VERSION "Think City A306, DBC v2 rev 6 - agg@nvg.org - 2023-03-22"

NS_ :

BS_:
BU_: ZD VCU TPMS RESERVED_FRAMES RCM RAC PCU PAS ESP DiagnosticTester CHG CDCM BMS ABS EDL
BO_ 1091 VCU_Stored_SC_Errors: 8 VCU
   SG_ VCUStoredBeltWarningLightSC : 13|1@0+ (1,0) [0|1] "" Vector__XXX
   SG_ VCUStoredLowSOCSC : 0|1@0+ (1,0) [0|1] "" Vector__XXX
   SG_ VCUStoredRearSeatBuckle2LightSC : 26|1@0+ (1,0) [0|1] "" Vector__XXX
   SG_ VCUStoredReverseLightSC : 9|1@0+ (1,0) [0|1] "" Vector__XXX
   SG_ VCUStoredRadioMuteSC : 33|1@0+ (1,0) [0|1] "" Vector__XXX
   SG_ VCUStoredIllumOutputSC : 21|1@0+ (1,0) [0|1] "" Vector__XXX
   SG_ VCUStoredNeutralLightSC : 8|1@0+ (1,0) [0|1] "" Vector__XXX
   SG_ VCUStoredDriveEnableLightSC : 39|1@0+ (1,0) [0|1] "" Vector__XXX
   SG_ VCUStoredOvertempLightSC : 3|1@0+ (1,0) [0|1] "" Vector__XXX
   SG_ VCUStoredIndicationBarSupplySC : 18|1@0+ (1,0) [0|1] "" Vector__XXX
   SG_ VCUStoredPowerLimitLightSC : 5|1@0+ (1,0) [0|1] "" Vector__XXX
   SG_ VCUStoredTransceiverTXSC : 20|1@0+ (1,0) [0|1] "" Vector__XXX
   SG_ VCUStoredElHazardLightSC : 2|1@0+ (1,0) [0|1] "" Vector__XXX
   SG_ VCUStoredBrakeWarningLightSC : 38|1@0+ (1,0) [0|1] "" Vector__XXX
   SG_ VCUStoredEconomyGaugeSC : 36|1@0+ (1,0) [0|1] "" Vector__XXX
   SG_ VCUStoredTransceiverSupplySC : 32|1@0+ (1,0) [0|1] "" Vector__XXX
   SG_ VCUStoredDischargeRequestSC : 25|1@0+ (1,0) [0|1] "" Vector__XXX
   SG_ VCUStoredCrashLineSC : 17|1@0+ (1,0) [0|1] "" Vector__XXX
   SG_ VCUStoredABSWarningLightSC : 4|1@0+ (1,0) [0|1] "" Vector__XXX
   SG_ VCUStoredImmoLightSC : 19|1@0+ (1,0) [0|1] "" Vector__XXX
   SG_ VCUStoredDriveLightSC : 7|1@0+ (1,0) [0|1] "" Vector__XXX
   SG_ VCUStoredAuxBattLowLightSC : 11|1@0+ (1,0) [0|1] "" Vector__XXX
   SG_ VCUStoredChargeLightSC : 31|1@0+ (1,0) [0|1] "" Vector__XXX
   SG_ VCUStoredTPMSLightSC : 12|1@0+ (1,0) [0|1] "" Vector__XXX
   SG_ VCUStoredSpeedGaugeSC : 28|1@0+ (1,0) [0|1] "" Vector__XXX
   SG_ VCUStoredEconomyLightSC : 6|1@0+ (1,0) [0|1] "" Vector__XXX
   SG_ VCUStoredOnPlugLightSC : 30|1@0+ (1,0) [0|1] "" Vector__XXX
   SG_ VCUStoredChimeLineSC : 34|1@0+ (1,0) [0|1] "" Vector__XXX
   SG_ VCUStoredESPLightSC : 15|1@0+ (1,0) [0|1] "" Vector__XXX
   SG_ VCUStoredSOCGaugeSC : 37|1@0+ (1,0) [0|1] "" Vector__XXX
   SG_ VCUStoredMILLightSC : 1|1@0+ (1,0) [0|1] "" Vector__XXX
   SG_ VCUStoredParkLightSC : 10|1@0+ (1,0) [0|1] "" Vector__XXX
   SG_ VCUStoredAirbagLightSC : 29|1@0+ (1,0) [0|1] "" Vector__XXX
   SG_ VCUStoredIgnitionSpeedSC : 16|1@0+ (1,0) [0|1] "" Vector__XXX
   SG_ VCUStoredRearSeatBuckle1LightSC : 27|1@0+ (1,0) [0|1] "" Vector__XXX

BO_ 1092 VCU_Stored_OC_Errors: 8 VCU
   SG_ VCUStoredImmoLightOC : 19|1@0+ (1,0) [0|1] "" Vector__XXX
   SG_ VCUStoredReverseLightOC : 9|1@0+ (1,0) [0|1] "" Vector__XXX
   SG_ VCUStoredDischargeRequestOC : 25|1@0+ (1,0) [0|1] "" Vector__XXX
   SG_ VCUStoredPowerLimitLightOC : 5|1@0+ (1,0) [0|1] "" Vector__XXX
   SG_ VCUStoredRearSeatBuckle1LightOC : 27|1@0+ (1,0) [0|1] "" Vector__XXX
   SG_ VCUStoredTPMSLightOC : 12|1@0+ (1,0) [0|1] "" Vector__XXX
   SG_ VCUStoredOvertempLightOC : 3|1@0+ (1,0) [0|1] "" Vector__XXX
   SG_ VCUStoredSOCGaugeOC : 37|1@0+ (1,0) [0|1] "" Vector__XXX
   SG_ VCUStoredESPLightOC : 15|1@0+ (1,0) [0|1] "" Vector__XXX
   SG_ VCUStoredCrashLineOC : 17|1@0+ (1,0) [0|1] "" Vector__XXX
   SG_ VCUStoredIndicationBarSupplyOC : 18|1@0+ (1,0) [0|1] "" Vector__XXX
   SG_ VCUStoredEconomyLightOC : 6|1@0+ (1,0) [0|1] "" Vector__XXX
   SG_ VCUStoredAirbagLightOC : 29|1@0+ (1,0) [0|1] "" Vector__XXX
   SG_ VCUStoredEconomyGaugeOC : 36|1@0+ (1,0) [0|1] "" Vector__XXX
   SG_ VCUStoredTransceiverSupplyOC : 32|1@0+ (1,0) [0|1] "" Vector__XXX
   SG_ VCUStoredDriveLightOC : 7|1@0+ (1,0) [0|1] "" Vector__XXX
   SG_ VCUStoredAuxBattLowLightOC : 11|1@0+ (1,0) [0|1] "" Vector__XXX
   SG_ VCUStoredRearSeatBuckle2LightOC : 26|1@0+ (1,0) [0|1] "" Vector__XXX
   SG_ VCUStoredIgnitionSpeedOC : 16|1@0+ (1,0) [0|1] "" Vector__XXX
   SG_ VCUStoredMILLightOC : 1|1@0+ (1,0) [0|1] "" Vector__XXX
   SG_ VCUStoredChimeLineOC : 34|1@0+ (1,0) [0|1] "" Vector__XXX
   SG_ VCUStoredDriveEnableLightOC : 39|1@0+ (1,0) [0|1] "" Vector__XXX
   SG_ VCUStoredLowSOCOC : 0|1@0+ (1,0) [0|1] "" Vector__XXX
   SG_ VCUStoredElHazardLightOC : 2|1@0+ (1,0) [0|1] "" Vector__XXX
   SG_ VCUStoredBrakeWarningLightOC : 38|1@0+ (1,0) [0|1] "" Vector__XXX
   SG_ VCUStoredIllumOutputOC : 21|1@0+ (1,0) [0|1] "" Vector__XXX
   SG_ VCUStoredABSWarningLightOC : 4|1@0+ (1,0) [0|1] "" Vector__XXX
   SG_ VCUStoredTransceiverTXOC : 20|1@0+ (1,0) [0|1] "" Vector__XXX
   SG_ VCUStoredBeltWarningLightOC : 13|1@0+ (1,0) [0|1] "" Vector__XXX
   SG_ VCUStoredSpeedGaugeOC : 28|1@0+ (1,0) [0|1] "" Vector__XXX
   SG_ VCUStoredRadioMuteOC : 33|1@0+ (1,0) [0|1] "" Vector__XXX
   SG_ VCUStoredParkLightOC : 10|1@0+ (1,0) [0|1] "" Vector__XXX
   SG_ VCUStoredNeutralLightOC : 8|1@0+ (1,0) [0|1] "" Vector__XXX
   SG_ VCUStoredChargeLightOC : 31|1@0+ (1,0) [0|1] "" Vector__XXX
   SG_ VCUStoredOnPlugLightOC : 30|1@0+ (1,0) [0|1] "" Vector__XXX

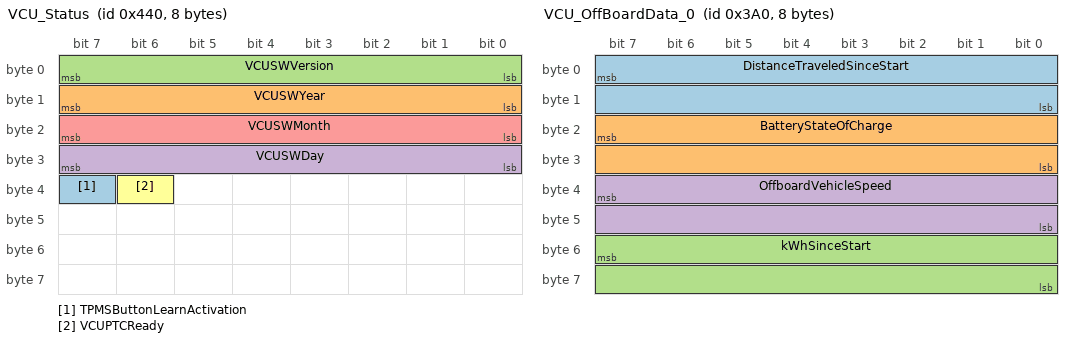
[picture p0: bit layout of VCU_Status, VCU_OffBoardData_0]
BO_ 1088 VCU_Status: 8 VCU
   SG_ TPMSButtonLearnActivation : 39|1@0+ (1,0) [0|1] "" Vector__XXX
   SG_ VCUSWYear : 15|8@0+ (1,0) [0|255] "" Vector__XXX
   SG_ VCUSWVersion : 7|8@0+ (1,0) [0|255] "" Vector__XXX
   SG_ VCUSWDay : 31|8@0+ (1,0) [0|255] "" Vector__XXX
   SG_ VCUSWMonth : 23|8@0+ (1,0) [0|255] "" Vector__XXX
   SG_ VCUPTCReady : 38|1@0+ (1,0) [0|1] "" Vector__XXX

BO_ 1089 VCU_Present_SC_Errors: 8 VCU
   SG_ VCUPresentMILLightSC : 1|1@0+ (1,0) [0|1] "" Vector__XXX
   SG_ VCUPresentImmoLightSC : 19|1@0+ (1,0) [0|1] "" Vector__XXX
   SG_ VCUPresentEconomyLightSC : 6|1@0+ (1,0) [0|1] "" Vector__XXX
   SG_ VCUPresentTransceiverSupplySC : 32|1@0+ (1,0) [0|1] "" Vector__XXX
   SG_ VCUPresentIgnitionSpeedSC : 16|1@0+ (1,0) [0|1] "" Vector__XXX
   SG_ VCUPresentChimeLineSC : 34|1@0+ (1,0) [0|1] "" Vector__XXX
   SG_ VCUPresentElHazardLightSC : 2|1@0+ (1,0) [0|1] "" Vector__XXX
   SG_ VCUPresentBrakeWarningLightSC : 38|1@0+ (1,0) [0|1] "" Vector__XXX
   SG_ VCUPresentRadioMuteSC : 33|1@0+ (1,0) [0|1] "" Vector__XXX
   SG_ VCUPresentSOCGaugeSC : 37|1@0+ (1,0) [0|1] "" Vector__XXX
   SG_ VCUPresentNeutralLightSC : 8|1@0+ (1,0) [0|1] "" Vector__XXX
   SG_ VCUPresentParkLightSC : 10|1@0+ (1,0) [0|1] "" Vector__XXX
   SG_ VCUPresentChargeLightSC : 31|1@0+ (1,0) [0|1] "" Vector__XXX
   SG_ VCUPresentEconomyGaugeSC : 36|1@0+ (1,0) [0|1] "" Vector__XXX
   SG_ VCUPresentCrashLineSC : 17|1@0+ (1,0) [0|1] "" Vector__XXX
   SG_ VCUPresentESPLightSC : 15|1@0+ (1,0) [0|1] "" Vector__XXX
   SG_ VCUPresentTransceiverTXSC : 20|1@0+ (1,0) [0|1] "" Vector__XXX
   SG_ VCUPresentReverseLightSC : 9|1@0+ (1,0) [0|1] "" Vector__XXX
   SG_ VCUPresentAirbagLightSC : 29|1@0+ (1,0) [0|1] "" Vector__XXX
   SG_ VCUPresentIndicationBarSupplySC : 18|1@0+ (1,0) [0|1] "" Vector__XXX
   SG_ VCUPresentDriveLightSC : 7|1@0+ (1,0) [0|1] "" Vector__XXX
   SG_ VCUPresentRearSeatBuckle1LightSC : 27|1@0+ (1,0) [0|1] "" Vector__XXX
   SG_ VCUPresentDischargeRequestSC : 25|1@0+ (1,0) [0|1] "" Vector__XXX
   SG_ VCUPresentAuxBattLowLightSC : 11|1@0+ (1,0) [0|1] "" Vector__XXX
   SG_ VCUPresentDriveEnableLightSC : 39|1@0+ (1,0) [0|1] "" Vector__XXX
   SG_ VCUPresentLowSOCSC : 0|1@0+ (1,0) [0|1] "" Vector__XXX
   SG_ VCUPresentBeltWarningLightSC : 13|1@0+ (1,0) [0|1] "" Vector__XXX
   SG_ VCUPresentSpeedGaugeSC : 28|1@0+ (1,0) [0|1] "" Vector__XXX
   SG_ VCUPresentABSWarningLightSC : 4|1@0+ (1,0) [0|1] "" Vector__XXX
   SG_ VCUPresentOvertempLightSC : 3|1@0+ (1,0) [0|1] "" Vector__XXX
   SG_ VCUPresentOnPlugLightSC : 30|1@0+ (1,0) [0|1] "" Vector__XXX
   SG_ VCUPresentIllumOutputSC : 21|1@0+ (1,0) [0|1] "" Vector__XXX
   SG_ VCUPresentPowerLimitLightSC : 5|1@0+ (1,0) [0|1] "" Vector__XXX
   SG_ VCUPresentTPMSLightSC : 12|1@0+ (1,0) [0|1] "" Vector__XXX
   SG_ VCUPresentRearSeatBuckle2LightSC : 26|1@0+ (1,0) [0|1] "" Vector__XXX

BO_ 1090 VCU_Present_OC_Errors: 8 VCU
   SG_ VCUPresentIndicationBarSupplyOC : 18|1@0+ (1,0) [0|1] "" Vector__XXX
   SG_ VCUPresentLowSOCOC : 0|1@0+ (1,0) [0|1] "" Vector__XXX
   SG_ VCUPresentOvertempLightOC : 3|1@0+ (1,0) [0|1] "" Vector__XXX
   SG_ VCUPresentEconomyLightOC : 6|1@0+ (1,0) [0|1] "" Vector__XXX
   SG_ VCUPresentParkLightOC : 10|1@0+ (1,0) [0|1] "" Vector__XXX
   SG_ VCUPresentRadioMuteOC : 33|1@0+ (1,0) [0|1] "" Vector__XXX
   SG_ VCUPresentElHazardLightOC : 2|1@0+ (1,0) [0|1] "" Vector__XXX
   SG_ VCUPresentBeltWarningLightOC : 13|1@0+ (1,0) [0|1] "" Vector__XXX
   SG_ VCUPresentDriveEnableLightOC : 39|1@0+ (1,0) [0|1] "" Vector__XXX
   SG_ VCUPresentImmoLightOC : 19|1@0+ (1,0) [0|1] "" Vector__XXX
   SG_ VCUPresentAirbagLightOC : 29|1@0+ (1,0) [0|1] "" Vector__XXX
   SG_ VCUPresentSOCGaugeOC : 37|1@0+ (1,0) [0|1] "" Vector__XXX
   SG_ VCUPresentSpeedGaugeOC : 28|1@0+ (1,0) [0|1] "" Vector__XXX
   SG_ VCUPresentRearSeatBuckle2LightOC : 26|1@0+ (1,0) [0|1] "" Vector__XXX
   SG_ VCUPresentReverseLightOC : 9|1@0+ (1,0) [0|1] "" Vector__XXX
   SG_ VCUPresentIllumOutputOC : 21|1@0+ (1,0) [0|1] "" Vector__XXX
   SG_ VCUPresentBrakeWarningLightOC : 38|1@0+ (1,0) [0|1] "" Vector__XXX
   SG_ VCUPresentTransceiverSupplyOC : 32|1@0+ (1,0) [0|1] "" Vector__XXX
   SG_ VCUPresentABSWarningLightOC : 4|1@0+ (1,0) [0|1] "" Vector__XXX
   SG_ VCUPresentTransceiverTXOC : 20|1@0+ (1,0) [0|1] "" Vector__XXX
   SG_ VCUPresentDriveLightOC : 7|1@0+ (1,0) [0|1] "" Vector__XXX
   SG_ VCUPresentPowerLimitLightOC : 5|1@0+ (1,0) [0|1] "" Vector__XXX
   SG_ VCUPresentCrashLineOC : 17|1@0+ (1,0) [0|1] "" Vector__XXX
   SG_ VCUPresentIgnitionSpeedOC : 16|1@0+ (1,0) [0|1] "" Vector__XXX
   SG_ VCUPresentAuxBattLowLightOC : 11|1@0+ (1,0) [0|1] "" Vector__XXX
   SG_ VCUPresentChargeLightOC : 31|1@0+ (1,0) [0|1] "" Vector__XXX
   SG_ VCUPresentOnPlugLightOC : 30|1@0+ (1,0) [0|1] "" Vector__XXX
   SG_ VCUPresentNeutralLightOC : 8|1@0+ (1,0) [0|1] "" Vector__XXX
   SG_ VCUPresentEconomyGaugeOC : 36|1@0+ (1,0) [0|1] "" Vector__XXX
   SG_ VCUPresentChimeLineOC : 34|1@0+ (1,0) [0|1] "" Vector__XXX
   SG_ VCUPresentRearSeatBuckle1LightOC : 27|1@0+ (1,0) [0|1] "" Vector__XXX
   SG_ VCUPresentESPLightOC : 15|1@0+ (1,0) [0|1] "" Vector__XXX
   SG_ VCUPresentTPMSLightOC : 12|1@0+ (1,0) [0|1] "" Vector__XXX
   SG_ VCUPresentDischargeRequestOC : 25|1@0+ (1,0) [0|1] "" Vector__XXX
   SG_ VCUPresentMILLightOC : 1|1@0+ (1,0) [0|1] "" Vector__XXX

BO_ 929 VCU_OffBoardData_1: 8 VCU
   SG_ WarningLightTemperatureActivated : 30|1@0+ (1,0) [0|1] "" Vector__XXX
   SG_ WarningLightAirbagActivated : 28|1@0+ (1,0) [0|1] "" Vector__XXX
   SG_ OnPlugBatteryTemperatureControl : 3|1@0+ (1,0) [0|1] "" Vector__XXX
   SG_ OnPlugPCUChargeEnabled : 15|1@0+ (1,0) [0|1] "" Vector__XXX
   SG_ KeyOnEPOBroken : 9|1@0+ (1,0) [0|1] "" Vector__XXX
   SG_ OnPlugFullChargeRequested : 14|1@0+ (1,0) [0|1] "" Vector__XXX
   SG_ WarningLightTPMSActivated : 20|1@0+ (1,0) [0|1] "" Vector__XXX
   SG_ KeyOnTractionEnabled : 13|1@0+ (1,0) [0|1] "" Vector__XXX
   SG_ WarningLightPowerLimitActivated : 19|1@0+ (1,0) [0|1] "" Vector__XXX
   SG_ KeyOnImmobilizerEnabled : 12|1@0+ (1,0) [0|1] "" Vector__XXX
   SG_ ExternalTemperature : 39|8@0- (0.5,0) [-64|63.5] "degC" Vector__XXX
   SG_ WarningLightESPActivated : 31|1@0+ (1,0) [0|1] "" Vector__XXX
   SG_ KeyOnGearPosition : 27|3@0+ (1,0) [0|7] "" Vector__XXX
   SG_ WarningLightMalfunctionActivated : 29|1@0+ (1,0) [0|1] "" Vector__XXX
   SG_ WarningLightBrakeActivated : 16|1@0+ (1,0) [0|1] "" Vector__XXX
   SG_ OnPlugEndOfCharge : 4|1@0+ (1,0) [0|1] "" Vector__XXX
   SG_ OnPlugBatteryChargeEnabled : 0|1@0+ (1,0) [0|1] "" Vector__XXX
   SG_ WarningLightABSActivated : 17|1@0+ (1,0) [0|1] "" Vector__XXX
   SG_ NominalBatteryCapacity : 47|16@0+ (0.1,0) [0|6553.5] "kWh" Vector__XXX
   SG_ WarningLightLowSOCActivated : 21|1@0+ (1,0) [0|1] "" Vector__XXX
   SG_ OnPlugCharging : 5|1@0+ (1,0) [0|1] "" Vector__XXX
   SG_ OnPlugBatteryEvaluation : 2|1@0+ (1,0) [0|1] "" Vector__XXX
   SG_ KeyOnCrashDetected : 10|1@0+ (1,0) [0|1] "" Vector__XXX
   SG_ KeyOnBatteryDischargeEnabled : 11|1@0+ (1,0) [0|1] "" Vector__XXX
   SG_ WarningLightElHazardActivated : 18|1@0+ (1,0) [0|1] "" Vector__XXX
   SG_ VehicleState : 7|2@0+ (1,0) [0|3] "" Vector__XXX
   SG_ OnPlugChargerEnabled : 1|1@0+ (1,0) [0|1] "" Vector__XXX

BO_ 928 VCU_OffBoardData_0: 8 VCU
   SG_ DistanceTraveledSinceStart : 7|16@0+ (0.1,0) [0|6553.5] "km" Vector__XXX
   SG_ BatteryStateOfCharge : 23|16@0+ (0.1,0) [0|6553.5] "%" Vector__XXX
   SG_ kWhSinceStart : 55|16@0+ (0.01,0) [0|655.35] "kWh" Vector__XXX
   SG_ OffboardVehicleSpeed : 39|16@0+ (0.1,0) [0|6553.5] "km/h" Vector__XXX

BO_ 592 VCU_Immo: 8 VCU
   SG_ MoreThanMaxError : 19|1@0+ (1,0) [0|1] "" PCU
   SG_ ChallengeResponseActive : 1|1@0+ (1,0) [0|1] "" PCU
   SG_ AntennaError : 17|1@0+ (1,0) [0|1] "" PCU
   SG_ TransponderError : 16|1@0+ (1,0) [0|1] "" PCU
   SG_ ChallengeMissingError : 27|1@0+ (1,0) [0|1] "" PCU
   SG_ PartialKeyCodeError : 31|1@0+ (1,0) [0|1] "" PCU
   SG_ RequestID : 2|1@0+ (1,0) [0|1] "" PCU
   SG_ AntiscanError : 20|1@0+ (1,0) [0|1] "" PCU
   SG_ MismatchError : 26|1@0+ (1,0) [0|1] "" PCU
   SG_ LEDIndication : 7|3@0+ (1,0) [0|7] "" PCU
   SG_ NoCommunicationError : 18|1@0+ (1,0) [0|1] "" PCU
   SG_ KeyStatus : 4|2@0+ (1,0) [0|3] "" PCU
   SG_ SecurityIDRefuseError : 25|1@0+ (1,0) [0|1] "" PCU
   SG_ LessThanMinError : 28|1@0+ (1,0) [0|1] "" PCU
   SG_ SecurityIDNotProgrammedError : 24|1@0+ (1,0) [0|1] "" PCU
   SG_ SecurityIDMissingError : 29|1@0+ (1,0) [0|1] "" PCU
   SG_ UnprogrammedError : 30|1@0+ (1,0) [0|1] "" PCU
   SG_ NumberProgrammedKeys : 23|3@0+ (1,0) [0|7] "" Vector__XXX
   SG_ ChallengeResponse : 39|32@0+ (1,0) [0|4.29497e+09] "" PCU

BO_ 2001 VCU_Diagnostic: 8 VCU

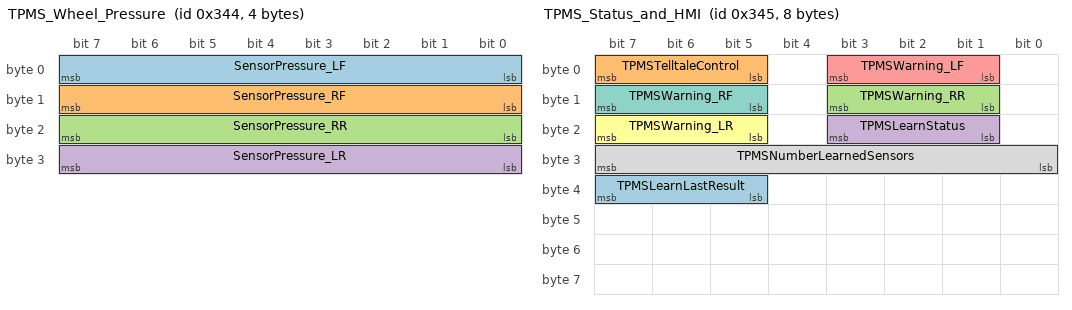
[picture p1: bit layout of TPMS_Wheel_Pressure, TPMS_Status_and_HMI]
BO_ 836 TPMS_Wheel_Pressure: 4 TPMS
   SG_ SensorPressure_LF : 7|8@0+ (0.025,0) [0|6.375] "bar" Vector__XXX
   SG_ SensorPressure_RF : 15|8@0+ (0.025,0) [0|6.375] "bar" Vector__XXX
   SG_ SensorPressure_RR : 23|8@0+ (0.025,0) [0|6.375] "bar" Vector__XXX
   SG_ SensorPressure_LR : 31|8@0+ (0.025,0) [0|6.375] "bar" Vector__XXX

BO_ 837 TPMS_Status_and_HMI: 8 TPMS
   SG_ TPMSLearnLastResult : 39|3@0+ (1,0) [0|7] "" Vector__XXX
   SG_ TPMSTelltaleControl : 7|3@0+ (1,0) [0|7] "" Vector__XXX
   SG_ TPMSWarning_RR : 11|3@0+ (1,0) [0|7] "" Vector__XXX
   SG_ TPMSLearnStatus : 19|3@0+ (1,0) [0|7] "" Vector__XXX
   SG_ TPMSWarning_LF : 3|3@0+ (1,0) [0|7] "" Vector__XXX
   SG_ TPMSWarning_LR : 23|3@0+ (1,0) [0|7] "" Vector__XXX
   SG_ TPMSWarning_RF : 15|3@0+ (1,0) [0|7] "" Vector__XXX
   SG_ TPMSNumberLearnedSensors : 31|8@0+ (1,0) [0|255] "" Vector__XXX

BO_ 1922 TPMS_Diagnostic: 8 TPMS

BO_ 838 TPMS_Debug: 8 TPMS

BO_ 1941 Reserver_104: 8 RESERVED_FRAMES

BO_ 1525 Reserved_99: 8 RESERVED_FRAMES

BO_ 1493 Reserved_98: 8 RESERVED_FRAMES

BO_ 1631 Reserved_97: 8 RESERVED_FRAMES

BO_ 1630 Reserved_96: 8 RESERVED_FRAMES

BO_ 1629 Reserved_95: 8 RESERVED_FRAMES

BO_ 1628 Reserved_94: 8 RESERVED_FRAMES

BO_ 1627 Reserved_93: 8 RESERVED_FRAMES

BO_ 1626 Reserved_92: 8 RESERVED_FRAMES

BO_ 1625 Reserved_91: 8 RESERVED_FRAMES

BO_ 1624 Reserved_90: 8 RESERVED_FRAMES

BO_ 1623 Reserved_89: 8 RESERVED_FRAMES

BO_ 1622 Reserved_88: 8 RESERVED_FRAMES

BO_ 1621 Reserved_87: 8 RESERVED_FRAMES

BO_ 1620 Reserved_86: 8 RESERVED_FRAMES

BO_ 1619 Reserved_85: 8 RESERVED_FRAMES

BO_ 1618 Reserved_84: 8 RESERVED_FRAMES

BO_ 1617 Reserved_83: 8 RESERVED_FRAMES

BO_ 1616 Reserved_82: 8 RESERVED_FRAMES

BO_ 1615 Reserved_81: 8 RESERVED_FRAMES

BO_ 1614 Reserved_80: 8 RESERVED_FRAMES

BO_ 645 Reserved_8: 8 RESERVED_FRAMES

BO_ 1613 Reserved_79: 8 RESERVED_FRAMES

BO_ 1612 Reserved_78: 8 RESERVED_FRAMES

BO_ 1611 Reserved_77: 8 RESERVED_FRAMES

BO_ 1610 Reserved_76: 8 RESERVED_FRAMES

BO_ 1609 Reserved_75: 8 RESERVED_FRAMES

BO_ 1608 Reserved_74: 8 ZD

BO_ 1607 Reserved_73: 8 RESERVED_FRAMES

BO_ 1606 Reserved_72: 8 BMS

BO_ 1605 Reserved_71: 8 RESERVED_FRAMES

BO_ 1604 Reserved_70: 8 BMS

BO_ 513 Reserved_7: 8 RESERVED_FRAMES

BO_ 1603 Reserved_69: 8 RESERVED_FRAMES

BO_ 1602 Reserved_68: 8 BMS

BO_ 1601 Reserved_67: 8 RESERVED_FRAMES

BO_ 1600 Reserved_66: 8 RESERVED_FRAMES

BO_ 1584 Reserved_65: 8 RESERVED_FRAMES

BO_ 831 Reserved_64: 8 RESERVED_FRAMES

BO_ 830 Reserved_63: 8 RESERVED_FRAMES

BO_ 829 Reserved_62: 8 RESERVED_FRAMES

BO_ 828 Reserved_61: 8 RESERVED_FRAMES

BO_ 827 Reserved_60: 8 RESERVED_FRAMES

BO_ 512 Reserved_6: 8 RESERVED_FRAMES

BO_ 826 Reserved_59: 8 RESERVED_FRAMES

BO_ 825 Reserved_58: 8 RESERVED_FRAMES

BO_ 824 Reserved_57: 8 RESERVED_FRAMES

BO_ 823 Reserved_56: 8 RESERVED_FRAMES

BO_ 822 Reserved_55: 8 RESERVED_FRAMES

BO_ 821 Reserved_54: 8 RESERVED_FRAMES

BO_ 820 Reserved_53: 8 RESERVED_FRAMES

BO_ 819 Reserved_52: 8 RESERVED_FRAMES

BO_ 818 Reserved_51: 8 RESERVED_FRAMES

BO_ 817 Reserved_50: 8 RESERVED_FRAMES

BO_ 1568 Reserved_5: 8 RESERVED_FRAMES

BO_ 816 Reserved_49: 8 RESERVED_FRAMES

BO_ 815 Reserved_48: 8 RESERVED_FRAMES

BO_ 814 Reserved_47: 8 RESERVED_FRAMES

BO_ 813 Reserved_46: 8 RESERVED_FRAMES

BO_ 812 Reserved_45: 8 RESERVED_FRAMES

BO_ 811 Reserved_44: 8 RESERVED_FRAMES

BO_ 810 Reserved_43: 8 RESERVED_FRAMES

BO_ 809 Reserved_42: 8 RESERVED_FRAMES

BO_ 808 Reserved_41: 8 RESERVED_FRAMES

BO_ 1892 Reserved_401: 8 RESERVED_FRAMES

BO_ 1888 Reserved_400: 8 RESERVED_FRAMES

BO_ 807 Reserved_40: 8 RESERVED_FRAMES

BO_ 1072 Reserved_4: 8 RESERVED_FRAMES

BO_ 1034 Reserved_399: 8 RESERVED_FRAMES

BO_ 1585 Reserved_398: 8 RESERVED_FRAMES

BO_ 1569 Reserved_397: 8 RESERVED_FRAMES

BO_ 857 Reserved_392: 8 RESERVED_FRAMES

BO_ 1567 Reserved_391: 8 RESERVED_FRAMES

BO_ 1566 Reserved_390: 8 RESERVED_FRAMES

BO_ 806 Reserved_39: 8 RESERVED_FRAMES

BO_ 1565 Reserved_389: 8 RESERVED_FRAMES

BO_ 1564 Reserved_388: 8 RESERVED_FRAMES

BO_ 1563 Reserved_387: 8 RESERVED_FRAMES

BO_ 1562 Reserved_386: 8 RESERVED_FRAMES

BO_ 1561 Reserved_385: 8 RESERVED_FRAMES

BO_ 1560 Reserved_384: 8 RESERVED_FRAMES

BO_ 1559 Reserved_383: 8 RESERVED_FRAMES

BO_ 1558 Reserved_382: 8 RESERVED_FRAMES

BO_ 1557 Reserved_381: 8 RESERVED_FRAMES

BO_ 1556 Reserved_380: 8 RESERVED_FRAMES

BO_ 805 Reserved_38: 8 RESERVED_FRAMES

BO_ 1555 Reserved_379: 8 RESERVED_FRAMES

BO_ 1554 Reserved_378: 8 RESERVED_FRAMES

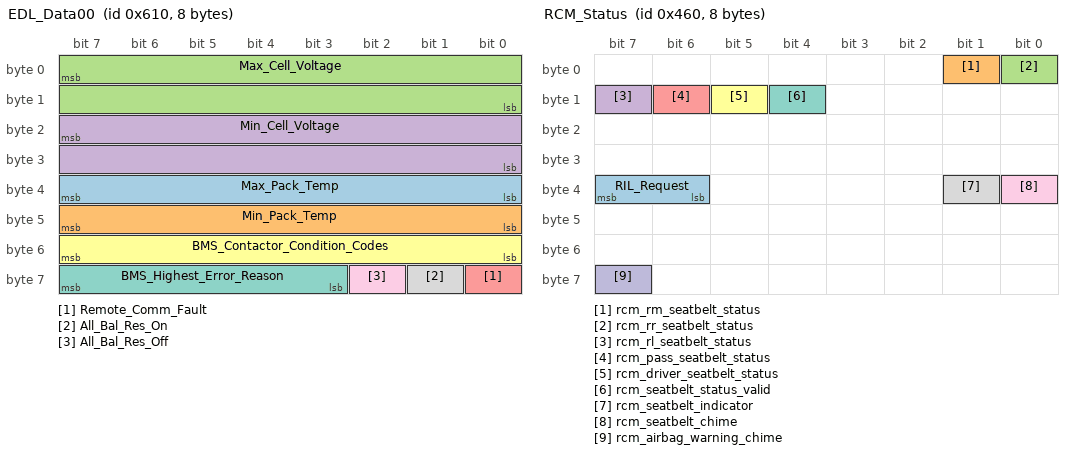
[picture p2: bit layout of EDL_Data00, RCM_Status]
BO_ 1552 EDL_Data00: 8 EDL
   SG_ Max_Pack_Temp : 39|8@0+ (1,0) [0|255] "_Celsius" Vector__XXX
   SG_ Min_Pack_Temp : 47|8@0+ (1,0) [0|255] "_Celsius" Vector__XXX
   SG_ Max_Cell_Voltage : 7|16@0+ (0.00244141,0) [0|1] "_Volts" Vector__XXX
   SG_ Min_Cell_Voltage : 23|16@0+ (0.00244141,0) [0|1] "_Volts" Vector__XXX
   SG_ Remote_Comm_Fault : 56|1@0+ (1,0) [0|1] "" Vector__XXX
   SG_ BMS_Contactor_Condition_Codes : 55|8@0+ (1,0) [0|256] "" Vector__XXX
   SG_ BMS_Highest_Error_Reason : 63|5@0+ (1,0) [0|256] "_(dec)" Vector__XXX
   SG_ All_Bal_Res_On : 57|1@0+ (1,0) [0|1] "" Vector__XXX
   SG_ All_Bal_Res_Off : 58|1@0+ (1,0) [0|1] "" Vector__XXX

BO_ 1551 Reserved_374: 8 RESERVED_FRAMES

BO_ 1550 Reserved_373: 8 RESERVED_FRAMES

BO_ 1549 Reserved_372: 8 RESERVED_FRAMES

BO_ 1548 Reserved_371: 8 RESERVED_FRAMES

BO_ 1547 Reserved_370: 8 RESERVED_FRAMES

BO_ 804 Reserved_37: 8 RESERVED_FRAMES

BO_ 1546 Reserved_369: 8 RESERVED_FRAMES

BO_ 1545 Reserved_368: 8 RESERVED_FRAMES

BO_ 1544 Reserved_367: 8 RESERVED_FRAMES

BO_ 1543 Reserved_366: 8 RESERVED_FRAMES

BO_ 1542 Reserved_365: 8 RESERVED_FRAMES

BO_ 1541 Reserved_364: 8 RESERVED_FRAMES

BO_ 1540 Reserved_363: 8 RESERVED_FRAMES

BO_ 1539 Reserved_362: 8 RESERVED_FRAMES

BO_ 1538 Reserved_361: 8 RESERVED_FRAMES

BO_ 1537 Reserved_360: 8 RESERVED_FRAMES

BO_ 803 Reserved_36: 8 RESERVED_FRAMES

BO_ 1536 Reserved_359: 8 RESERVED_FRAMES

BO_ 1535 Reserved_358: 8 RESERVED_FRAMES

BO_ 1534 Reserved_357: 8 RESERVED_FRAMES

BO_ 1533 Reserved_356: 8 RESERVED_FRAMES

BO_ 1532 Reserved_355: 8 RESERVED_FRAMES

BO_ 1531 Reserved_354: 8 RESERVED_FRAMES

BO_ 1530 Reserved_353: 8 RESERVED_FRAMES

BO_ 1529 Reserved_352: 8 RESERVED_FRAMES

BO_ 1528 Reserved_351: 8 RESERVED_FRAMES

BO_ 1527 Reserved_350: 8 RESERVED_FRAMES

BO_ 802 Reserved_35: 8 RESERVED_FRAMES

BO_ 1526 Reserved_349: 8 RESERVED_FRAMES

BO_ 1524 Reserved_348: 8 RESERVED_FRAMES

BO_ 1523 Reserved_347: 8 RESERVED_FRAMES

BO_ 1522 Reserved_346: 8 RESERVED_FRAMES

BO_ 1521 Reserved_345: 8 RESERVED_FRAMES

BO_ 1520 Reserved_344: 8 RESERVED_FRAMES

BO_ 1519 Reserved_343: 8 RESERVED_FRAMES

BO_ 1518 Reserved_342: 8 RESERVED_FRAMES

BO_ 1517 Reserved_341: 8 RESERVED_FRAMES

BO_ 1516 Reserved_340: 8 RESERVED_FRAMES

BO_ 801 Reserved_34: 8 RESERVED_FRAMES

BO_ 1515 Reserved_339: 8 RESERVED_FRAMES

BO_ 1514 Reserved_338: 8 RESERVED_FRAMES

BO_ 1513 Reserved_337: 8 RESERVED_FRAMES

BO_ 1512 Reserved_336: 8 RESERVED_FRAMES

BO_ 1511 Reserved_335: 8 RESERVED_FRAMES

BO_ 1510 Reserved_334: 8 RESERVED_FRAMES

BO_ 1509 Reserved_333: 8 RESERVED_FRAMES

BO_ 1508 Reserved_332: 8 RESERVED_FRAMES

BO_ 1507 Reserved_331: 8 RESERVED_FRAMES

BO_ 1506 Reserved_330: 8 RESERVED_FRAMES

BO_ 800 Reserved_33: 8 RESERVED_FRAMES

BO_ 1505 Reserved_329: 8 RESERVED_FRAMES

BO_ 1504 Reserved_328: 8 RESERVED_FRAMES

BO_ 1503 Reserved_327: 8 RESERVED_FRAMES

BO_ 1502 Reserved_326: 8 RESERVED_FRAMES

BO_ 1501 Reserved_325: 8 RESERVED_FRAMES

BO_ 1500 Reserved_324: 8 RESERVED_FRAMES

BO_ 1499 Reserved_323: 8 RESERVED_FRAMES

BO_ 1498 Reserved_322: 8 RESERVED_FRAMES

BO_ 1497 Reserved_321: 8 RESERVED_FRAMES

BO_ 1496 Reserved_320: 8 RESERVED_FRAMES

BO_ 799 Reserved_32: 8 RESERVED_FRAMES

BO_ 1495 Reserved_319: 8 RESERVED_FRAMES

BO_ 1494 Reserved_318: 8 RESERVED_FRAMES

BO_ 1492 Reserved_317: 8 RESERVED_FRAMES

BO_ 1491 Reserved_316: 8 RESERVED_FRAMES

BO_ 1490 Reserved_315: 8 RESERVED_FRAMES

BO_ 1489 Reserved_314: 8 RESERVED_FRAMES

BO_ 1488 Reserved_313: 8 RESERVED_FRAMES

BO_ 1487 Reserved_312: 8 RESERVED_FRAMES

BO_ 1486 Reserved_311: 8 RESERVED_FRAMES

BO_ 1485 Reserved_310: 8 RESERVED_FRAMES

BO_ 798 Reserved_31: 8 RESERVED_FRAMES

BO_ 1484 Reserved_309: 8 RESERVED_FRAMES

BO_ 1483 Reserved_308: 8 RESERVED_FRAMES

BO_ 1482 Reserved_307: 8 RESERVED_FRAMES

BO_ 1481 Reserved_306: 8 RESERVED_FRAMES

BO_ 1480 Reserved_305: 8 RESERVED_FRAMES

BO_ 1479 Reserved_304: 8 RESERVED_FRAMES

BO_ 1478 Reserved_303: 8 RESERVED_FRAMES

BO_ 1477 Reserved_302: 8 RESERVED_FRAMES

BO_ 1476 Reserved_301: 8 RESERVED_FRAMES

BO_ 1475 Reserved_300: 8 RESERVED_FRAMES

BO_ 797 Reserved_30: 8 RESERVED_FRAMES

BO_ 560 Reserved_3: 8 RESERVED_FRAMES

BO_ 1474 Reserved_299: 8 RESERVED_FRAMES

BO_ 1473 Reserved_298: 8 RESERVED_FRAMES

BO_ 1472 Reserved_297: 8 RESERVED_FRAMES

BO_ 1471 Reserved_296: 8 RESERVED_FRAMES

BO_ 1470 Reserved_295: 8 RESERVED_FRAMES

BO_ 1469 Reserved_294: 8 RESERVED_FRAMES

BO_ 1468 Reserved_293: 8 RESERVED_FRAMES

BO_ 1467 Reserved_292: 8 RESERVED_FRAMES

BO_ 1466 Reserved_291: 8 RESERVED_FRAMES

BO_ 1465 Reserved_290: 8 RESERVED_FRAMES

BO_ 796 Reserved_29: 8 RESERVED_FRAMES

BO_ 1464 Reserved_289: 8 RESERVED_FRAMES

BO_ 1463 Reserved_288: 8 RESERVED_FRAMES

BO_ 1462 Reserved_287: 8 RESERVED_FRAMES

BO_ 1461 Reserved_286: 8 RESERVED_FRAMES

BO_ 1460 Reserved_285: 8 RESERVED_FRAMES

BO_ 1459 Reserved_284: 8 RESERVED_FRAMES

BO_ 1458 Reserved_283: 8 RESERVED_FRAMES

BO_ 1457 Reserved_282: 8 RESERVED_FRAMES

BO_ 1456 Reserved_281: 8 RESERVED_FRAMES

BO_ 1455 Reserved_280: 8 RESERVED_FRAMES

BO_ 795 Reserved_28: 8 RESERVED_FRAMES

BO_ 1454 Reserved_279: 8 RESERVED_FRAMES

BO_ 1453 Reserved_278: 8 RESERVED_FRAMES

BO_ 1452 Reserved_277: 8 RESERVED_FRAMES

BO_ 1451 Reserved_276: 8 RESERVED_FRAMES

BO_ 1450 Reserved_275: 8 RESERVED_FRAMES

BO_ 1449 Reserved_274: 8 RESERVED_FRAMES

BO_ 1448 Reserved_273: 8 RESERVED_FRAMES

BO_ 1447 Reserved_272: 8 RESERVED_FRAMES

BO_ 1446 Reserved_271: 8 RESERVED_FRAMES

BO_ 1445 Reserved_270: 8 RESERVED_FRAMES

BO_ 794 Reserved_27: 8 RESERVED_FRAMES

BO_ 1444 Reserved_269: 8 RESERVED_FRAMES

BO_ 1443 Reserved_268: 8 RESERVED_FRAMES

BO_ 1442 Reserved_267: 8 RESERVED_FRAMES

BO_ 1441 Reserved_266: 8 RESERVED_FRAMES

BO_ 1440 Reserved_265: 8 RESERVED_FRAMES

BO_ 1439 Reserved_264: 8 RESERVED_FRAMES

BO_ 1438 Reserved_263: 8 RESERVED_FRAMES

BO_ 1437 Reserved_262: 8 RESERVED_FRAMES

BO_ 1436 Reserved_261: 8 RESERVED_FRAMES

BO_ 1435 Reserved_260: 8 RESERVED_FRAMES

BO_ 793 Reserved_26: 8 RESERVED_FRAMES

BO_ 1434 Reserved_259: 8 RESERVED_FRAMES

BO_ 1433 Reserved_258: 8 RESERVED_FRAMES

BO_ 1432 Reserved_257: 8 RESERVED_FRAMES

BO_ 1431 Reserved_256: 8 RESERVED_FRAMES

BO_ 1430 Reserved_255: 8 RESERVED_FRAMES

BO_ 1429 Reserved_254: 8 RESERVED_FRAMES

BO_ 1428 Reserved_253: 8 RESERVED_FRAMES

BO_ 1427 Reserved_252: 8 RESERVED_FRAMES

BO_ 1426 Reserved_251: 8 RESERVED_FRAMES

BO_ 1425 Reserved_250: 8 RESERVED_FRAMES

BO_ 792 Reserved_25: 8 RESERVED_FRAMES

BO_ 1424 Reserved_249: 8 RESERVED_FRAMES

BO_ 1423 Reserved_248: 8 RESERVED_FRAMES

BO_ 1422 Reserved_247: 8 RESERVED_FRAMES

BO_ 1421 Reserved_246: 8 RESERVED_FRAMES

BO_ 1420 Reserved_245: 8 RESERVED_FRAMES

BO_ 1419 Reserved_244: 8 RESERVED_FRAMES

BO_ 1418 Reserved_243: 8 RESERVED_FRAMES

BO_ 1417 Reserved_242: 8 RESERVED_FRAMES

BO_ 1416 Reserved_241: 8 RESERVED_FRAMES

BO_ 1415 Reserved_240: 8 RESERVED_FRAMES

BO_ 791 Reserved_24: 8 RESERVED_FRAMES

BO_ 1414 Reserved_239: 8 RESERVED_FRAMES

BO_ 1413 Reserved_238: 8 RESERVED_FRAMES

BO_ 1412 Reserved_237: 8 RESERVED_FRAMES

BO_ 1411 Reserved_236: 8 RESERVED_FRAMES

BO_ 1410 Reserved_235: 8 RESERVED_FRAMES

BO_ 1409 Reserved_234: 8 RESERVED_FRAMES

BO_ 1408 Reserved_233: 8 RESERVED_FRAMES

BO_ 1407 Reserved_232: 8 RESERVED_FRAMES

BO_ 1406 Reserved_231: 8 RESERVED_FRAMES

BO_ 1405 Reserved_230: 8 RESERVED_FRAMES

BO_ 790 Reserved_23: 8 RESERVED_FRAMES

BO_ 1404 Reserved_229: 8 RESERVED_FRAMES

BO_ 1403 Reserved_228: 8 RESERVED_FRAMES

BO_ 1402 Reserved_227: 8 RESERVED_FRAMES

BO_ 1401 Reserved_226: 8 RESERVED_FRAMES

BO_ 1400 Reserved_225: 8 RESERVED_FRAMES

BO_ 1399 Reserved_224: 8 RESERVED_FRAMES

BO_ 1398 Reserved_223: 8 RESERVED_FRAMES

BO_ 1397 Reserved_222: 8 RESERVED_FRAMES

BO_ 1396 Reserved_221: 8 RESERVED_FRAMES

BO_ 1395 Reserved_220: 8 RESERVED_FRAMES

BO_ 789 Reserved_22: 8 RESERVED_FRAMES

BO_ 1394 Reserved_219: 8 RESERVED_FRAMES

BO_ 1393 Reserved_218: 8 RESERVED_FRAMES

BO_ 1392 Reserved_217: 8 RESERVED_FRAMES

BO_ 1391 Reserved_216: 8 RESERVED_FRAMES

BO_ 1390 Reserved_215: 8 RESERVED_FRAMES

BO_ 1389 Reserved_214: 8 RESERVED_FRAMES

BO_ 1388 Reserved_213: 8 RESERVED_FRAMES

BO_ 1387 Reserved_212: 8 RESERVED_FRAMES

BO_ 1386 Reserved_211: 8 RESERVED_FRAMES

BO_ 1385 Reserved_210: 8 RESERVED_FRAMES

BO_ 788 Reserved_21: 8 RESERVED_FRAMES

BO_ 1384 Reserved_209: 8 RESERVED_FRAMES

BO_ 1383 Reserved_208: 8 RESERVED_FRAMES

BO_ 1382 Reserved_207: 8 RESERVED_FRAMES

BO_ 1381 Reserved_206: 8 RESERVED_FRAMES

BO_ 1380 Reserved_205: 8 RESERVED_FRAMES

BO_ 1379 Reserved_204: 8 RESERVED_FRAMES

BO_ 1378 Reserved_203: 8 RESERVED_FRAMES

BO_ 1377 Reserved_202: 8 RESERVED_FRAMES

BO_ 1376 Reserved_201: 8 RESERVED_FRAMES

BO_ 1375 Reserved_200: 8 RESERVED_FRAMES

BO_ 787 Reserved_20: 8 RESERVED_FRAMES

BO_ 144 Reserved_2: 8 RESERVED_FRAMES

BO_ 1374 Reserved_199: 8 RESERVED_FRAMES

BO_ 1373 Reserved_198: 8 RESERVED_FRAMES

BO_ 1372 Reserved_197: 8 RESERVED_FRAMES

BO_ 1371 Reserved_196: 8 RESERVED_FRAMES

BO_ 1370 Reserved_195: 8 RESERVED_FRAMES

BO_ 1369 Reserved_194: 8 RESERVED_FRAMES

BO_ 1368 Reserved_193: 8 RESERVED_FRAMES

BO_ 1367 Reserved_192: 8 RESERVED_FRAMES

BO_ 1366 Reserved_191: 8 RESERVED_FRAMES

BO_ 1365 Reserved_190: 8 RESERVED_FRAMES

BO_ 786 Reserved_19: 8 RESERVED_FRAMES

BO_ 1364 Reserved_189: 8 RESERVED_FRAMES

BO_ 1363 Reserved_188: 8 RESERVED_FRAMES

BO_ 1362 Reserved_187: 8 RESERVED_FRAMES

BO_ 1361 Reserved_186: 8 RESERVED_FRAMES

BO_ 1360 Reserved_185: 8 RESERVED_FRAMES

BO_ 1359 Reserved_184: 8 RESERVED_FRAMES

BO_ 1358 Reserved_183: 8 RESERVED_FRAMES

BO_ 1357 Reserved_182: 8 RESERVED_FRAMES

BO_ 1356 Reserved_181: 8 RESERVED_FRAMES

BO_ 1355 Reserved_180: 8 RESERVED_FRAMES

BO_ 1354 Reserved_179: 8 RESERVED_FRAMES

BO_ 1353 Reserved_178: 8 RESERVED_FRAMES

BO_ 1352 Reserved_177: 8 RESERVED_FRAMES

BO_ 1351 Reserved_176: 8 RESERVED_FRAMES

BO_ 1350 Reserved_175: 8 RESERVED_FRAMES

BO_ 1349 Reserved_174: 8 RESERVED_FRAMES

BO_ 1348 Reserved_173: 8 RESERVED_FRAMES

BO_ 1347 Reserved_172: 8 RESERVED_FRAMES

BO_ 1346 Reserved_171: 8 RESERVED_FRAMES

BO_ 1345 Reserved_170: 8 RESERVED_FRAMES

BO_ 1344 Reserved_169: 8 RESERVED_FRAMES

BO_ 1343 Reserved_168: 8 RESERVED_FRAMES

BO_ 1342 Reserved_167: 8 RESERVED_FRAMES

BO_ 1341 Reserved_166: 8 RESERVED_FRAMES

BO_ 1340 Reserved_165: 8 RESERVED_FRAMES

BO_ 1339 Reserved_164: 8 RESERVED_FRAMES

BO_ 1338 Reserved_163: 8 RESERVED_FRAMES

BO_ 1337 Reserved_162: 8 RESERVED_FRAMES

BO_ 1336 Reserved_161: 8 RESERVED_FRAMES

BO_ 1335 Reserved_160: 8 RESERVED_FRAMES

BO_ 781 Reserved_16: 8 RESERVED_FRAMES

BO_ 1334 Reserved_159: 8 RESERVED_FRAMES

BO_ 1333 Reserved_158: 8 RESERVED_FRAMES

BO_ 1332 Reserved_157: 8 RESERVED_FRAMES

BO_ 1331 Reserved_156: 8 RESERVED_FRAMES

BO_ 1330 Reserved_155: 8 RESERVED_FRAMES

BO_ 1329 Reserved_154: 8 RESERVED_FRAMES

BO_ 1328 Reserved_153: 8 RESERVED_FRAMES

BO_ 1327 Reserved_152: 8 RESERVED_FRAMES

BO_ 1326 Reserved_151: 8 RESERVED_FRAMES

BO_ 1325 Reserved_150: 8 RESERVED_FRAMES

BO_ 780 Reserved_15: 8 RESERVED_FRAMES

BO_ 1324 Reserved_149: 8 RESERVED_FRAMES

BO_ 1323 Reserved_148: 8 RESERVED_FRAMES

BO_ 1322 Reserved_147: 8 RESERVED_FRAMES

BO_ 1321 Reserved_146: 8 RESERVED_FRAMES

BO_ 1320 Reserved_145: 8 RESERVED_FRAMES

BO_ 1319 Reserved_144: 8 RESERVED_FRAMES

BO_ 1318 Reserved_143: 8 RESERVED_FRAMES

BO_ 1317 Reserved_142: 8 RESERVED_FRAMES

BO_ 1316 Reserved_141: 8 RESERVED_FRAMES

BO_ 1315 Reserved_140: 8 RESERVED_FRAMES

BO_ 779 Reserved_14: 8 RESERVED_FRAMES

BO_ 1314 Reserved_139: 8 RESERVED_FRAMES

BO_ 1313 Reserved_138: 8 RESERVED_FRAMES

BO_ 1312 Reserved_137: 8 RESERVED_FRAMES

BO_ 1311 Reserved_136: 8 RESERVED_FRAMES

BO_ 1310 Reserved_135: 8 RESERVED_FRAMES

BO_ 1309 Reserved_134: 8 RESERVED_FRAMES

BO_ 1308 Reserved_133: 8 RESERVED_FRAMES

BO_ 1307 Reserved_132: 8 RESERVED_FRAMES

BO_ 1306 Reserved_131: 8 RESERVED_FRAMES

BO_ 1305 Reserved_130: 8 RESERVED_FRAMES

BO_ 1304 Reserved_129: 8 RESERVED_FRAMES

BO_ 1303 Reserved_128: 8 RESERVED_FRAMES

BO_ 1302 Reserved_127: 8 RESERVED_FRAMES

BO_ 1301 Reserved_126: 8 RESERVED_FRAMES

BO_ 1300 Reserved_125: 8 RESERVED_FRAMES

BO_ 1299 Reserved_124: 8 RESERVED_FRAMES

BO_ 1298 Reserved_123: 8 RESERVED_FRAMES

BO_ 1297 Reserved_122: 8 RESERVED_FRAMES

BO_ 1296 Reserved_121: 8 RESERVED_FRAMES

BO_ 1295 Reserved_120: 8 RESERVED_FRAMES

BO_ 1294 Reserved_119: 8 RESERVED_FRAMES

BO_ 1293 Reserved_118: 8 RESERVED_FRAMES

BO_ 1292 Reserved_117: 8 RESERVED_FRAMES

BO_ 1291 Reserved_116: 8 RESERVED_FRAMES

BO_ 1290 Reserved_115: 8 RESERVED_FRAMES

BO_ 1289 Reserved_114: 8 RESERVED_FRAMES

BO_ 1288 Reserved_113: 8 RESERVED_FRAMES

BO_ 1287 Reserved_112: 8 RESERVED_FRAMES

BO_ 1286 Reserved_111: 8 RESERVED_FRAMES

BO_ 1285 Reserved_110: 8 RESERVED_FRAMES

BO_ 1284 Reserved_109: 8 RESERVED_FRAMES

BO_ 1283 Reserved_108: 8 RESERVED_FRAMES

BO_ 1282 Reserved_107: 8 RESERVED_FRAMES

BO_ 1281 Reserved_106: 8 RESERVED_FRAMES

BO_ 1280 Reserved_105: 8 RESERVED_FRAMES

BO_ 1909 Reserved_103: 8 RESERVED_FRAMES

BO_ 1906 Reserved_102: 8 RESERVED_FRAMES

BO_ 146 Reserved_101: 8 RESERVED_FRAMES

BO_ 520 Reserved_100: 8 RESERVED_FRAMES

BO_ 128 Reserved_1: 8 RESERVED_FRAMES

BO_ 1120 RCM_Status: 8 RCM
   SG_ RIL_Request : 39|2@0+ (1,0) [0|3] "" RAC
   SG_ rcm_rm_seatbelt_status : 1|1@0+ (1,0) [0|1] "" Vector__XXX
   SG_ rcm_rr_seatbelt_status : 0|1@0+ (1,0) [0|1] "" Vector__XXX
   SG_ rcm_rl_seatbelt_status : 15|1@0+ (1,0) [0|1] "" Vector__XXX
   SG_ rcm_pass_seatbelt_status : 14|1@0+ (1,0) [0|1] "" Vector__XXX
   SG_ rcm_driver_seatbelt_status : 13|1@0+ (1,0) [0|1] "" Vector__XXX
   SG_ rcm_seatbelt_status_valid : 12|1@0+ (1,0) [0|1] "" Vector__XXX
   SG_ rcm_seatbelt_indicator : 33|1@0+ (1,0) [0|1] "" Vector__XXX
   SG_ rcm_seatbelt_chime : 32|1@0+ (1,0) [0|1] "" Vector__XXX
   SG_ rcm_airbag_warning_chime : 63|1@0+ (1,0) [0|1] "" Vector__XXX

BO_ 35 RCM_Event: 1 RCM
   SG_ RCM_FuelCutOff : 6|2@0+ (1,0) [0|3] "" PCU
   SG_ RCM_EventNotification : 7|1@0+ (1,0) [0|1] "" PCU

BO_ 1664 RCM_Diagnostic_Priv: 8 RCM

BO_ 1855 RCM_Diagnostic: 8 RCM

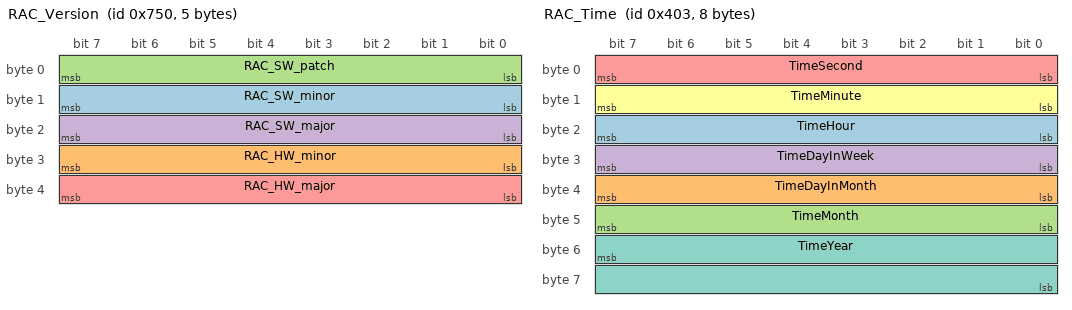
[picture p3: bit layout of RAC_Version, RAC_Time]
BO_ 1872 RAC_Version: 5 RAC
   SG_ RAC_SW_minor : 15|8@0+ (1,0) [0|255] "" Vector__XXX
   SG_ RAC_HW_minor : 31|8@0+ (1,0) [0|255] "" Vector__XXX
   SG_ RAC_SW_patch : 7|8@0+ (1,0) [0|255] "" Vector__XXX
   SG_ RAC_SW_major : 23|8@0+ (1,0) [0|255] "" Vector__XXX
   SG_ RAC_HW_major : 39|8@0+ (1,0) [0|255] "" Vector__XXX

BO_ 1874 RAC_VIN: 8 RAC
   SG_ VIN_Data : 15|48@0+ (1,0) [0|2.81475e+14] "" Vector__XXX
   SG_ VIN_Index : 7|8@0+ (1,0) [0|255] "" Vector__XXX

BO_ 1027 RAC_Time: 8 RAC
   SG_ TimeHour : 23|8@0+ (1,0) [0|255] "h" Vector__XXX
   SG_ TimeDayInMonth : 39|8@0+ (1,0) [0|255] "day" Vector__XXX
   SG_ TimeMonth : 47|8@0+ (1,0) [0|255] "Month" Vector__XXX
   SG_ TimeDayInWeek : 31|8@0+ (1,0) [0|255] "" Vector__XXX
   SG_ TimeSecond : 7|8@0+ (1,0) [0|255] "s" Vector__XXX
   SG_ TimeMinute : 15|8@0+ (1,0) [0|255] "min" Vector__XXX
   SG_ TimeYear : 55|16@0+ (1,0) [0|65535] "Year" Vector__XXX

BO_ 1025 RAC_Status: 8 RAC
   SG_ MemoryManagementStatus : 51|1@0+ (1,0) [0|1] "" Vector__XXX
   SG_ AirbagLampDriver : 23|2@0+ (1,0) [0|3] "" Vector__XXX
   SG_ HelpDeskLampStatus : 43|3@0+ (1,0) [0|7] "" Vector__XXX
   SG_ PhoneCallStatus : 36|3@0+ (1,0) [0|7] "" Vector__XXX
   SG_ GPRSStatus : 14|3@0+ (1,0) [0|7] "" Vector__XXX
   SG_ InCommunication : 50|1@0+ (1,0) [0|1] "" Vector__XXX
   SG_ GPSAntennaStatus : 21|2@0+ (1,0) [0|3] "" Vector__XXX
   SG_ CarState : 39|2@0+ (1,0) [0|3] "" Vector__XXX
   SG_ BluetoothConnection : 33|1@0+ (1,0) [0|1] "" Vector__XXX
   SG_ BluetoothStatus : 32|1@0+ (1,0) [0|1] "" Vector__XXX
   SG_ GPSStatus : 19|4@0+ (1,0) [0|15] "" Vector__XXX
   SG_ ContactKey : 0|1@0+ (1,0) [0|1] "" Vector__XXX
   SG_ SIMCardStatus : 8|1@0+ (1,0) [0|1] "" Vector__XXX
   SG_ HelpDeskRequest : 37|1@0+ (1,0) [0|1] "" Vector__XXX
   SG_ GSMStatus : 11|3@0+ (1,0) [0|7] "" Vector__XXX
   SG_ GPSModuleStatus : 53|2@0+ (1,0) [0|3] "" Vector__XXX
   SG_ CSQQuality : 28|5@0+ (1,0) [0|31] "" Vector__XXX
   SG_ ConnectedToServer : 15|1@0+ (1,0) [0|1] "" Vector__XXX
   SG_ AirbagLampStatus : 6|2@0+ (1,0) [0|3] "" Vector__XXX
   SG_ HelpDeskButtonStatus : 1|1@0+ (1,0) [0|1] "" Vector__XXX
   SG_ GSMModuleStatus : 55|2@0+ (1,0) [0|3] "" Vector__XXX
   SG_ AssistNumberProgrammed : 7|1@0+ (1,0) [0|1] "" Vector__XXX
   SG_ EPOStatus : 4|1@0+ (1,0) [0|1] "" Vector__XXX
   SG_ CrashEvent : 3|1@0+ (1,0) [0|1] "" Vector__XXX
   SG_ GPSSatellites : 47|4@0+ (1,0) [0|15] "" Vector__XXX
   SG_ SoundLevel : 31|3@0+ (1,0) [0|7] "" Vector__XXX

BO_ 1030 RAC_SerialNumber2: 8 RAC
   SG_ RACSerialNumber2 : 7|64@0+ (1,0) [0|1.84467e+19] "ASCII" DiagnosticTester

BO_ 1029 RAC_SerialNumber1: 8 RAC
   SG_ RACSerialNumber1 : 7|64@0+ (1,0) [0|1.84467e+19] "ASCII" DiagnosticTester

BO_ 1920 RAC_Phone: 8 RAC
   SG_ PhoneNumber : 15|56@0+ (1,0) [0|7.20576e+16] "" Vector__XXX
   SG_ PhoneIndex : 7|8@0+ (1,0) [0|255] "" Vector__XXX

BO_ 1028 RAC_Information: 8 RAC
   SG_ Odometer : 7|32@0+ (1,0) [0|4.29497e+09] "m" Vector__XXX
   SG_ RACSupplyVoltage : 39|16@0+ (1,0) [0|65535] "mV" Vector__XXX

BO_ 1024 RAC_HVAC_Functions: 8 RAC

BO_ 1897 RAC_Diagnostic_2: 8 RAC

BO_ 1904 RAC_Diagnostic: 8 RAC
   SG_ HistoricFlag_SIMNotInserted : 22|1@0+ (1,0) [0|1] "" DiagnosticTester
   SG_ ErrorFlag_GPSAntennaOC : 9|1@0+ (1,0) [0|1] "" DiagnosticTester
   SG_ HistoricFlag_WatchdogReboot : 4|1@0+ (1,0) [0|1] "" DiagnosticTester
   SG_ HistoricFlag_GPSNotResponding : 18|1@0+ (1,0) [0|1] "" DiagnosticTester
   SG_ ErrorFlag_SIMNotInserted : 23|1@0+ (1,0) [0|1] "" DiagnosticTester
   SG_ ErrorFlag_GPSAntennaSCGND : 17|1@0+ (1,0) [0|1] "" DiagnosticTester
   SG_ HistoricFlag_GSMNotResponding : 2|1@0+ (1,0) [0|1] "" DiagnosticTester
   SG_ HistoricFlag_FlashMemoryError : 6|1@0+ (1,0) [0|1] "" DiagnosticTester
   SG_ ErrorFlag_VeryLowBattery : 25|1@0+ (1,0) [0|1] "" Vector__XXX
   SG_ ErrorFlag_HelpdeskNotPrg : 15|1@0+ (1,0) [0|1] "" DiagnosticTester
   SG_ ErrorFlag_SIMRefused : 21|1@0+ (1,0) [0|1] "" DiagnosticTester
   SG_ ErrorFlag_PINError : 1|1@0+ (1,0) [0|1] "" DiagnosticTester
   SG_ ErrorFlag_FlashMemoryError : 7|1@0+ (1,0) [0|1] "" DiagnosticTester
   SG_ ErrorFlag_LowBattery : 29|1@0+ (1,0) [0|1] "" Vector__XXX
   SG_ HistoricFlag_LastDownloadFailed : 26|1@0+ (1,0) [0|1] "" Vector__XXX
   SG_ ErrorFlag_WatchdogReboot : 5|1@0+ (1,0) [0|1] "" DiagnosticTester
   SG_ HistoricFlag_PINError : 0|1@0+ (1,0) [0|1] "" DiagnosticTester
   SG_ ErrorFlag_GPSNotResponding : 19|1@0+ (1,0) [0|1] "" DiagnosticTester
   SG_ HistoricFlag_VeryLowBattery : 24|1@0+ (1,0) [0|1] "" Vector__XXX
   SG_ HistoricFlag_LowBattery : 28|1@0+ (1,0) [0|1] "" Vector__XXX
   SG_ HistoricFlag_BlueNotResponding : 30|1@0+ (1,0) [0|1] "" DiagnosticTester
   SG_ ErrorFlag_BlueNotResponding : 31|1@0+ (1,0) [0|1] "" DiagnosticTester
   SG_ ErrorFlag_LastDownloadFailed : 27|1@0+ (1,0) [0|1] "" Vector__XXX
   SG_ HistoricFlag_SIMRefused : 20|1@0+ (1,0) [0|1] "" DiagnosticTester
   SG_ ErrorFlag_GSMNotResponding : 3|1@0+ (1,0) [0|1] "" DiagnosticTester
   SG_ HistoricFlag_GPSAntennaOC : 8|1@0+ (1,0) [0|1] "" DiagnosticTester
   SG_ HistoricFlag_GPSAntennaSCGND : 16|1@0+ (1,0) [0|1] "" DiagnosticTester
   SG_ HistoricFlag_HelpDeskNotPrg : 14|1@0+ (1,0) [0|1] "" DiagnosticTester

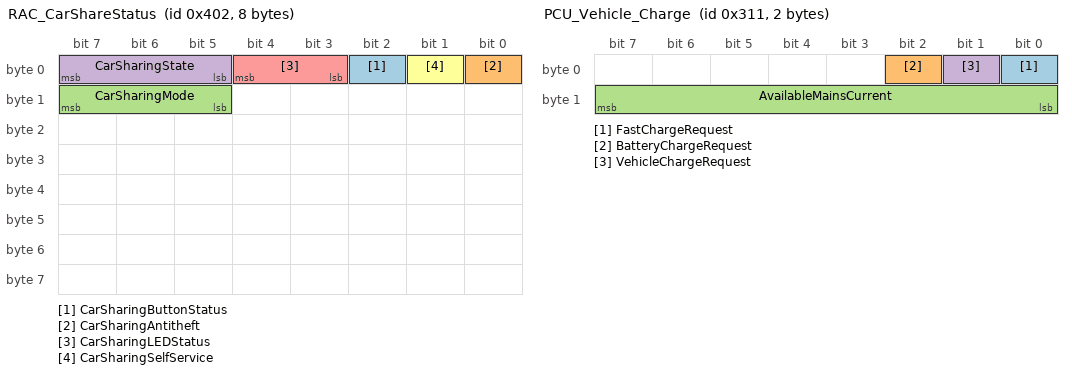
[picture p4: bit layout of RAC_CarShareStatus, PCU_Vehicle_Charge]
BO_ 1026 RAC_CarShareStatus: 8 RAC
   SG_ CarSharingButtonStatus : 2|1@0+ (1,0) [0|1] "" Vector__XXX
   SG_ CarSharingAntitheft : 0|1@0+ (1,0) [0|1] "" Vector__XXX
   SG_ CarSharingMode : 15|3@0+ (1,0) [0|7] "" Vector__XXX
   SG_ CarSharingState : 7|3@0+ (1,0) [0|7] "" Vector__XXX
   SG_ CarSharingLEDStatus : 4|2@0+ (1,0) [0|3] "" Vector__XXX
   SG_ CarSharingSelfService : 1|1@0+ (1,0) [0|1] "" Vector__XXX

BO_ 785 PCU_Vehicle_Charge: 2 PCU
   SG_ FastChargeRequest : 0|1@0+ (1,0) [0|1] "" BMS
   SG_ BatteryChargeRequest : 2|1@0+ (1,0) [0|1] "" BMS
   SG_ AvailableMainsCurrent : 15|8@0+ (0.2,0) [0|51] "A" BMS
   SG_ VehicleChargeRequest : 1|1@0+ (1,0) [0|1] "" BMS

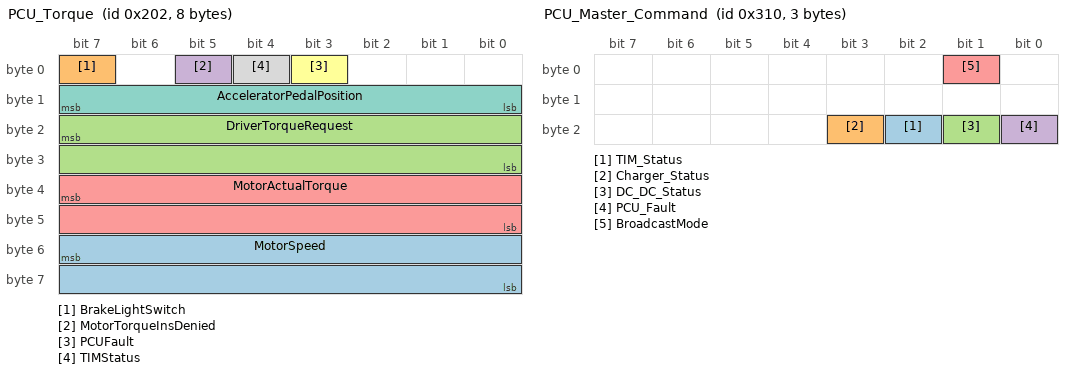
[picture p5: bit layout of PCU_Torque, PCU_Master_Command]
BO_ 514 PCU_Torque: 8 PCU
   SG_ MotorSpeed : 55|16@0- (1,0) [-32768|32767] "rpm" ESP
   SG_ BrakeLightSwitch : 7|1@0+ (1,0) [0|1] "" ESP
   SG_ DriverTorqueRequest : 23|16@0- (0.1,0) [-3276.8|3276.7] "Nm" ESP
   SG_ MotorTorqueInsDenied : 5|1@0+ (1,0) [0|1] "" ESP
   SG_ MotorActualTorque : 39|16@0- (0.1,0) [-3276.8|3276.7] "Nm" ESP
   SG_ PCUFault : 3|1@0+ (1,0) [0|1] "" ESP
   SG_ AcceleratorPedalPosition : 15|8@0+ (0.5,0) [0|127.5] "%" ESP
   SG_ TIMStatus : 4|1@0+ (1,0) [0|1] "" ESP

BO_ 595 PCU_Security_ID_2: 8 PCU
   SG_ SecurityID_2 : 7|64@0+ (1,0) [0|1.84467e+19] "" VCU

BO_ 594 PCU_Security_ID_1: 8 PCU
   SG_ SecurityID_1 : 7|64@0+ (1,0) [0|1.84467e+19] "" VCU

BO_ 784 PCU_Master_Command: 3 PCU
   SG_ TIM_Status : 18|1@0+ (1,0) [0|1] "" BMS
   SG_ Charger_Status : 19|1@0+ (1,0) [0|1] "" BMS
   SG_ DC_DC_Status : 17|1@0+ (1,0) [0|1] "" BMS
   SG_ PCU_Fault : 16|1@0+ (1,0) [0|1] "" BMS
   SG_ BroadcastMode : 1|1@0+ (1,0) [0|1] "" BMS

BO_ 849 PCU_LogInResponse: 7 PCU
   SG_ ChargerRequest : 7|48@0+ (1,0) [0|2.81475e+14] "" CHG
   SG_ ChargerAssignedID : 55|8@0+ (1,0) [0|255] "" CHG

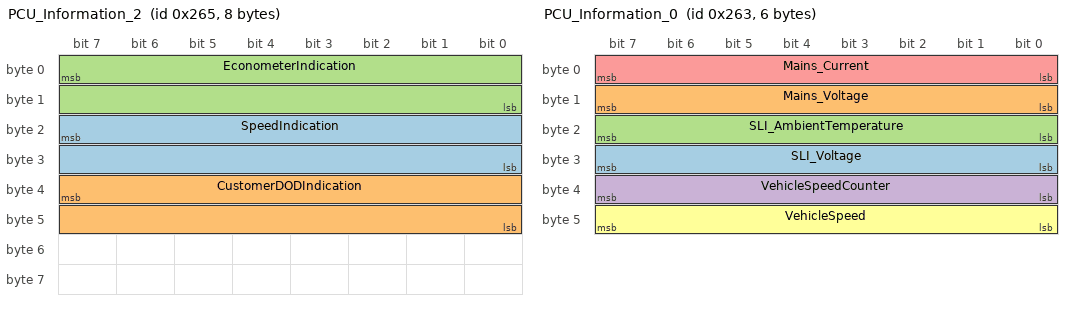
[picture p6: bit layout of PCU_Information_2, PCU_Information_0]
BO_ 613 PCU_Information_2: 8 PCU
   SG_ SpeedIndication : 23|16@0+ (0.1,0) [0|6553.5] "km/h" VCU
   SG_ CustomerDODIndication : 39|16@0+ (0.1,0) [0|6553.5] "%" VCU
   SG_ EconometerIndication : 7|16@0- (0.1,0) [-3276.8|3276.7] "%" VCU

BO_ 612 PCU_Information_1: 8 PCU
   SG_ PASEnable : 0|1@0+ (1,0) [0|1] "" RAC
   SG_ ESPIndication : 55|2@0+ (1,0) [0|3] "" Vector__XXX
   SG_ PowerLimitIndication : 19|2@0+ (1,0) [0|3] "" VCU
   SG_ EconomyIndication : 25|2@0+ (1,0) [0|3] "" VCU
   SG_ PCUESPSoftware : 44|1@0+ (1,0) [0|1] "" Vector__XXX
   SG_ ABSWarningIndication : 23|2@0+ (1,0) [0|3] "" VCU
   SG_ ElectricHzIndication : 11|2@0+ (1,0) [0|3] "" VCU
   SG_ BrakeWarningIndication : 21|2@0+ (1,0) [0|3] "" VCU
   SG_ OvertempIndication : 9|2@0+ (1,0) [0|3] "" VCU
   SG_ NeutralIndication : 37|2@0+ (1,0) [0|3] "" VCU
   SG_ MILIndication : 13|2@0+ (1,0) [0|3] "" VCU
   SG_ PowertrainGeneration : 43|4@0+ (1,0) [0|15] "" Vector__XXX
   SG_ ChargingIndication : 29|2@0+ (1,0) [0|3] "" VCU
   SG_ AuxiliaryBatteryLowIndication : 17|2@0+ (1,0) [0|3] "" VCU
   SG_ DriveEnableIndication : 31|2@0+ (1,0) [0|3] "" VCU
   SG_ PCUPTCReady : 53|1@0+ (1,0) [0|1] "" Vector__XXX
   SG_ OnPlugIndication : 27|2@0+ (1,0) [0|3] "" VCU
   SG_ GearPosition : 47|3@0+ (1,0) [0|7] "" VCU
   SG_ ParkIndication : 33|2@0+ (1,0) [0|3] "" VCU
   SG_ ReverseIndication : 35|2@0+ (1,0) [0|3] "" VCU
   SG_ LowSOCIndication : 15|2@0+ (1,0) [0|3] "" VCU
   SG_ PilotSignalPresent : 1|1@0+ (1,0) [0|1] "" VCU
   SG_ DriveIndication : 39|2@0+ (1,0) [0|3] "" VCU

BO_ 611 PCU_Information_0: 6 PCU
   SG_ SLI_Voltage : 31|8@0+ (0.1,0) [0|25.5] "VDC" BMS
   SG_ Mains_Voltage : 15|8@0+ (1,0) [0|255] "V AC rms" BMS
   SG_ SLI_AmbientTemperature : 23|8@0- (0.5,0) [-64|63.5] "deg C" RAC
   SG_ VehicleSpeedCounter : 39|8@0+ (1,0) [0|255] "" BMS
   SG_ Mains_Current : 7|8@0+ (0.2,0) [0|51] "A" PAS
   SG_ VehicleSpeed : 47|8@0+ (0.5,0) [0|127.5] "kph / km/h" RAC

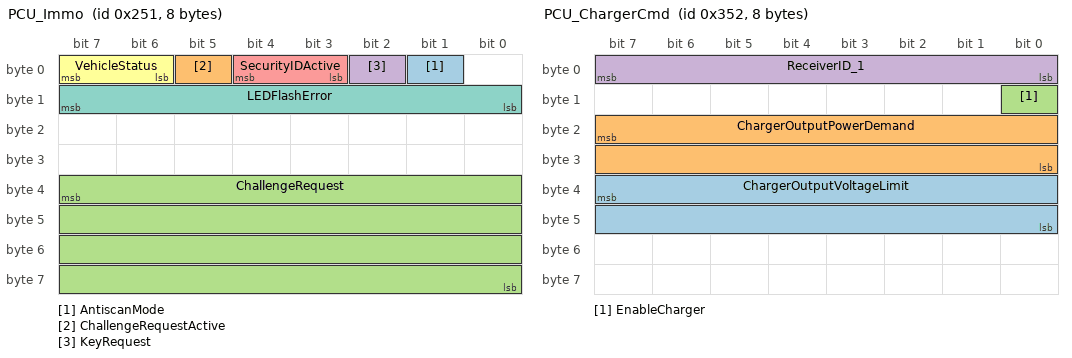
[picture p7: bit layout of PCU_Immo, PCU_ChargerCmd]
BO_ 593 PCU_Immo: 8 PCU
   SG_ AntiscanMode : 1|1@0+ (1,0) [0|1] "" Vector__XXX
   SG_ ChallengeRequestActive : 5|1@0+ (1,0) [0|1] "" VCU
   SG_ ChallengeRequest : 39|32@0+ (1,0) [0|4.29497e+09] "" VCU
   SG_ KeyRequest : 2|1@0+ (1,0) [0|1] "" Vector__XXX
   SG_ SecurityIDActive : 4|2@0+ (1,0) [0|3] "" VCU
   SG_ VehicleStatus : 7|2@0+ (1,0) [0|3] "" VCU
   SG_ LEDFlashError : 15|8@0+ (1,0) [0|255] "" VCU

BO_ 1883 PCU_Diagnostic: 8 PCU

BO_ 850 PCU_ChargerCmd: 8 PCU
   SG_ ChargerOutputVoltageLimit : 39|16@0+ (0.1,0) [0|6553.5] "V" CHG
   SG_ ChargerOutputPowerDemand : 23|16@0+ (0.1,0) [0|100] "%" CHG
   SG_ EnableCharger : 8|1@0+ (1,0) [0|1] "" CHG
   SG_ ReceiverID_1 : 7|8@0+ (1,0) [0|255] "" CHG

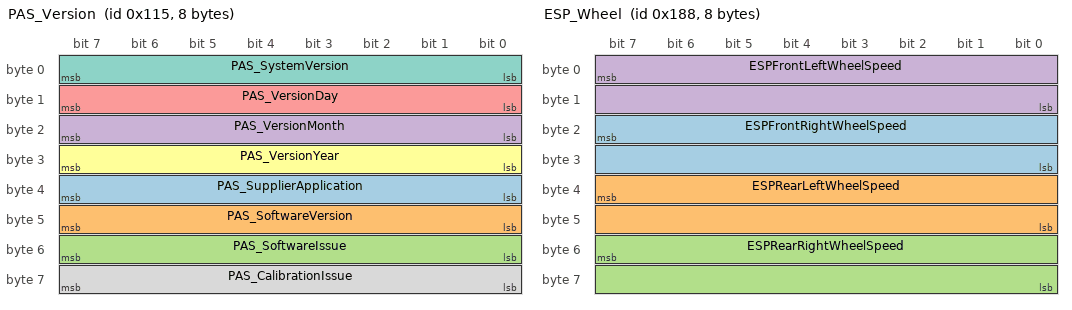
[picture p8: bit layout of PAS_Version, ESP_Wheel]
BO_ 277 PAS_Version: 8 PAS
   SG_ PAS_SupplierApplication : 39|8@0+ (1,0) [0|255] "" DiagnosticTester
   SG_ PAS_SoftwareVersion : 47|8@0+ (1,0) [0|255] "" DiagnosticTester
   SG_ PAS_SoftwareIssue : 55|8@0+ (1,0) [0|255] "" DiagnosticTester
   SG_ PAS_VersionMonth : 23|8@0+ (1,0) [0|12] "" DiagnosticTester
   SG_ PAS_VersionDay : 15|8@0+ (1,0) [0|31] "" DiagnosticTester
   SG_ PAS_VersionYear : 31|8@0+ (1,0) [0|99] "" DiagnosticTester
   SG_ PAS_SystemVersion : 7|8@0+ (1,0) [0|255] "" DiagnosticTester
   SG_ PAS_CalibrationIssue : 63|8@0+ (1,0) [0|255] "" DiagnosticTester

BO_ 1173 PAS_Status: 2 PAS
   SG_ PAS_Status : 15|8@0+ (1,0) [0|255] "" PCU

BO_ 1685 PAS_Diagnostic: 8 PAS

BO_ 392 ESP_Wheel: 8 ESP
   SG_ ESPFrontRightWheelSpeed : 23|16@0+ (0.0625,0) [0|4095.94] "km/h" Vector__XXX
   SG_ ESPRearLeftWheelSpeed : 39|16@0+ (0.0625,0) [0|4095.94] "km/h" Vector__XXX
   SG_ ESPRearRightWheelSpeed : 55|16@0+ (0.0625,0) [0|4095.94] "km/h" Vector__XXX
   SG_ ESPFrontLeftWheelSpeed : 7|16@0+ (0.0625,0) [0|4095.94] "km/h" Vector__XXX

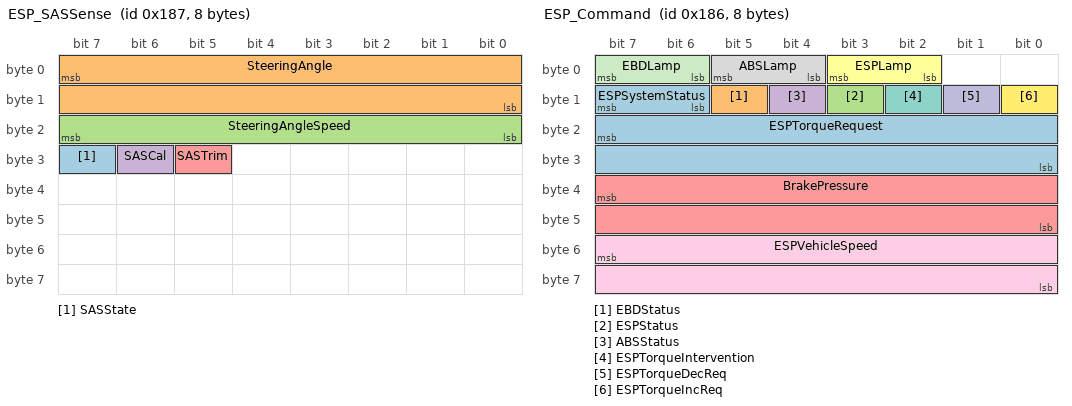
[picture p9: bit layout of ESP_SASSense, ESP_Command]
BO_ 391 ESP_SASSense: 8 ESP
   SG_ SASState : 31|1@0+ (1,0) [0|1] "" Vector__XXX
   SG_ SteeringAngle : 7|16@0- (0.1,0) [-3276.8|3276.7] "deg" Vector__XXX
   SG_ SteeringAngleSpeed : 23|8@0+ (4,0) [0|1020] "deg/s" Vector__XXX
   SG_ SASCal : 30|1@0+ (1,0) [0|1] "" Vector__XXX
   SG_ SASTrim : 29|1@0+ (1,0) [0|1] "" Vector__XXX

BO_ 390 ESP_Command: 8 ESP
   SG_ ESPSystemStatus : 15|2@0+ (1,0) [0|3] "" PCU
   SG_ EBDStatus : 13|1@0+ (1,0) [0|1] "" PCU
   SG_ ESPStatus : 11|1@0+ (1,0) [0|1] "" PCU
   SG_ ABSStatus : 12|1@0+ (1,0) [0|1] "" PCU
   SG_ BrakePressure : 39|16@0+ (0.0625,0) [0|4095.94] "bar" PCU
   SG_ ESPLamp : 3|2@0+ (1,0) [0|3] "" PCU
   SG_ ESPTorqueIntervention : 10|1@0+ (1,0) [0|1] "" PCU
   SG_ ABSLamp : 5|2@0+ (1,0) [0|3] "" PCU
   SG_ ESPVehicleSpeed : 55|16@0+ (0.0625,0) [0|4095.94] "km/h" PCU
   SG_ ESPTorqueDecReq : 9|1@0+ (1,0) [0|1] "" PCU
   SG_ EBDLamp : 7|2@0+ (1,0) [0|3] "" PCU
   SG_ ESPTorqueIncReq : 8|1@0+ (1,0) [0|1] "" PCU
   SG_ ESPTorqueRequest : 23|16@0- (0.1,0) [-3276.8|3276.7] "Nm" PCU

BO_ 2000 Diagnostic_VCU: 8 DiagnosticTester

BO_ 1921 Diagnostic_TPMS: 8 DiagnosticTester

BO_ 1665 Diagnostic_RCM_Priv: 8 DiagnosticTester

BO_ 1847 Diagnostic_RCM: 8 DiagnosticTester

BO_ 1873 Diagnostic_RAC_Configuration: 8 DiagnosticTester

BO_ 1905 Diagnostic_RAC: 8 DiagnosticTester

BO_ 1875 Diagnostic_PCU: 8 DiagnosticTester

BO_ 1717 Diagnostic_PAS: 8 DiagnosticTester

BO_ 1910 Diagnostic_CDCM: 8 DiagnosticTester

BO_ 1861 Diagnostic_BMS: 8 DiagnosticTester

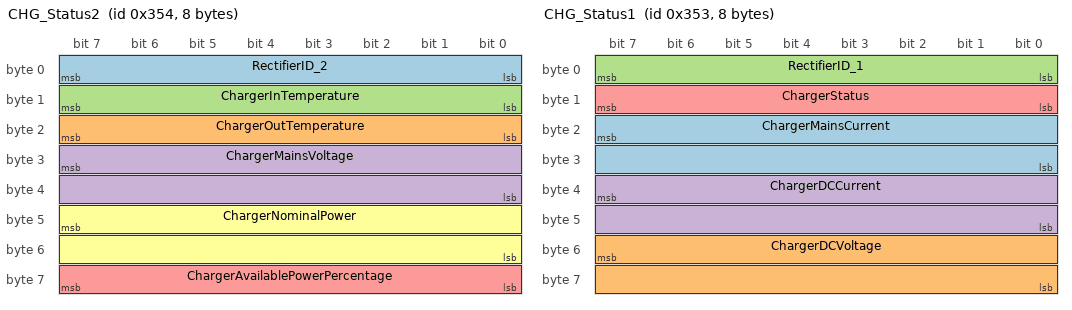
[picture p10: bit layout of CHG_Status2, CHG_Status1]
BO_ 852 CHG_Status2: 8 CHG
   SG_ RectifierID_2 : 7|8@0+ (1,0) [0|255] "" PCU
   SG_ ChargerOutTemperature : 23|8@0- (1,0) [-128|127] "deg C" PCU
   SG_ ChargerInTemperature : 15|8@0- (1,0) [-128|127] "deg C" PCU
   SG_ ChargerMainsVoltage : 31|16@0+ (1,0) [0|65535] "V rms" PCU
   SG_ ChargerAvailablePowerPercentage : 63|8@0+ (0.5,0) [0|127.5] "%" Vector__XXX
   SG_ ChargerNominalPower : 47|16@0+ (1,0) [0|65535] "W" Vector__XXX

BO_ 851 CHG_Status1: 8 CHG
   SG_ ChargerMainsCurrent : 23|16@0+ (0.2,0) [0|13107] "A rms" PCU
   SG_ ChargerDCVoltage : 55|16@0+ (0.1,0) [0|6553.5] "V" PCU
   SG_ RectifierID_1 : 7|8@0+ (1,0) [0|255] "" PCU
   SG_ ChargerDCCurrent : 39|16@0- (0.1,0) [-3276.8|3276.7] "A" PCU
   SG_ ChargerStatus : 15|8@0+ (1,0) [0|255] "" PCU

BO_ 1640 CHG_Secondary_Download: 8 Vector__XXX

BO_ 1639 CHG_Primary_Download: 8 Vector__XXX

BO_ 848 CHG_LogInRequest: 6 CHG
   SG_ LogInRequest : 7|48@0+ (1,0) [0|2.81475e+14] "" PCU

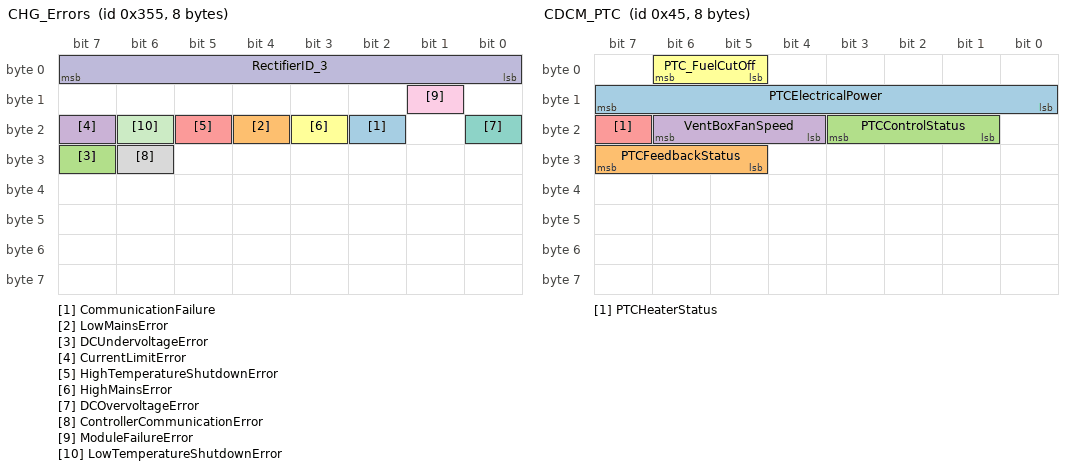
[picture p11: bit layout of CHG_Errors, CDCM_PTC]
BO_ 853 CHG_Errors: 8 CHG
   SG_ CommunicationFailure : 18|1@0+ (1,0) [0|1] "" PCU
   SG_ LowMainsError : 20|1@0+ (1,0) [0|1] "" PCU
   SG_ DCUndervoltageError : 31|1@0+ (1,0) [0|1] "" PCU
   SG_ CurrentLimitError : 23|1@0+ (1,0) [0|1] "" PCU
   SG_ HighTemperatureShutdownError : 21|1@0+ (1,0) [0|1] "" PCU
   SG_ HighMainsError : 19|1@0+ (1,0) [0|1] "" PCU
   SG_ DCOvervoltageError : 16|1@0+ (1,0) [0|1] "" PCU
   SG_ ControllerCommunicationError : 30|1@0+ (1,0) [0|1] "" PCU
   SG_ ModuleFailureError : 9|1@0+ (1,0) [0|1] "" PCU
   SG_ RectifierID_3 : 7|8@0+ (1,0) [0|255] "" PCU
   SG_ LowTemperatureShutdownError : 22|1@0+ (1,0) [0|1] "" PCU

BO_ 1032 CDCM_Status: 8 CDCM
   SG_ CDCMFrontDemistSwitch : 27|1@0+ (1,0) [0|1] "" Vector__XXX
   SG_ CDCMRearDemistSwitch : 24|1@0+ (1,0) [0|1] "" Vector__XXX
   SG_ CDCMHWVersion : 15|8@0+ (1,0) [0|255] "" Vector__XXX
   SG_ ACPresent : 23|1@0+ (1,0) [0|1] "" Vector__XXX
   SG_ CDCMKeyRun : 28|1@0+ (1,0) [0|1] "" Vector__XXX
   SG_ CDCMWakeUp : 30|1@0+ (1,0) [0|1] "" Vector__XXX
   SG_ CDCMSWVersion : 7|8@0+ (1,0) [0|255] "" Vector__XXX
   SG_ CDCM12VSupply : 55|8@0+ (0.1,0) [0|25.5] "VDC" Vector__XXX
   SG_ CDCMHeaterFault : 31|1@0+ (1,0) [0|1] "" Vector__XXX
   SG_ CDCMHVRequest : 38|1@0+ (1,0) [0|1] "" Vector__XXX
   SG_ CDCMFrontDemist1 : 35|1@0+ (1,0) [0|1] "" Vector__XXX
   SG_ CDCMCondenserFan : 34|1@0+ (1,0) [0|1] "" Vector__XXX
   SG_ EvaporatorTemperature : 47|8@0- (0.8,0) [-102.4|101.6] "deg C" Vector__XXX
   SG_ CDCMHeaterEnable : 33|1@0+ (1,0) [0|1] "" Vector__XXX
   SG_ CDCMInverterSupply : 39|1@0+ (1,0) [0|1] "" Vector__XXX
   SG_ CDCMForcedBlower : 37|1@0+ (1,0) [0|1] "" Vector__XXX
   SG_ CDCMFrontDemist2 : 36|1@0+ (1,0) [0|1] "" Vector__XXX
   SG_ HeaterKnobPosition : 63|8@0+ (1,0) [0|255] "%" Vector__XXX
   SG_ CDCMRearDemist : 32|1@0+ (1,0) [0|1] "" Vector__XXX
   SG_ CDCMOperationState : 19|4@0+ (1,0) [0|15] "" Vector__XXX
   SG_ CDCMACRequest : 29|1@0+ (1,0) [0|1] "" Vector__XXX

BO_ 69 CDCM_PTC: 8 CDCM
   SG_ PTCElectricalPower : 15|8@0+ (0.1,0) [0|25.5] "kW" Vector__XXX
   SG_ PTCFeedbackStatus : 31|3@0+ (1,0) [0|7] "" Vector__XXX
   SG_ PTCControlStatus : 19|3@0+ (1,0) [0|7] "" Vector__XXX
   SG_ VentBoxFanSpeed : 22|3@0+ (1,0) [0|7] "" Vector__XXX
   SG_ PTCHeaterStatus : 23|1@0+ (1,0) [0|0] "" Vector__XXX
   SG_ PTC_FuelCutOff : 6|2@0+ (1,0) [0|3] "" BMS

BO_ 1033 CDCM_Error: 8 CDCM
   SG_ KnobPositionTooHigh : 19|1@0+ (1,0) [0|1] "" Vector__XXX
   SG_ CondenserFanOC : 2|1@0+ (1,0) [0|1] "" Vector__XXX
   SG_ PTCCommunicationBroken : 43|1@0+ (1,0) [0|1] "" Vector__XXX
   SG_ RearDemistSC : 8|1@0+ (1,0) [0|1] "" Vector__XXX
   SG_ PTCHVMissing : 44|1@0+ (1,0) [0|1] "" Vector__XXX
   SG_ HVrequestSC : 14|1@0+ (1,0) [0|1] "" Vector__XXX
   SG_ FrontDemist2OC : 4|1@0+ (1,0) [0|1] "" Vector__XXX
   SG_ FluidHeaterFaultLineOld : 23|1@0+ (1,0) [0|1] "" Vector__XXX
   SG_ ClimateCANTimeout : 32|1@0+ (1,0) [0|1] "" Vector__XXX
   SG_ KnobPositionTooLow : 18|1@0+ (1,0) [0|1] "" Vector__XXX
   SG_ PTCOtherError : 42|1@0+ (1,0) [0|1] "" Vector__XXX
   SG_ HeaterEnableOC : 1|1@0+ (1,0) [0|1] "" Vector__XXX
   SG_ HeaterEnableSC : 9|1@0+ (1,0) [0|1] "" Vector__XXX
   SG_ CondenserFanSC : 10|1@0+ (1,0) [0|1] "" Vector__XXX
   SG_ ForcedBlowerOC : 5|1@0+ (1,0) [0|1] "" Vector__XXX
   SG_ InverterSupplyOC : 7|1@0+ (1,0) [0|1] "" Vector__XXX
   SG_ FrontDemist1SC : 11|1@0+ (1,0) [0|1] "" Vector__XXX
   SG_ BMSSWNotReady : 45|1@0+ (1,0) [0|1] "" Vector__XXX
   SG_ ForcedBlowerSC : 13|1@0+ (1,0) [0|1] "" Vector__XXX
   SG_ RearDemistOC : 0|1@0+ (1,0) [0|1] "" Vector__XXX
   SG_ TemperatureSensorSignalTooLow : 16|1@0+ (1,0) [0|1] "" Vector__XXX
   SG_ TemperatureSensorSignalTooHigh : 17|1@0+ (1,0) [0|1] "" Vector__XXX
   SG_ InverterSupplySC : 15|1@0+ (1,0) [0|1] "" Vector__XXX
   SG_ FrontDemist2SC : 12|1@0+ (1,0) [0|1] "" Vector__XXX
   SG_ FrontDemist1OC : 3|1@0+ (1,0) [0|1] "" Vector__XXX
   SG_ FluidHeaterFaultLineCurrent : 22|1@0+ (1,0) [0|1] "" Vector__XXX
   SG_ PCUSWNotReady : 47|1@0+ (1,0) [0|1] "" Vector__XXX
   SG_ VCUSWNotReady : 46|1@0+ (1,0) [0|1] "" Vector__XXX
   SG_ HVRequestOC : 6|1@0+ (1,0) [0|1] "" Vector__XXX

BO_ 1918 CDCM_Diagnostic_Copy_1: 8 CDCM

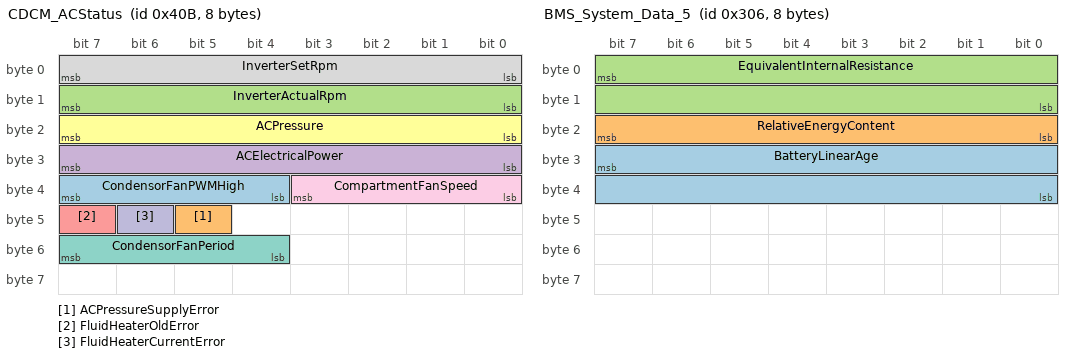
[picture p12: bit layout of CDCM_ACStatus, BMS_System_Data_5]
BO_ 1035 CDCM_ACStatus: 8 CDCM
   SG_ CondensorFanPWMHigh : 39|4@0+ (5,0) [0|75] "ms" Vector__XXX
   SG_ ACPressureSupplyError : 45|1@0+ (1,0) [0|1] "" Vector__XXX
   SG_ InverterActualRpm : 15|8@0+ (60,0) [0|15300] "rpm" Vector__XXX
   SG_ ACElectricalPower : 31|8@0+ (0.1,0) [0|25.5] "kW" Vector__XXX
   SG_ FluidHeaterOldError : 47|1@0+ (1,0) [0|1] "" Vector__XXX
   SG_ ACPressure : 23|8@0+ (1,0) [0|35] "bar" Vector__XXX
   SG_ CondensorFanPeriod : 55|4@0+ (5,0) [0|75] "ms" Vector__XXX
   SG_ InverterSetRpm : 7|8@0+ (60,0) [0|15300] "rpm" Vector__XXX
   SG_ CompartmentFanSpeed : 35|4@0+ (1,0) [0|15] "" Vector__XXX
   SG_ FluidHeaterCurrentError : 46|1@0+ (1,0) [0|1] "" Vector__XXX

BO_ 51 CCP_VCU_DTO: 8 Vector__XXX

BO_ 1957 CCP_VCU_DAC2: 8 Vector__XXX

BO_ 1956 CCP_VCU_DAC1: 8 Vector__XXX

BO_ 1955 CCP_VCU_DAC0: 8 Vector__XXX

BO_ 50 CCP_VCU_CRO: 8 Vector__XXX

BO_ 55 CCP_PCU_DTO: 8 Vector__XXX

BO_ 1963 CCP_PCU_DAC2: 8 Vector__XXX

BO_ 1962 CCP_PCU_DAC1: 8 Vector__XXX

BO_ 1961 CCP_PCU_DAC0: 8 Vector__XXX

BO_ 54 CCP_PCU_CRO: 8 Vector__XXX

BO_ 53 CCP_CHG_DTO: 8 Vector__XXX

BO_ 1960 CCP_CHG_DAC2: 8 Vector__XXX

BO_ 1959 CCP_CHG_DAC1: 8 Vector__XXX

BO_ 1958 CCP_CHG_DAC0: 8 Vector__XXX

BO_ 52 CCP_CHG_CRO: 8 Vector__XXX

BO_ 49 CCP_CDCM_DTO: 8 Vector__XXX

BO_ 1954 CCP_CDCM_DAC2: 8 Vector__XXX

BO_ 1953 CCP_CDCM_DAC1: 8 Vector__XXX

BO_ 1952 CCP_CDCM_DAC0: 8 Vector__XXX

BO_ 48 CCP_CDCM_CRO: 8 Vector__XXX

BO_ 57 CCP_BMS_DTO: 8 Vector__XXX

BO_ 1966 CCP_BMS_DAC2: 8 Vector__XXX

BO_ 1965 CCP_BMS_DAC1: 8 Vector__XXX

BO_ 1964 CCP_BMS_DAC0: 8 Vector__XXX

BO_ 56 CCP_BMS_CRO: 8 Vector__XXX

BO_ 774 BMS_System_Data_5: 8 BMS
   SG_ BatteryLinearAge : 31|16@0+ (1,0) [0|65535] "" Vector__XXX
   SG_ RelativeEnergyContent : 23|8@0+ (0.5,0) [0|100] "%" Vector__XXX
   SG_ EquivalentInternalResistance : 7|16@0+ (0.001,0) [0|65.535] "Ohms" Vector__XXX

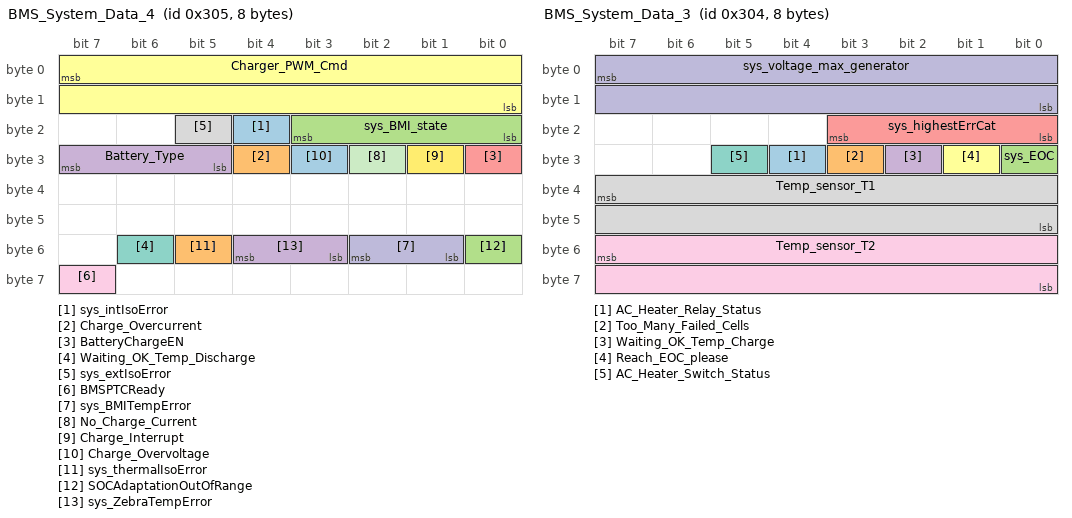
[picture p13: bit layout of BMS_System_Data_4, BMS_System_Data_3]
BO_ 773 BMS_System_Data_4: 8 BMS
   SG_ sys_intIsoError : 20|1@0+ (1,0) [0|1] "" PCU
   SG_ Charge_Overcurrent : 28|1@0+ (1,0) [0|1] "" Vector__XXX
   SG_ sys_BMI_state : 19|4@0+ (1,0) [0|15] "" Vector__XXX
   SG_ Battery_Type : 31|3@0+ (1,0) [0|7] "" PCU
   SG_ BatteryChargeEN : 24|1@0+ (1,0) [0|1] "" PCU
   SG_ Charger_PWM_Cmd : 7|16@0+ (0.1,0) [0|100] "%" PCU
   SG_ Waiting_OK_Temp_Discharge : 54|1@0+ (1,0) [0|1] "" PCU
   SG_ sys_extIsoError : 21|1@0+ (1,0) [0|1] "" PCU
   SG_ BMSPTCReady : 63|1@0+ (1,0) [0|1] "" Vector__XXX
   SG_ sys_BMITempError : 50|2@0+ (1,0) [0|3] "" PCU
   SG_ No_Charge_Current : 26|1@0+ (1,0) [0|1] "" PCU
   SG_ Charge_Interrupt : 25|1@0+ (1,0) [0|1] "" Vector__XXX
   SG_ Charge_Overvoltage : 27|1@0+ (1,0) [0|1] "" Vector__XXX
   SG_ sys_thermalIsoError : 53|1@0+ (1,0) [0|1] "" PCU
   SG_ SOCAdaptationOutOfRange : 48|1@0+ (1,0) [0|1] "" Vector__XXX
   SG_ sys_ZebraTempError : 52|2@0+ (1,0) [0|3] "" PCU

BO_ 772 BMS_System_Data_3: 8 BMS
   SG_ AC_Heater_Relay_Status : 28|1@0+ (1,0) [0|1] "" PCU
   SG_ Too_Many_Failed_Cells : 27|1@0+ (1,0) [0|1] "" PCU
   SG_ sys_EOC : 24|1@0+ (1,0) [0|1] "" PCU
   SG_ Waiting_OK_Temp_Charge : 26|1@0+ (1,0) [0|1] "" PCU
   SG_ sys_highestErrCat : 19|4@0+ (1,0) [0|15] "" PCU
   SG_ Reach_EOC_please : 25|1@0+ (1,0) [0|1] "" PCU
   SG_ AC_Heater_Switch_Status : 29|1@0+ (1,0) [0|1] "" PCU
   SG_ Temp_sensor_T1 : 39|16@0+ (0.1,0) [0|65535] "" Vector__XXX
   SG_ Temp_sensor_T2 : 55|16@0+ (0.1,0) [0|65535] "" Vector__XXX
   SG_ sys_voltage_max_generator : 7|16@0+ (0.1,0) [0|65535] "" Vector__XXX

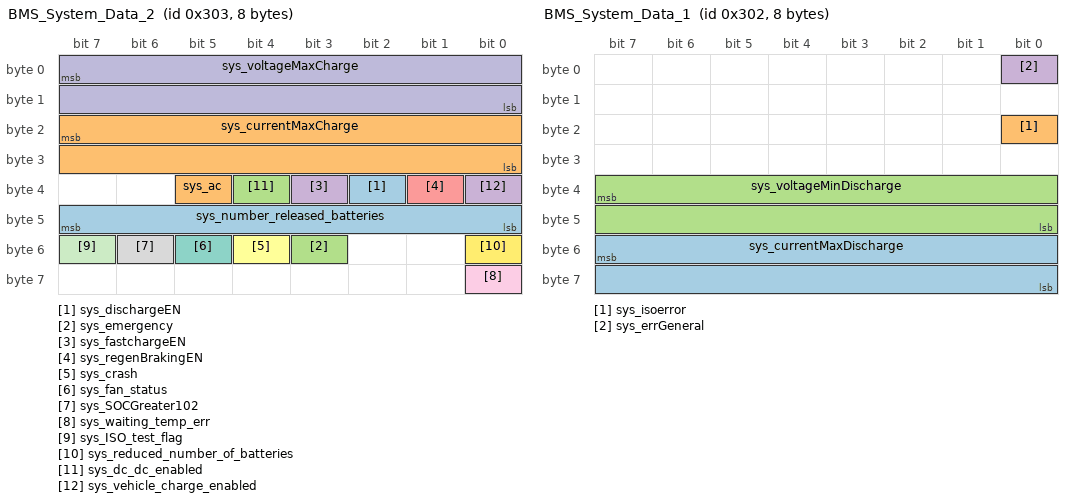
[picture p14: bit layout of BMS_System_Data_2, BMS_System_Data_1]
BO_ 771 BMS_System_Data_2: 8 BMS
   SG_ sys_dischargeEN : 34|1@0+ (1,0) [0|1] "" PCU
   SG_ sys_currentMaxCharge : 23|16@0+ (0.1,0) [0|6553.5] "A" PCU
   SG_ sys_emergency : 51|1@0+ (1,0) [0|1] "" PCU
   SG_ sys_fastchargeEN : 35|1@0+ (1,0) [0|1] "" PCU
   SG_ sys_regenBrakingEN : 33|1@0+ (1,0) [0|1] "" PCU
   SG_ sys_crash : 52|1@0+ (1,0) [0|1] "" PCU
   SG_ sys_fan_status : 53|1@0+ (1,0) [0|1] "" PCU
   SG_ sys_SOCGreater102 : 54|1@0+ (1,0) [0|1] "" PCU
   SG_ sys_waiting_temp_err : 56|1@0+ (1,0) [0|1] "" PCU
   SG_ sys_voltageMaxCharge : 7|16@0+ (0.1,0) [0|6553.5] "V" PCU
   SG_ sys_ISO_test_flag : 55|1@0+ (1,0) [0|1] "" PCU
   SG_ sys_reduced_number_of_batteries : 48|1@0+ (1,0) [0|1] "" PCU
   SG_ sys_number_released_batteries : 47|8@0+ (1,0) [0|1] "" PCU
   SG_ sys_ac : 37|1@0+ (1,0) [0|1] "" PCU
   SG_ sys_dc_dc_enabled : 36|1@0+ (1,0) [0|1] "" PCU
   SG_ sys_vehicle_charge_enabled : 32|1@0+ (1,0) [0|1] "" PCU

BO_ 770 BMS_System_Data_1: 8 BMS
   SG_ sys_currentMaxDischarge : 55|16@0+ (0.1,0) [0|6553.5] "A" PCU
   SG_ sys_isoerror : 16|1@0+ (1,0) [0|1] "" PCU
   SG_ sys_voltageMinDischarge : 39|16@0+ (0.1,0) [0|6553.5] "V" PCU
   SG_ sys_errGeneral : 0|1@0+ (1,0) [0|1] "" PCU

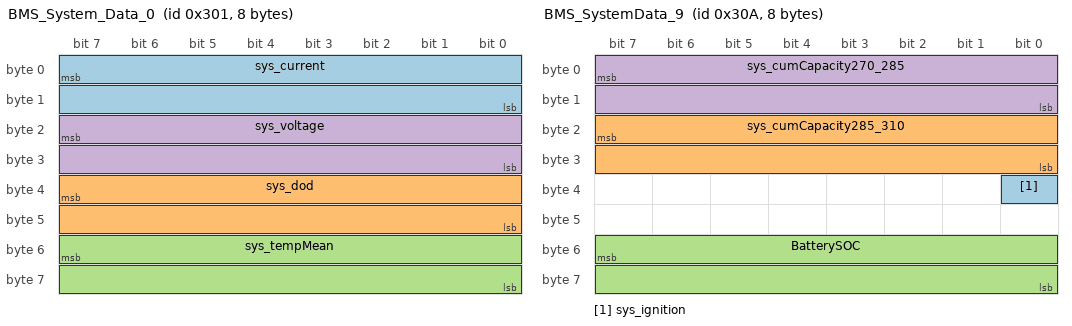
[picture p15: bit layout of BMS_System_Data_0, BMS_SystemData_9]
BO_ 769 BMS_System_Data_0: 8 BMS
   SG_ sys_current : 7|16@0- (0.1,0) [-3276.8|3276.7] "A" PCU
   SG_ sys_dod : 39|16@0+ (0.1,0) [0|6553.5] "%" PCU
   SG_ sys_tempMean : 55|16@0- (0.1,0) [-3276.8|3276.7] "deg C" PCU
   SG_ sys_voltage : 23|16@0+ (0.1,0) [0|6553.5] "V" PCU

BO_ 778 BMS_SystemData_9: 8 BMS
   SG_ sys_ignition : 32|1@0+ (1,0) [0|1] "" Vector__XXX
   SG_ sys_cumCapacity285_310 : 23|16@0+ (1,0) [0|65535] "Ah" Vector__XXX
   SG_ BatterySOC : 55|16@0+ (0.1,0) [0|6553.5] "%" Vector__XXX
   SG_ sys_cumCapacity270_285 : 7|16@0+ (1,0) [0|65535] "Ah" Vector__XXX

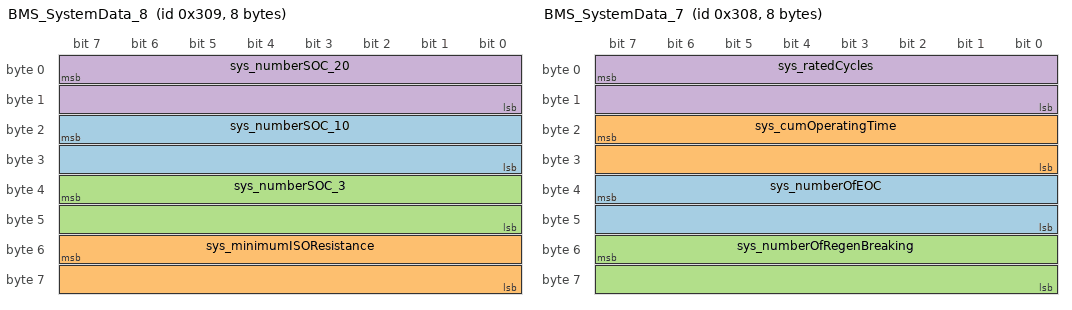
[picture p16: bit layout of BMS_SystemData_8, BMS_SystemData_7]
BO_ 777 BMS_SystemData_8: 8 BMS
   SG_ sys_numberSOC_10 : 23|16@0+ (1,0) [0|65535] "" Vector__XXX
   SG_ sys_minimumISOResistance : 55|16@0+ (1,0) [0|65535] "ohms" Vector__XXX
   SG_ sys_numberSOC_3 : 39|16@0+ (1,0) [0|65535] "" Vector__XXX
   SG_ sys_numberSOC_20 : 7|16@0+ (1,0) [0|65535] "" Vector__XXX

BO_ 776 BMS_SystemData_7: 8 BMS
   SG_ sys_numberOfEOC : 39|16@0+ (1,0) [0|65535] "" Vector__XXX
   SG_ sys_cumOperatingTime : 23|16@0+ (1,0) [0|65535] "days" Vector__XXX
   SG_ sys_numberOfRegenBreaking : 55|16@0+ (1,0) [0|65535] "" Vector__XXX
   SG_ sys_ratedCycles : 7|16@0+ (1,0) [0|65535] "" Vector__XXX

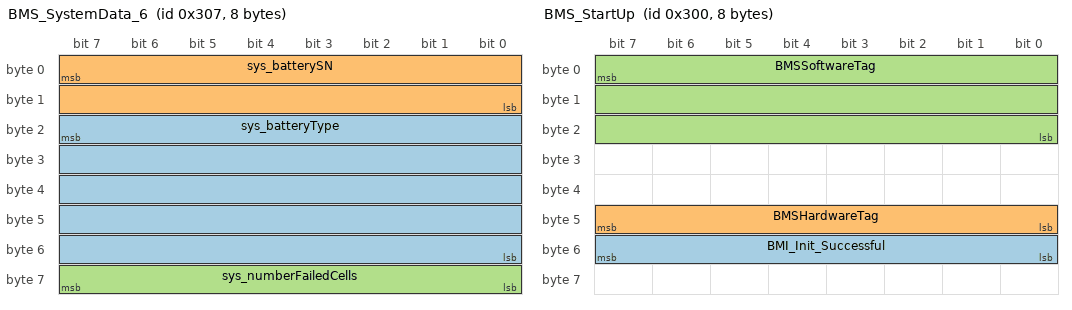
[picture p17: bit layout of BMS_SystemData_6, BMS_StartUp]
BO_ 775 BMS_SystemData_6: 8 BMS
   SG_ sys_batteryType : 23|40@0+ (1,0) [0|1.09951e+12] "" Vector__XXX
   SG_ sys_batterySN : 7|16@0+ (1,0) [0|65535] "" Vector__XXX
   SG_ sys_numberFailedCells : 63|8@0+ (1,0) [0|255] "" Vector__XXX

BO_ 768 BMS_StartUp: 8 BMS
   SG_ BMI_Init_Successful : 55|8@0+ (1,0) [0|255] "" PCU
   SG_ BMSHardwareTag : 47|8@0+ (1,0) [0|1] "" PCU
   SG_ BMSSoftwareTag : 7|24@0+ (1,0) [0|1.67772e+07] "" PCU

BO_ 783 BMS_SerialNumber2: 8 BMS
   SG_ BatterySerialNumber2 : 7|64@0+ (1,0) [0|1.84467e+19] "ASCII" DiagnosticTester

BO_ 782 BMS_SerialNumber1: 8 BMS
   SG_ BatterySerialNumber1 : 7|64@0+ (1,0) [0|1.84467e+19] "ASCII" DiagnosticTester

BO_ 1827 EDL_History_Fault_Data: 8 EDL
   SG_ 00_Bus_Voltage_AD_Fault : 0|1@0+ (1,0) [0|1] "" Vector__XXX
   SG_ 01_Pack_Voltage_AD_Fault : 1|1@0+ (1,0) [0|1] "" Vector__XXX
   SG_ 02_Pack_Current_B_hi_AD_Fault : 2|1@0+ (1,0) [0|1] "" Vector__XXX
   SG_ 03_Pack_Current_B_lo_AD_Fault : 3|1@0+ (1,0) [0|1] "" Vector__XXX
   SG_ 04_Pack_Current_A_hi_AD_Fault : 4|1@0+ (1,0) [0|1] "" Vector__XXX
   SG_ 05_Pack_Current_A_lo_AD_Fault : 5|1@0+ (1,0) [0|1] "" Vector__XXX
   SG_ 06_Board_Under_Temp_Fault : 6|1@0+ (1,0) [0|1] "" Vector__XXX
   SG_ 07_Secondary_Contactor_Stuck_On_Fault : 7|1@0+ (1,0) [0|1] "" Vector__XXX
   SG_ 08_Internal_Isolation_Fault : 8|1@0+ (1,0) [0|1] "" Vector__XXX
   SG_ 09_External_Isolation_Fault : 9|1@0+ (1,0) [0|1] "" Vector__XXX
   SG_ 10_Secondary_Contactor_A_Open_Fault : 10|1@0+ (1,0) [0|1] "" Vector__XXX
   SG_ 11_Contactor_Precharge_Short_Fault : 11|1@0+ (1,0) [0|1] "" Vector__XXX
   SG_ 12_Contactor_1_Dropout_Second_Fault : 12|1@0+ (1,0) [0|1] "" Vector__XXX
   SG_ 13_Contactor_1_Dropout_First_Fault : 13|1@0+ (1,0) [0|1] "" Vector__XXX
   SG_ 14_Contactor_Precharge_Retry_Fault : 14|1@0+ (1,0) [0|1] "" Vector__XXX
   SG_ 15_Contactor_Precharge_Timeout_Fault : 15|1@0+ (1,0) [0|1] "" Vector__XXX
   SG_ 16_Redundant_Cell_Voltage_Comparison_Fault : 16|1@0+ (1,0) [0|1] "" Vector__XXX
   SG_ 17_Contactor_2_Stuck_On_Fault : 17|1@0+ (1,0) [0|1] "" Vector__XXX
   SG_ 18_No_Charge_Current_Fault : 18|1@0+ (1,0) [0|1] "" Vector__XXX
   SG_ 19_Board_Over_Temp_Fault : 19|1@0+ (1,0) [0|1] "" Vector__XXX
   SG_ 20_Pack_Under_Temp_Fault : 20|1@0+ (1,0) [0|1] "" Vector__XXX
   SG_ 21_Pack_Over_Temp_Fault : 21|1@0+ (1,0) [0|1] "" Vector__XXX
   SG_ 22_Fan_Current_Low_Fault : 22|1@0+ (1,0) [0|1] "" Vector__XXX
   SG_ 23_Fan_Current_High_Fault : 23|1@0+ (1,0) [0|1] "" Vector__XXX
   SG_ 24_Module_Volt_To_Cell_Volt_Comparison_Fault : 24|1@0+ (1,0) [0|1] "" Vector__XXX
   SG_ 25_Contactor_1_Stuck_On_Fault : 25|1@0+ (1,0) [0|1] "" Vector__XXX
   SG_ 26_Cell_Under_Voltage_B_Fault : 26|1@0+ (1,0) [0|1] "" Vector__XXX
   SG_ 27_Cell_Under_Voltage_A_Fault : 27|1@0+ (1,0) [0|1] "" Vector__XXX
   SG_ 28_Cell_Over_Voltage_B_Fault : 28|1@0+ (1,0) [0|1] "" Vector__XXX
   SG_ 29_Cell_Over_Voltage_A_Fault : 29|1@0+ (1,0) [0|1] "" Vector__XXX
   SG_ 30_Pack_Over_Voltge_Fault : 30|1@0+ (1,0) [0|1] "" Vector__XXX
   SG_ 31_SPI_Timeout_Fault : 31|1@0+ (1,0) [0|1] "" Vector__XXX
   SG_ 32_Countactor_2_Dropout_2nd_Fault : 32|1@0+ (1,0) [0|1] "" Vector__XXX
   SG_ 33_Countactor_2_Dropout_1st_Fault : 33|1@0+ (1,0) [0|1] "" Vector__XXX
   SG_ 34_Countactor_1_Dropout_2nd_Fault : 34|1@0+ (1,0) [0|1] "" Vector__XXX
   SG_ 35_Countactor_1_Dropout_1st_Fault : 35|1@0+ (1,0) [0|1] "" Vector__XXX
   SG_ 36_Secondary_Contactor_B_Open_Fault : 36|1@0+ (1,0) [0|1] "" Vector__XXX
   SG_ 37_No_PCU_Data_Received_Fault : 37|1@0+ (1,0) [0|1] "" Vector__XXX
   SG_ 38_Pack_Over_Current_Regulation_Fault : 38|1@0+ (1,0) [0|1] "" Vector__XXX
   SG_ 39_In_12V_Under_Voltage_Fault : 39|1@0+ (1,0) [0|1] "" Vector__XXX
   SG_ 40_Low_Level_Discharge_During_Charge_Fault : 40|1@0+ (1,0) [0|1] "" Vector__XXX
   SG_ 41_High_Level_Discharge_During_Charge_Fault : 41|1@0+ (1,0) [0|1] "" Vector__XXX
   SG_ 42_Internal_Slave_No_Data_Fault : 42|1@0+ (1,0) [0|1] "" Vector__XXX
   SG_ 43_Voltages_Mismach_Fault : 43|1@0+ (1,0) [0|1] "" Vector__XXX
   SG_ 44_In_12V_Under_Voltage_Warning : 44|1@0+ (1,0) [0|1] "" Vector__XXX
   SG_ 45_High_Contactor_Coil_Current_Fault : 45|1@0+ (1,0) [0|1] "" Vector__XXX
   SG_ 46_Cell_Voltage_Connection_Fault : 46|1@0+ (1,0) [0|1] "" Vector__XXX
   SG_ 47_Extreme_Cell_Under_Voltage_Fault : 47|1@0+ (1,0) [0|1] "" Vector__XXX
   SG_ 48_Low_Current_Sensor_Correlation_Fault : 48|1@0+ (1,0) [0|1] "" Vector__XXX
   SG_ 49_High_Current_Sensor_Correlation_Fault : 49|1@0+ (1,0) [0|1] "" Vector__XXX
   SG_ 50_Main_Contactor_Open_Timeout_Fault : 50|1@0+ (1,0) [0|1] "" Vector__XXX
   SG_ 51_PTC_Heater_Fault : 51|1@0+ (1,0) [0|1] "" Vector__XXX
   SG_ 52_Pack_Temperature_AD_Fault : 52|1@0+ (1,0) [0|1] "" Vector__XXX
   SG_ 53_Low_Module_Voltage_Fault : 52|1@0+ (1,0) [0|1] "" Vector__XXX

BO_ 1869 BMS_Diagnostic: 8 BMS

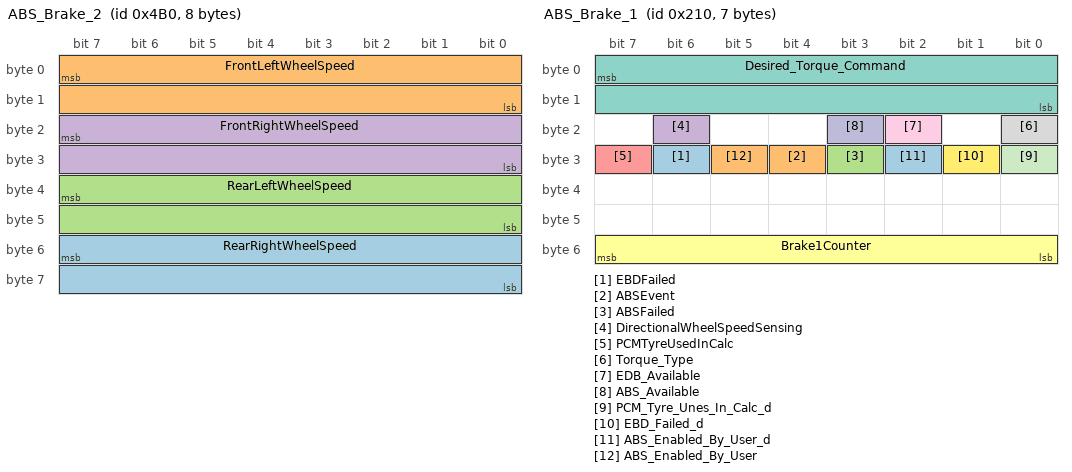
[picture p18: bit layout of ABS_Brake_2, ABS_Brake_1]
BO_ 1200 ABS_Brake_2: 8 ABS
   SG_ RearRightWheelSpeed : 55|16@0+ (0.00916667,-91.6667) [-91.6667|275] "km/h" Vector__XXX
   SG_ FrontLeftWheelSpeed : 7|16@0+ (0.00916667,-91.6667) [-91.6667|275] "km/h" Vector__XXX
   SG_ RearLeftWheelSpeed : 39|16@0+ (0.00916667,-91.6667) [-91.6667|275] "km/h" Vector__XXX
   SG_ FrontRightWheelSpeed : 23|16@0+ (0.00916667,-91.6667) [-91.6667|275] "km/h" Vector__XXX

BO_ 528 ABS_Brake_1: 7 ABS
   SG_ EBDFailed : 30|1@0+ (1,0) [0|1] "" PCU
   SG_ ABSEvent : 28|1@0+ (1,0) [0|1] "" PCU
   SG_ ABSFailed : 27|1@0+ (1,0) [0|1] "" PCU
   SG_ DirectionalWheelSpeedSensing : 22|1@0+ (1,0) [0|1] "" PCU
   SG_ PCMTyreUsedInCalc : 31|1@0+ (1,0) [0|1] "" PCU
   SG_ Brake1Counter : 55|8@0+ (1,0) [0|255] "" PCU
   SG_ Desired_Torque_Command : 7|16@0+ (1,512) [-512|65022] "" Vector__XXX
   SG_ Torque_Type : 16|1@0+ (1,0) [0|1] "" Vector__XXX
   SG_ EDB_Available : 18|1@0+ (1,0) [0|1] "" PCU
   SG_ ABS_Available : 19|1@0+ (1,0) [0|1] "" PCU
   SG_ PCM_Tyre_Unes_In_Calc_d : 24|1@0+ (1,0) [0|1] "" PCU
   SG_ EBD_Failed_d : 25|1@0+ (1,0) [0|1] "" PCU
   SG_ ABS_Enabled_By_User_d : 26|1@0+ (1,0) [0|1] "" PCU
   SG_ ABS_Enabled_By_User : 29|1@0+ (1,0) [0|1] "" PCU

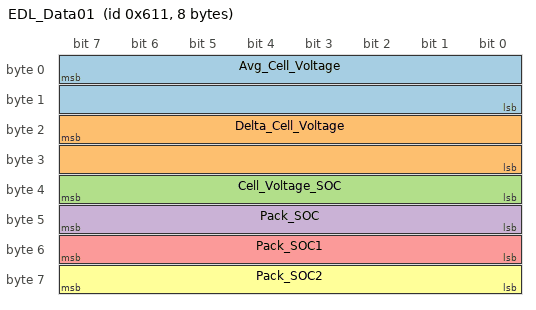
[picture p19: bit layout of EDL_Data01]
BO_ 1553 EDL_Data01: 8 EDL
   SG_ Avg_Cell_Voltage : 7|16@0+ (0.00244141,0) [0|65535] "_Volt" Vector__XXX
   SG_ Delta_Cell_Voltage : 23|16@0+ (0.00244141,0) [0|65535] "_Volt" Vector__XXX
   SG_ Cell_Voltage_SOC : 39|8@0+ (0.4,0) [0|255] "_%" Vector__XXX
   SG_ Pack_SOC : 47|8@0+ (0.4,0) [0|255] "_%" Vector__XXX
   SG_ Pack_SOC1 : 55|8@0+ (0.4,0) [0|255] "_%" Vector__XXX
   SG_ Pack_SOC2 : 63|8@0+ (0.4,0) [0|255] "_%" Vector__XXX

BO_ 1826 EDL_Latched_Fault_Data: 8 EDL
   SG_ 00_Bus_Voltage_AD_Fault : 0|1@0+ (1,0) [0|1] "" Vector__XXX
   SG_ 01_Pack_Voltage_AD_Fault : 1|1@0+ (1,0) [0|1] "" Vector__XXX
   SG_ 02_Pack_Current_B_hi_AD_Fault : 2|1@0+ (1,0) [0|1] "" Vector__XXX
   SG_ 03_Pack_Current_B_lo_AD_Fault : 3|1@0+ (1,0) [0|1] "" Vector__XXX
   SG_ 04_Pack_Current_A_hi_AD_Fault : 4|1@0+ (1,0) [0|1] "" Vector__XXX
   SG_ 05_Pack_Current_A_lo_AD_Fault : 5|1@0+ (1,0) [0|1] "" Vector__XXX
   SG_ 06_Board_Under_Temp_Fault : 6|1@0+ (1,0) [0|1] "" Vector__XXX
   SG_ 07_Secondary_Contactor_Stuck_On_Fault : 7|1@0+ (1,0) [0|1] "" Vector__XXX
   SG_ 08_Internal_Isolation_Fault : 8|1@0+ (1,0) [0|1] "" Vector__XXX
   SG_ 09_External_Isolation_Fault : 9|1@0+ (1,0) [0|1] "" Vector__XXX
   SG_ 10_Secondary_Contactor_A_Open_Fault : 10|1@0+ (1,0) [0|1] "" Vector__XXX
   SG_ 11_Contactor_Precharge_Short_Fault : 11|1@0+ (1,0) [0|1] "" Vector__XXX
   SG_ 12_Contactor_1_Dropout_Second_Fault : 12|1@0+ (1,0) [0|1] "" Vector__XXX
   SG_ 13_Contactor_1_Dropout_First_Fault : 13|1@0+ (1,0) [0|1] "" Vector__XXX
   SG_ 14_Contactor_Precharge_Retry_Fault : 14|1@0+ (1,0) [0|1] "" Vector__XXX
   SG_ 15_Contactor_Precharge_Timeout_Fault : 15|1@0+ (1,0) [0|1] "" Vector__XXX
   SG_ 16_Redundant_Cell_Voltage_Comparison_Fault : 16|1@0+ (1,0) [0|1] "" Vector__XXX
   SG_ 17_Contactor_2_Stuck_On_Fault : 17|1@0+ (1,0) [0|1] "" Vector__XXX
   SG_ 18_No_Charge_Current_Fault : 18|1@0+ (1,0) [0|1] "" Vector__XXX
   SG_ 19_Board_Over_Temp_Fault : 19|1@0+ (1,0) [0|1] "" Vector__XXX
   SG_ 20_Pack_Under_Temp_Fault : 20|1@0+ (1,0) [0|1] "" Vector__XXX
   SG_ 21_Pack_Over_Temp_Fault : 21|1@0+ (1,0) [0|1] "" Vector__XXX
   SG_ 22_Fan_Current_Low_Fault : 22|1@0+ (1,0) [0|1] "" Vector__XXX
   SG_ 23_Fan_Current_High_Fault : 23|1@0+ (1,0) [0|1] "" Vector__XXX
   SG_ 24_Module_Volt_To_Cell_Volt_Comparison_Fault : 24|1@0+ (1,0) [0|1] "" Vector__XXX
   SG_ 25_Contactor_1_Stuck_On_Fault : 25|1@0+ (1,0) [0|1] "" Vector__XXX
   SG_ 26_Cell_Under_Voltage_B_Fault : 26|1@0+ (1,0) [0|1] "" Vector__XXX
   SG_ 27_Cell_Under_Voltage_A_Fault : 27|1@0+ (1,0) [0|1] "" Vector__XXX
   SG_ 28_Cell_Over_Voltage_B_Fault : 28|1@0+ (1,0) [0|1] "" Vector__XXX
   SG_ 29_Cell_Over_Voltage_A_Fault : 29|1@0+ (1,0) [0|1] "" Vector__XXX
   SG_ 30_Pack_Over_Voltge_Fault : 30|1@0+ (1,0) [0|1] "" Vector__XXX
   SG_ 31_SPI_Timeout_Fault : 31|1@0+ (1,0) [0|1] "" Vector__XXX
   SG_ 32_Countactor_2_Dropout_2nd_Fault : 32|1@0+ (1,0) [0|1] "" Vector__XXX
   SG_ 33_Countactor_2_Dropout_1st_Fault : 33|1@0+ (1,0) [0|1] "" Vector__XXX
   SG_ 34_Countactor_1_Dropout_2nd_Fault : 34|1@0+ (1,0) [0|1] "" Vector__XXX
   SG_ 35_Countactor_1_Dropout_1st_Fault : 35|1@0+ (1,0) [0|1] "" Vector__XXX
   SG_ 36_Secondary_Contactor_B_Open_Fault : 36|1@0+ (1,0) [0|1] "" Vector__XXX
   SG_ 37_No_PCU_Data_Received_Fault : 37|1@0+ (1,0) [0|1] "" Vector__XXX
   SG_ 38_Pack_Over_Current_Regulation_Fault : 38|1@0+ (1,0) [0|1] "" Vector__XXX
   SG_ 39_In_12V_Under_Voltage_Fault : 39|1@0+ (1,0) [0|1] "" Vector__XXX
   SG_ 40_Low_Level_Discharge_During_Charge_Fault : 40|1@0+ (1,0) [0|1] "" Vector__XXX
   SG_ 41_High_Level_Discharge_During_Charge_Fault : 41|1@0+ (1,0) [0|1] "" Vector__XXX
   SG_ 42_Internal_Slave_No_Data_Fault : 42|1@0+ (1,0) [0|1] "" Vector__XXX
   SG_ 43_Voltages_Mismach_Fault : 43|1@0+ (1,0) [0|1] "" Vector__XXX
   SG_ 44_In_12V_Under_Voltage_Warning : 44|1@0+ (1,0) [0|1] "" Vector__XXX
   SG_ 45_High_Contactor_Coil_Current_Fault : 45|1@0+ (1,0) [0|1] "" Vector__XXX
   SG_ 46_Cell_Voltage_Connection_Fault : 46|1@0+ (1,0) [0|1] "" Vector__XXX
   SG_ 47_Extreme_Cell_Under_Voltage_Fault : 47|1@0+ (1,0) [0|1] "" Vector__XXX
   SG_ 48_Low_Current_Sensor_Correlation_Fault : 48|1@0+ (1,0) [0|1] "" Vector__XXX
   SG_ 49_High_Current_Sensor_Correlation_Fault : 49|1@0+ (1,0) [0|1] "" Vector__XXX
   SG_ 50_Main_Contactor_Open_Timeout_Fault : 50|1@0+ (1,0) [0|1] "" Vector__XXX
   SG_ 51_PTC_Heater_Fault : 51|1@0+ (1,0) [0|1] "" Vector__XXX
   SG_ 52_Pack_Temperature_AD_Fault : 52|1@0+ (1,0) [0|1] "" Vector__XXX
   SG_ 53_Low_Module_Voltage_Fault : 52|1@0+ (1,0) [0|1] "" Vector__XXX

BO_ 1825 EDL_Active_Fault_Data: 8 EDL
   SG_ 00_Bus_Voltage_AD_Fault : 0|1@0+ (1,0) [0|1] "" Vector__XXX
   SG_ 01_Pack_Voltage_AD_Fault : 1|1@0+ (1,0) [0|1] "" Vector__XXX
   SG_ 02_Pack_Current_B_hi_AD_Fault : 2|1@0+ (1,0) [0|1] "" Vector__XXX
   SG_ 03_Pack_Current_B_lo_AD_Fault : 3|1@0+ (1,0) [0|1] "" Vector__XXX
   SG_ 04_Pack_Current_A_hi_AD_Fault : 4|1@0+ (1,0) [0|1] "" Vector__XXX
   SG_ 05_Pack_Current_A_lo_AD_Fault : 5|1@0+ (1,0) [0|1] "" Vector__XXX
   SG_ 06_Board_Under_Temp_Fault : 6|1@0+ (1,0) [0|1] "" Vector__XXX
   SG_ 07_Secondary_Contactor_Stuck_On_Fault : 7|1@0+ (1,0) [0|1] "" Vector__XXX
   SG_ 08_Internal_Isolation_Fault : 8|1@0+ (1,0) [0|1] "" Vector__XXX
   SG_ 09_External_Isolation_Fault : 9|1@0+ (1,0) [0|1] "" Vector__XXX
   SG_ 10_Secondary_Contactor_A_Open_Fault : 10|1@0+ (1,0) [0|1] "" Vector__XXX
   SG_ 11_Contactor_Precharge_Short_Fault : 11|1@0+ (1,0) [0|1] "" Vector__XXX
   SG_ 12_Contactor_1_Dropout_Second_Fault : 12|1@0+ (1,0) [0|1] "" Vector__XXX
   SG_ 13_Contactor_1_Dropout_First_Fault : 13|1@0+ (1,0) [0|1] "" Vector__XXX
   SG_ 14_Contactor_Precharge_Retry_Fault : 14|1@0+ (1,0) [0|1] "" Vector__XXX
   SG_ 15_Contactor_Precharge_Timeout_Fault : 15|1@0+ (1,0) [0|1] "" Vector__XXX
   SG_ 16_Redundant_Cell_Voltage_Comparison_Fault : 16|1@0+ (1,0) [0|1] "" Vector__XXX
   SG_ 17_Contactor_2_Stuck_On_Fault : 17|1@0+ (1,0) [0|1] "" Vector__XXX
   SG_ 18_No_Charge_Current_Fault : 18|1@0+ (1,0) [0|1] "" Vector__XXX
   SG_ 19_Board_Over_Temp_Fault : 19|1@0+ (1,0) [0|1] "" Vector__XXX
   SG_ 20_Pack_Under_Temp_Fault : 20|1@0+ (1,0) [0|1] "" Vector__XXX
   SG_ 21_Pack_Over_Temp_Fault : 21|1@0+ (1,0) [0|1] "" Vector__XXX
   SG_ 22_Fan_Current_Low_Fault : 22|1@0+ (1,0) [0|1] "" Vector__XXX
   SG_ 23_Fan_Current_High_Fault : 23|1@0+ (1,0) [0|1] "" Vector__XXX
   SG_ 24_Module_Volt_To_Cell_Volt_Comparison_Fault : 24|1@0+ (1,0) [0|1] "" Vector__XXX
   SG_ 25_Contactor_1_Stuck_On_Fault : 25|1@0+ (1,0) [0|1] "" Vector__XXX
   SG_ 26_Cell_Under_Voltage_B_Fault : 26|1@0+ (1,0) [0|1] "" Vector__XXX
   SG_ 27_Cell_Under_Voltage_A_Fault : 27|1@0+ (1,0) [0|1] "" Vector__XXX
   SG_ 28_Cell_Over_Voltage_B_Fault : 28|1@0+ (1,0) [0|1] "" Vector__XXX
   SG_ 29_Cell_Over_Voltage_A_Fault : 29|1@0+ (1,0) [0|1] "" Vector__XXX
   SG_ 30_Pack_Over_Voltge_Fault : 30|1@0+ (1,0) [0|1] "" Vector__XXX
   SG_ 31_SPI_Timeout_Fault : 31|1@0+ (1,0) [0|1] "" Vector__XXX
   SG_ 32_Countactor_2_Dropout_2nd_Fault : 32|1@0+ (1,0) [0|1] "" Vector__XXX
   SG_ 33_Countactor_2_Dropout_1st_Fault : 33|1@0+ (1,0) [0|1] "" Vector__XXX
   SG_ 34_Countactor_1_Dropout_2nd_Fault : 34|1@0+ (1,0) [0|1] "" Vector__XXX
   SG_ 35_Countactor_1_Dropout_1st_Fault : 35|1@0+ (1,0) [0|1] "" Vector__XXX
   SG_ 36_Secondary_Contactor_B_Open_Fault : 36|1@0+ (1,0) [0|1] "" Vector__XXX
   SG_ 37_No_PCU_Data_Received_Fault : 37|1@0+ (1,0) [0|1] "" Vector__XXX
   SG_ 38_Pack_Over_Current_Regulation_Fault : 38|1@0+ (1,0) [0|1] "" Vector__XXX
   SG_ 39_In_12V_Under_Voltage_Fault : 39|1@0+ (1,0) [0|1] "" Vector__XXX
   SG_ 40_Low_Level_Discharge_During_Charge_Fault : 40|1@0+ (1,0) [0|1] "" Vector__XXX
   SG_ 41_High_Level_Discharge_During_Charge_Fault : 41|1@0+ (1,0) [0|1] "" Vector__XXX
   SG_ 42_Internal_Slave_No_Data_Fault : 42|1@0+ (1,0) [0|1] "" Vector__XXX
   SG_ 43_Voltages_Mismach_Fault : 43|1@0+ (1,0) [0|1] "" Vector__XXX
   SG_ 44_In_12V_Under_Voltage_Warning : 44|1@0+ (1,0) [0|1] "" Vector__XXX
   SG_ 45_High_Contactor_Coil_Current_Fault : 45|1@0+ (1,0) [0|1] "" Vector__XXX
   SG_ 46_Cell_Voltage_Connection_Fault : 46|1@0+ (1,0) [0|1] "" Vector__XXX
   SG_ 47_Extreme_Cell_Under_Voltage_Fault : 47|1@0+ (1,0) [0|1] "" Vector__XXX
   SG_ 48_Low_Current_Sensor_Correlation_Fault : 48|1@0+ (1,0) [0|1] "" Vector__XXX
   SG_ 49_High_Current_Sensor_Correlation_Fault : 49|1@0+ (1,0) [0|1] "" Vector__XXX
   SG_ 50_Main_Contactor_Open_Timeout_Fault : 50|1@0+ (1,0) [0|1] "" Vector__XXX
   SG_ 51_PTC_Heater_Fault : 51|1@0+ (1,0) [0|1] "" Vector__XXX
   SG_ 52_Pack_Temperature_AD_Fault : 52|1@0+ (1,0) [0|1] "" Vector__XXX
   SG_ 53_Low_Module_Voltage_Fault : 52|1@0+ (1,0) [0|1] "" Vector__XXX

BO_ 615 PCU_TIV: 0 Vector__XXX
   SG_ Traction_Enabled : 7|1@0+ (1,0) [0|1] "" Vector__XXX
   SG_ Brake_Active : 6|1@0+ (1,0) [0|1] "" Vector__XXX
   SG_ PCU_Emergency : 5|1@0+ (1,0) [0|1] "" Vector__XXX
   SG_ Gear_Drive : 4|1@0+ (1,0) [0|1] "" Vector__XXX
   SG_ Gear_Economy : 3|1@0+ (1,0) [0|1] "" Vector__XXX
   SG_ Gear_Reverse : 2|1@0+ (1,0) [0|1] "" Vector__XXX
   SG_ Gear_Parking : 1|1@0+ (1,0) [0|1] "" Vector__XXX
   SG_ Hand_Brake_Active : 0|1@0+ (1,0) [0|1] "" Vector__XXX

BA_DEF_ BO_ "GenMsgCycleTimeFast" INT 0 0;
BA_DEF_ BO_ "GenMsgCycleTime" INT 0 0;
BA_DEF_ BO_ "GenMsgSendType" ENUM "Cyclic","NotUsed","NotUsed","NotUsed","NotUsed","NotUsed","NotUsed","IfActive","NoMsgSendType","NotUsed";
BA_DEF_ SG_ "GenSigStartValue" FLOAT 0 0;
BA_DEF_ SG_ "GenSigCycleTimeActive" INT 0 0;
BA_DEF_ SG_ "GenSigCycleTime" INT 0 0;
BA_DEF_ SG_ "GenSigSendType" ENUM "Cyclic","NotUsed","NotUsed","NotUsed","NotUsed","NotUsed","NotUsed","IfActive","NoMsgSendType","NotUsed","Cyclic","NotUsed","NotUsed","NotUsed","NotUsed","NotUsed","NotUsed","IfActive","NoMsgSendType","NotUsed","Cyclic","NotUsed","NotUsed","NotUsed","NotUsed","NotUsed","NotUsed","IfActive","NoMsgSendType","NotUsed","Cyclic","NotUsed","NotUsed","NotUsed","NotUsed","NotUsed","NotUsed","IfActive","NoMsgSendType","NotUsed","Cyclic","NotUsed","NotUsed","NotUsed","NotUsed","NotUsed","NotUsed","IfActive","NoMsgSendType","NotUsed","Cyclic","NotUsed","NotUsed","NotUsed","NotUsed","NotUsed","NotUsed","IfActive","NoMsgSendType","NotUsed","Cyclic","NotUsed","NotUsed","NotUsed","NotUsed","NotUsed","NotUsed","IfActive","NoMsgSendType","NotUsed","Cyclic","NotUsed","NotUsed","NotUsed","NotUsed","NotUsed","NotUsed","IfActive","NoMsgSendType","NotUsed","Cyclic","NotUsed","NotUsed","NotUsed","NotUsed","NotUsed","NotUsed","IfActive","NoMsgSendType","NotUsed","Cyclic","NotUsed","NotUsed","NotUsed","NotUsed","NotUsed","NotUsed","IfActive","NoMsgSendType","NotUsed","Cyclic","NotUsed","NotUsed","NotUsed","NotUsed","NotUsed","NotUsed","IfActive","NoMsgSendType","NotUsed","Cyclic","NotUsed","NotUsed","NotUsed","NotUsed","NotUsed","NotUsed","IfActive","NoMsgSendType","NotUsed","Cyclic","NotUsed","NotUsed","NotUsed","NotUsed","NotUsed","NotUsed","IfActive","NoMsgSendType","NotUsed","Cyclic","NotUsed","NotUsed","NotUsed","NotUsed","NotUsed","NotUsed","IfActive","NoMsgSendType","NotUsed","Cyclic","NotUsed","NotUsed","NotUsed","NotUsed","NotUsed","NotUsed","IfActive","NoMsgSendType","NotUsed","Cyclic","NotUsed","NotUsed","NotUsed","NotUsed","NotUsed","NotUsed","IfActive","NoMsgSendType","NotUsed","Cyclic","NotUsed","NotUsed","NotUsed","NotUsed","NotUsed","NotUsed","IfActive","NoMsgSendType","NotUsed","Cyclic","NotUsed","NotUsed","NotUsed","NotUsed","NotUsed","NotUsed","IfActive","NoMsgSendType","NotUsed","Cyclic","NotUsed","NotUsed","NotUsed","NotUsed","NotUsed","NotUsed","IfActive","NoMsgSendType","NotUsed","Cyclic","NotUsed","NotUsed","NotUsed","NotUsed","NotUsed","NotUsed","IfActive","NoMsgSendType","NotUsed","Cyclic","NotUsed","NotUsed","NotUsed","NotUsed","NotUsed","NotUsed","IfActive","NoMsgSendType","NotUsed","Cyclic","NotUsed","NotUsed","NotUsed","NotUsed","NotUsed","NotUsed","IfActive","NoMsgSendType","NotUsed","Cyclic","NotUsed","NotUsed","NotUsed","NotUsed","NotUsed","NotUsed","IfActive","NoMsgSendType","NotUsed","Cyclic","OnWrite","OnWriteWithRepetition","OnChange","OnChangeWithRepetition","IfActive","IfActiveWithRepetition","NoSigSendType","NotUsed","NotUsed","NotUsed","NotUsed","NotUsed";
BA_DEF_ "Baudrate" INT 0 1;
BA_DEF_ BO_ "GenMsgBackgroundColor" STRING ;
BA_DEF_ BO_ "GenMsgForegroundColor" STRING ;
BA_DEF_ BO_ "labelfilters" INT 0 0;
BA_DEF_ BO_ "labelfilters" INT 0 0;
BA_DEF_ BO_ "labelfilters" INT 0 0;
BA_DEF_ BO_ "labelfilters" INT 0 0;
BA_DEF_ BO_ "labelfilters" INT 0 0;
BA_DEF_ BO_ "labelfilters" INT 0 0;
BA_DEF_ BO_ "labelfilters" INT 0 0;
BA_DEF_ BO_ "labelfilters" INT 0 0;
BA_DEF_ BO_ "labelfilters" INT 0 0;
BA_DEF_ BO_ "labelfilters" INT 0 0;
BA_DEF_ BO_ "labelfilters" INT 0 0;
BA_DEF_ BO_ "labelfilters" INT 0 0;
BA_DEF_ BO_ "labelfilters" INT 0 0;
BA_DEF_ BO_ "labelfilters" INT 0 0;
BA_DEF_ BO_ "labelfilters" INT 0 0;
BA_DEF_ BO_ "labelfilters" INT 0 0;
BA_DEF_ BO_ "labelfilters" INT 0 0;
BA_DEF_ BO_ "labelfilters" INT 0 0;
BA_DEF_ BO_ "labelfilters" INT 0 0;
BA_DEF_ BO_ "labelfilters" INT 0 0;
BA_DEF_ BO_ "labelfilters" INT 0 0;
BA_DEF_ BO_ "labelfilters" INT 0 0;
BA_DEF_ BO_ "labelfilters" INT 0 0;
BA_DEF_ BO_ "labelfilters" INT 0 0;
BA_DEF_ BO_ "labelfilters" INT 0 0;
BA_DEF_ BO_ "labelfilters" INT 0 0;
BA_DEF_ BO_ "labelfilters" INT 0 0;
BA_DEF_ BO_ "filterlabeling" INT 0 0;
BA_ "GenMsgCycleTime" BO_ 1091 200;
BA_ "GenMsgCycleTimeFast" BO_ 1091 200;
BA_ "GenMsgCycleTime" BO_ 1092 200;
BA_ "GenMsgCycleTimeFast" BO_ 1092 200;
BA_ "GenMsgCycleTime" BO_ 1088 200;
BA_ "GenMsgCycleTimeFast" BO_ 1088 200;
BA_ "GenMsgCycleTime" BO_ 1089 200;
BA_ "GenMsgCycleTimeFast" BO_ 1089 200;
BA_ "GenMsgCycleTime" BO_ 1090 200;
BA_ "GenMsgCycleTimeFast" BO_ 1090 200;
BA_ "GenMsgCycleTime" BO_ 929 500;
BA_ "GenMsgCycleTimeFast" BO_ 929 500;
BA_ "GenMsgCycleTime" BO_ 928 500;
BA_ "GenMsgCycleTimeFast" BO_ 928 500;
BA_ "GenMsgCycleTime" BO_ 592 100;
BA_ "GenMsgCycleTimeFast" BO_ 592 100;
BA_ "GenMsgCycleTime" BO_ 2001 100;
BA_ "GenMsgCycleTimeFast" BO_ 2001 100;
BA_ "GenMsgCycleTime" BO_ 836 200;
BA_ "GenMsgCycleTimeFast" BO_ 836 100;
BA_ "GenMsgCycleTime" BO_ 837 200;
BA_ "GenMsgCycleTimeFast" BO_ 837 100;
BA_ "GenMsgCycleTime" BO_ 1922 100;
BA_ "GenMsgCycleTimeFast" BO_ 1922 100;
BA_ "GenMsgCycleTime" BO_ 838 100;
BA_ "GenMsgCycleTimeFast" BO_ 838 100;
BA_ "GenMsgCycleTime" BO_ 1941 100;
BA_ "GenMsgCycleTimeFast" BO_ 1941 100;
BA_ "GenMsgCycleTime" BO_ 1525 100;
BA_ "GenMsgCycleTimeFast" BO_ 1525 100;
BA_ "GenMsgCycleTime" BO_ 1493 100;
BA_ "GenMsgCycleTimeFast" BO_ 1493 100;
BA_ "GenMsgCycleTime" BO_ 1631 100;
BA_ "GenMsgCycleTimeFast" BO_ 1631 100;
BA_ "GenMsgCycleTime" BO_ 1630 100;
BA_ "GenMsgCycleTimeFast" BO_ 1630 100;
BA_ "GenMsgCycleTime" BO_ 1629 100;
BA_ "GenMsgCycleTimeFast" BO_ 1629 100;
BA_ "GenMsgCycleTime" BO_ 1628 100;
BA_ "GenMsgCycleTimeFast" BO_ 1628 100;
BA_ "GenMsgCycleTime" BO_ 1627 100;
BA_ "GenMsgCycleTimeFast" BO_ 1627 100;
BA_ "GenMsgCycleTime" BO_ 1626 100;
BA_ "GenMsgCycleTimeFast" BO_ 1626 100;
BA_ "GenMsgCycleTime" BO_ 1625 100;
BA_ "GenMsgCycleTimeFast" BO_ 1625 100;
BA_ "GenMsgCycleTime" BO_ 1624 100;
BA_ "GenMsgCycleTimeFast" BO_ 1624 100;
BA_ "GenMsgCycleTime" BO_ 1623 100;
BA_ "GenMsgCycleTimeFast" BO_ 1623 100;
BA_ "GenMsgCycleTime" BO_ 1622 100;
BA_ "GenMsgCycleTimeFast" BO_ 1622 100;
BA_ "GenMsgCycleTime" BO_ 1621 100;
BA_ "GenMsgCycleTimeFast" BO_ 1621 100;
BA_ "GenMsgCycleTime" BO_ 1620 100;
BA_ "GenMsgCycleTimeFast" BO_ 1620 100;
BA_ "GenMsgCycleTime" BO_ 1619 100;
BA_ "GenMsgCycleTimeFast" BO_ 1619 100;
BA_ "GenMsgCycleTime" BO_ 1618 100;
BA_ "GenMsgCycleTimeFast" BO_ 1618 100;
BA_ "GenMsgCycleTime" BO_ 1617 100;
BA_ "GenMsgCycleTimeFast" BO_ 1617 100;
BA_ "GenMsgCycleTime" BO_ 1616 100;
BA_ "GenMsgCycleTimeFast" BO_ 1616 100;
BA_ "GenMsgCycleTime" BO_ 1615 100;
BA_ "GenMsgCycleTimeFast" BO_ 1615 100;
BA_ "GenMsgCycleTime" BO_ 1614 100;
BA_ "GenMsgCycleTimeFast" BO_ 1614 100;
BA_ "GenMsgCycleTime" BO_ 645 100;
BA_ "GenMsgCycleTimeFast" BO_ 645 100;
BA_ "GenMsgCycleTime" BO_ 1613 100;
BA_ "GenMsgCycleTimeFast" BO_ 1613 100;
BA_ "GenMsgCycleTime" BO_ 1612 100;
BA_ "GenMsgCycleTimeFast" BO_ 1612 100;
BA_ "GenMsgCycleTime" BO_ 1611 100;
BA_ "GenMsgCycleTimeFast" BO_ 1611 100;
BA_ "GenMsgCycleTime" BO_ 1610 100;
BA_ "GenMsgCycleTimeFast" BO_ 1610 100;
BA_ "GenMsgCycleTime" BO_ 1609 100;
BA_ "GenMsgCycleTimeFast" BO_ 1609 100;
BA_ "GenMsgCycleTime" BO_ 1608 100;
BA_ "GenMsgCycleTimeFast" BO_ 1608 100;
BA_ "GenMsgCycleTime" BO_ 1607 100;
BA_ "GenMsgCycleTimeFast" BO_ 1607 100;
BA_ "GenMsgCycleTime" BO_ 1606 200;
BA_ "GenMsgCycleTimeFast" BO_ 1606 100;
BA_ "GenMsgCycleTime" BO_ 1605 100;
BA_ "GenMsgCycleTimeFast" BO_ 1605 100;
BA_ "GenMsgCycleTime" BO_ 1604 200;
BA_ "GenMsgCycleTimeFast" BO_ 1604 100;
BA_ "GenMsgCycleTime" BO_ 513 100;
BA_ "GenMsgCycleTimeFast" BO_ 513 100;
BA_ "GenMsgCycleTime" BO_ 1603 100;
BA_ "GenMsgCycleTimeFast" BO_ 1603 100;
BA_ "GenMsgCycleTime" BO_ 1602 200;
BA_ "GenMsgCycleTimeFast" BO_ 1602 100;
BA_ "GenMsgCycleTime" BO_ 1601 100;
BA_ "GenMsgCycleTimeFast" BO_ 1601 100;
BA_ "GenMsgCycleTime" BO_ 1600 100;
BA_ "GenMsgCycleTimeFast" BO_ 1600 100;
BA_ "GenMsgCycleTime" BO_ 1584 100;
BA_ "GenMsgCycleTimeFast" BO_ 1584 100;
BA_ "GenMsgCycleTime" BO_ 831 100;
BA_ "GenMsgCycleTimeFast" BO_ 831 100;
BA_ "GenMsgCycleTime" BO_ 830 100;
BA_ "GenMsgCycleTimeFast" BO_ 830 100;
BA_ "GenMsgCycleTime" BO_ 829 100;
BA_ "GenMsgCycleTimeFast" BO_ 829 100;
BA_ "GenMsgCycleTime" BO_ 828 100;
BA_ "GenMsgCycleTimeFast" BO_ 828 100;
BA_ "GenMsgCycleTime" BO_ 827 100;
BA_ "GenMsgCycleTimeFast" BO_ 827 100;
BA_ "GenMsgCycleTime" BO_ 512 100;
BA_ "GenMsgCycleTimeFast" BO_ 512 100;
BA_ "GenMsgCycleTime" BO_ 826 100;
BA_ "GenMsgCycleTimeFast" BO_ 826 100;
BA_ "GenMsgCycleTime" BO_ 825 100;
BA_ "GenMsgCycleTimeFast" BO_ 825 100;
BA_ "GenMsgCycleTime" BO_ 824 100;
BA_ "GenMsgCycleTimeFast" BO_ 824 100;
BA_ "GenMsgCycleTime" BO_ 823 100;
BA_ "GenMsgCycleTimeFast" BO_ 823 100;
BA_ "GenMsgCycleTime" BO_ 822 100;
BA_ "GenMsgCycleTimeFast" BO_ 822 100;
BA_ "GenMsgCycleTime" BO_ 821 100;
BA_ "GenMsgCycleTimeFast" BO_ 821 100;
BA_ "GenMsgCycleTime" BO_ 820 100;
BA_ "GenMsgCycleTimeFast" BO_ 820 100;
BA_ "GenMsgCycleTime" BO_ 819 100;
BA_ "GenMsgCycleTimeFast" BO_ 819 100;
BA_ "GenMsgCycleTime" BO_ 818 100;
BA_ "GenMsgCycleTimeFast" BO_ 818 100;
BA_ "GenMsgCycleTime" BO_ 817 100;
BA_ "GenMsgCycleTimeFast" BO_ 817 100;
BA_ "GenMsgCycleTime" BO_ 1568 100;
BA_ "GenMsgCycleTimeFast" BO_ 1568 100;
BA_ "GenMsgCycleTime" BO_ 816 100;
BA_ "GenMsgCycleTimeFast" BO_ 816 100;
BA_ "GenMsgCycleTime" BO_ 815 100;
BA_ "GenMsgCycleTimeFast" BO_ 815 100;
BA_ "GenMsgCycleTime" BO_ 814 100;
BA_ "GenMsgCycleTimeFast" BO_ 814 100;
BA_ "GenMsgCycleTime" BO_ 813 100;
BA_ "GenMsgCycleTimeFast" BO_ 813 100;
BA_ "GenMsgCycleTime" BO_ 812 100;
BA_ "GenMsgCycleTimeFast" BO_ 812 100;
BA_ "GenMsgCycleTime" BO_ 811 100;
BA_ "GenMsgCycleTimeFast" BO_ 811 100;
BA_ "GenMsgCycleTime" BO_ 810 100;
BA_ "GenMsgCycleTimeFast" BO_ 810 100;
BA_ "GenMsgCycleTime" BO_ 809 100;
BA_ "GenMsgCycleTimeFast" BO_ 809 100;
BA_ "GenMsgCycleTime" BO_ 808 100;
BA_ "GenMsgCycleTimeFast" BO_ 808 100;
BA_ "GenMsgCycleTime" BO_ 1892 100;
BA_ "GenMsgCycleTimeFast" BO_ 1892 100;
BA_ "GenMsgCycleTime" BO_ 1888 100;
BA_ "GenMsgCycleTimeFast" BO_ 1888 100;
BA_ "GenMsgCycleTime" BO_ 807 100;
BA_ "GenMsgCycleTimeFast" BO_ 807 100;
BA_ "GenMsgCycleTime" BO_ 1072 100;
BA_ "GenMsgCycleTimeFast" BO_ 1072 100;
BA_ "GenMsgCycleTime" BO_ 1034 100;
BA_ "GenMsgCycleTimeFast" BO_ 1034 100;
BA_ "GenMsgCycleTime" BO_ 1585 100;
BA_ "GenMsgCycleTimeFast" BO_ 1585 100;
BA_ "GenMsgCycleTime" BO_ 1569 100;
BA_ "GenMsgCycleTimeFast" BO_ 1569 100;
BA_ "GenMsgCycleTime" BO_ 857 100;
BA_ "GenMsgCycleTimeFast" BO_ 857 100;
BA_ "GenMsgCycleTime" BO_ 1567 100;
BA_ "GenMsgCycleTimeFast" BO_ 1567 100;
BA_ "GenMsgCycleTime" BO_ 1566 100;
BA_ "GenMsgCycleTimeFast" BO_ 1566 100;
BA_ "GenMsgCycleTime" BO_ 806 100;
BA_ "GenMsgCycleTimeFast" BO_ 806 100;
BA_ "GenMsgCycleTime" BO_ 1565 100;
BA_ "GenMsgCycleTimeFast" BO_ 1565 100;
BA_ "GenMsgCycleTime" BO_ 1564 100;
BA_ "GenMsgCycleTimeFast" BO_ 1564 100;
BA_ "GenMsgCycleTime" BO_ 1563 100;
BA_ "GenMsgCycleTimeFast" BO_ 1563 100;
BA_ "GenMsgCycleTime" BO_ 1562 100;
BA_ "GenMsgCycleTimeFast" BO_ 1562 100;
BA_ "GenMsgCycleTime" BO_ 1561 100;
BA_ "GenMsgCycleTimeFast" BO_ 1561 100;
BA_ "GenMsgCycleTime" BO_ 1560 100;
BA_ "GenMsgCycleTimeFast" BO_ 1560 100;
BA_ "GenMsgCycleTime" BO_ 1559 100;
BA_ "GenMsgCycleTimeFast" BO_ 1559 100;
BA_ "GenMsgCycleTime" BO_ 1558 100;
BA_ "GenMsgCycleTimeFast" BO_ 1558 100;
BA_ "GenMsgCycleTime" BO_ 1557 100;
BA_ "GenMsgCycleTimeFast" BO_ 1557 100;
BA_ "GenMsgCycleTime" BO_ 1556 100;
BA_ "GenMsgCycleTimeFast" BO_ 1556 100;
BA_ "GenMsgCycleTime" BO_ 805 100;
BA_ "GenMsgCycleTimeFast" BO_ 805 100;
BA_ "GenMsgCycleTime" BO_ 1555 100;
BA_ "GenMsgCycleTimeFast" BO_ 1555 100;
BA_ "GenMsgCycleTime" BO_ 1554 100;
BA_ "GenMsgCycleTimeFast" BO_ 1554 100;
BA_ "GenMsgCycleTime" BO_ 1552 100;
BA_ "GenMsgCycleTimeFast" BO_ 1552 100;
BA_ "GenMsgCycleTime" BO_ 1551 100;
BA_ "GenMsgCycleTimeFast" BO_ 1551 100;
BA_ "GenMsgCycleTime" BO_ 1550 100;
BA_ "GenMsgCycleTimeFast" BO_ 1550 100;
BA_ "GenMsgCycleTime" BO_ 1549 100;
BA_ "GenMsgCycleTimeFast" BO_ 1549 100;
BA_ "GenMsgCycleTime" BO_ 1548 100;
BA_ "GenMsgCycleTimeFast" BO_ 1548 100;
BA_ "GenMsgCycleTime" BO_ 1547 100;
BA_ "GenMsgCycleTimeFast" BO_ 1547 100;
BA_ "GenMsgCycleTime" BO_ 804 100;
BA_ "GenMsgCycleTimeFast" BO_ 804 100;
BA_ "GenMsgCycleTime" BO_ 1546 100;
BA_ "GenMsgCycleTimeFast" BO_ 1546 100;
BA_ "GenMsgCycleTime" BO_ 1545 100;
BA_ "GenMsgCycleTimeFast" BO_ 1545 100;
BA_ "GenMsgCycleTime" BO_ 1544 100;
BA_ "GenMsgCycleTimeFast" BO_ 1544 100;
BA_ "GenMsgCycleTime" BO_ 1543 100;
BA_ "GenMsgCycleTimeFast" BO_ 1543 100;
BA_ "GenMsgCycleTime" BO_ 1542 100;
BA_ "GenMsgCycleTimeFast" BO_ 1542 100;
BA_ "GenMsgCycleTime" BO_ 1541 100;
BA_ "GenMsgCycleTimeFast" BO_ 1541 100;
BA_ "GenMsgCycleTime" BO_ 1540 100;
BA_ "GenMsgCycleTimeFast" BO_ 1540 100;
BA_ "GenMsgCycleTime" BO_ 1539 100;
BA_ "GenMsgCycleTimeFast" BO_ 1539 100;
BA_ "GenMsgCycleTime" BO_ 1538 100;
BA_ "GenMsgCycleTimeFast" BO_ 1538 100;
BA_ "GenMsgCycleTime" BO_ 1537 100;
BA_ "GenMsgCycleTimeFast" BO_ 1537 100;
BA_ "GenMsgCycleTime" BO_ 803 100;
BA_ "GenMsgCycleTimeFast" BO_ 803 100;
BA_ "GenMsgCycleTime" BO_ 1536 100;
BA_ "GenMsgCycleTimeFast" BO_ 1536 100;
BA_ "GenMsgCycleTime" BO_ 1535 100;
BA_ "GenMsgCycleTimeFast" BO_ 1535 100;
BA_ "GenMsgCycleTime" BO_ 1534 100;
BA_ "GenMsgCycleTimeFast" BO_ 1534 100;
BA_ "GenMsgCycleTime" BO_ 1533 100;
BA_ "GenMsgCycleTimeFast" BO_ 1533 100;
BA_ "GenMsgCycleTime" BO_ 1532 100;
BA_ "GenMsgCycleTimeFast" BO_ 1532 100;
BA_ "GenMsgCycleTime" BO_ 1531 100;
BA_ "GenMsgCycleTimeFast" BO_ 1531 100;
BA_ "GenMsgCycleTime" BO_ 1530 100;
BA_ "GenMsgCycleTimeFast" BO_ 1530 100;
BA_ "GenMsgCycleTime" BO_ 1529 100;
BA_ "GenMsgCycleTimeFast" BO_ 1529 100;
BA_ "GenMsgCycleTime" BO_ 1528 100;
BA_ "GenMsgCycleTimeFast" BO_ 1528 100;
BA_ "GenMsgCycleTime" BO_ 1527 100;
BA_ "GenMsgCycleTimeFast" BO_ 1527 100;
BA_ "GenMsgCycleTime" BO_ 802 100;
BA_ "GenMsgCycleTimeFast" BO_ 802 100;
BA_ "GenMsgCycleTime" BO_ 1526 100;
BA_ "GenMsgCycleTimeFast" BO_ 1526 100;
BA_ "GenMsgCycleTime" BO_ 1524 100;
BA_ "GenMsgCycleTimeFast" BO_ 1524 100;
BA_ "GenMsgCycleTime" BO_ 1523 100;
BA_ "GenMsgCycleTimeFast" BO_ 1523 100;
BA_ "GenMsgCycleTime" BO_ 1522 100;
BA_ "GenMsgCycleTimeFast" BO_ 1522 100;
BA_ "GenMsgCycleTime" BO_ 1521 100;
BA_ "GenMsgCycleTimeFast" BO_ 1521 100;
BA_ "GenMsgCycleTime" BO_ 1520 100;
BA_ "GenMsgCycleTimeFast" BO_ 1520 100;
BA_ "GenMsgCycleTime" BO_ 1519 100;
BA_ "GenMsgCycleTimeFast" BO_ 1519 100;
BA_ "GenMsgCycleTime" BO_ 1518 100;
BA_ "GenMsgCycleTimeFast" BO_ 1518 100;
BA_ "GenMsgCycleTime" BO_ 1517 100;
BA_ "GenMsgCycleTimeFast" BO_ 1517 100;
BA_ "GenMsgCycleTime" BO_ 1516 100;
BA_ "GenMsgCycleTimeFast" BO_ 1516 100;
BA_ "GenMsgCycleTime" BO_ 801 100;
BA_ "GenMsgCycleTimeFast" BO_ 801 100;
BA_ "GenMsgCycleTime" BO_ 1515 100;
BA_ "GenMsgCycleTimeFast" BO_ 1515 100;
BA_ "GenMsgCycleTime" BO_ 1514 100;
BA_ "GenMsgCycleTimeFast" BO_ 1514 100;
BA_ "GenMsgCycleTime" BO_ 1513 100;
BA_ "GenMsgCycleTimeFast" BO_ 1513 100;
BA_ "GenMsgCycleTime" BO_ 1512 100;
BA_ "GenMsgCycleTimeFast" BO_ 1512 100;
BA_ "GenMsgCycleTime" BO_ 1511 100;
BA_ "GenMsgCycleTimeFast" BO_ 1511 100;
BA_ "GenMsgCycleTime" BO_ 1510 100;
BA_ "GenMsgCycleTimeFast" BO_ 1510 100;
BA_ "GenMsgCycleTime" BO_ 1509 100;
BA_ "GenMsgCycleTimeFast" BO_ 1509 100;
BA_ "GenMsgCycleTime" BO_ 1508 100;
BA_ "GenMsgCycleTimeFast" BO_ 1508 100;
BA_ "GenMsgCycleTime" BO_ 1507 100;
BA_ "GenMsgCycleTimeFast" BO_ 1507 100;
BA_ "GenMsgCycleTime" BO_ 1506 100;
BA_ "GenMsgCycleTimeFast" BO_ 1506 100;
BA_ "GenMsgCycleTime" BO_ 800 100;
BA_ "GenMsgCycleTimeFast" BO_ 800 100;
BA_ "GenMsgCycleTime" BO_ 1505 100;
BA_ "GenMsgCycleTimeFast" BO_ 1505 100;
BA_ "GenMsgCycleTime" BO_ 1504 100;
BA_ "GenMsgCycleTimeFast" BO_ 1504 100;
BA_ "GenMsgCycleTime" BO_ 1503 100;
BA_ "GenMsgCycleTimeFast" BO_ 1503 100;
BA_ "GenMsgCycleTime" BO_ 1502 100;
BA_ "GenMsgCycleTimeFast" BO_ 1502 100;
BA_ "GenMsgCycleTime" BO_ 1501 100;
BA_ "GenMsgCycleTimeFast" BO_ 1501 100;
BA_ "GenMsgCycleTime" BO_ 1500 100;
BA_ "GenMsgCycleTimeFast" BO_ 1500 100;
BA_ "GenMsgCycleTime" BO_ 1499 100;
BA_ "GenMsgCycleTimeFast" BO_ 1499 100;
BA_ "GenMsgCycleTime" BO_ 1498 100;
BA_ "GenMsgCycleTimeFast" BO_ 1498 100;
BA_ "GenMsgCycleTime" BO_ 1497 100;
BA_ "GenMsgCycleTimeFast" BO_ 1497 100;
BA_ "GenMsgCycleTime" BO_ 1496 100;
BA_ "GenMsgCycleTimeFast" BO_ 1496 100;
BA_ "GenMsgCycleTime" BO_ 799 100;
BA_ "GenMsgCycleTimeFast" BO_ 799 100;
BA_ "GenMsgCycleTime" BO_ 1495 100;
BA_ "GenMsgCycleTimeFast" BO_ 1495 100;
BA_ "GenMsgCycleTime" BO_ 1494 100;
BA_ "GenMsgCycleTimeFast" BO_ 1494 100;
BA_ "GenMsgCycleTime" BO_ 1492 100;
BA_ "GenMsgCycleTimeFast" BO_ 1492 100;
BA_ "GenMsgCycleTime" BO_ 1491 100;
BA_ "GenMsgCycleTimeFast" BO_ 1491 100;
BA_ "GenMsgCycleTime" BO_ 1490 100;
BA_ "GenMsgCycleTimeFast" BO_ 1490 100;
BA_ "GenMsgCycleTime" BO_ 1489 100;
BA_ "GenMsgCycleTimeFast" BO_ 1489 100;
BA_ "GenMsgCycleTime" BO_ 1488 100;
BA_ "GenMsgCycleTimeFast" BO_ 1488 100;
BA_ "GenMsgCycleTime" BO_ 1487 100;
BA_ "GenMsgCycleTimeFast" BO_ 1487 100;
BA_ "GenMsgCycleTime" BO_ 1486 100;
BA_ "GenMsgCycleTimeFast" BO_ 1486 100;
BA_ "GenMsgCycleTime" BO_ 1485 100;
BA_ "GenMsgCycleTimeFast" BO_ 1485 100;
BA_ "GenMsgCycleTime" BO_ 798 100;
BA_ "GenMsgCycleTimeFast" BO_ 798 100;
BA_ "GenMsgCycleTime" BO_ 1484 100;
BA_ "GenMsgCycleTimeFast" BO_ 1484 100;
BA_ "GenMsgCycleTime" BO_ 1483 100;
BA_ "GenMsgCycleTimeFast" BO_ 1483 100;
BA_ "GenMsgCycleTime" BO_ 1482 100;
BA_ "GenMsgCycleTimeFast" BO_ 1482 100;
BA_ "GenMsgCycleTime" BO_ 1481 100;
BA_ "GenMsgCycleTimeFast" BO_ 1481 100;
BA_ "GenMsgCycleTime" BO_ 1480 100;
BA_ "GenMsgCycleTimeFast" BO_ 1480 100;
BA_ "GenMsgCycleTime" BO_ 1479 100;
BA_ "GenMsgCycleTimeFast" BO_ 1479 100;
BA_ "GenMsgCycleTime" BO_ 1478 100;
BA_ "GenMsgCycleTimeFast" BO_ 1478 100;
BA_ "GenMsgCycleTime" BO_ 1477 100;
BA_ "GenMsgCycleTimeFast" BO_ 1477 100;
BA_ "GenMsgCycleTime" BO_ 1476 100;
BA_ "GenMsgCycleTimeFast" BO_ 1476 100;
BA_ "GenMsgCycleTime" BO_ 1475 100;
BA_ "GenMsgCycleTimeFast" BO_ 1475 100;
BA_ "GenMsgCycleTime" BO_ 797 100;
BA_ "GenMsgCycleTimeFast" BO_ 797 100;
BA_ "GenMsgCycleTime" BO_ 560 100;
BA_ "GenMsgCycleTimeFast" BO_ 560 100;
BA_ "GenMsgCycleTime" BO_ 1474 100;
BA_ "GenMsgCycleTimeFast" BO_ 1474 100;
BA_ "GenMsgCycleTime" BO_ 1473 100;
BA_ "GenMsgCycleTimeFast" BO_ 1473 100;
BA_ "GenMsgCycleTime" BO_ 1472 100;
BA_ "GenMsgCycleTimeFast" BO_ 1472 100;
BA_ "GenMsgCycleTime" BO_ 1471 100;
BA_ "GenMsgCycleTimeFast" BO_ 1471 100;
BA_ "GenMsgCycleTime" BO_ 1470 100;
BA_ "GenMsgCycleTimeFast" BO_ 1470 100;
BA_ "GenMsgCycleTime" BO_ 1469 100;
BA_ "GenMsgCycleTimeFast" BO_ 1469 100;
BA_ "GenMsgCycleTime" BO_ 1468 100;
BA_ "GenMsgCycleTimeFast" BO_ 1468 100;
BA_ "GenMsgCycleTime" BO_ 1467 100;
BA_ "GenMsgCycleTimeFast" BO_ 1467 100;
BA_ "GenMsgCycleTime" BO_ 1466 100;
BA_ "GenMsgCycleTimeFast" BO_ 1466 100;
BA_ "GenMsgCycleTime" BO_ 1465 100;
BA_ "GenMsgCycleTimeFast" BO_ 1465 100;
BA_ "GenMsgCycleTime" BO_ 796 100;
BA_ "GenMsgCycleTimeFast" BO_ 796 100;
BA_ "GenMsgCycleTime" BO_ 1464 100;
BA_ "GenMsgCycleTimeFast" BO_ 1464 100;
BA_ "GenMsgCycleTime" BO_ 1463 100;
BA_ "GenMsgCycleTimeFast" BO_ 1463 100;
BA_ "GenMsgCycleTime" BO_ 1462 100;
BA_ "GenMsgCycleTimeFast" BO_ 1462 100;
BA_ "GenMsgCycleTime" BO_ 1461 100;
BA_ "GenMsgCycleTimeFast" BO_ 1461 100;
BA_ "GenMsgCycleTime" BO_ 1460 100;
BA_ "GenMsgCycleTimeFast" BO_ 1460 100;
BA_ "GenMsgCycleTime" BO_ 1459 100;
BA_ "GenMsgCycleTimeFast" BO_ 1459 100;
BA_ "GenMsgCycleTime" BO_ 1458 100;
BA_ "GenMsgCycleTimeFast" BO_ 1458 100;
BA_ "GenMsgCycleTime" BO_ 1457 100;
BA_ "GenMsgCycleTimeFast" BO_ 1457 100;
BA_ "GenMsgCycleTime" BO_ 1456 100;
BA_ "GenMsgCycleTimeFast" BO_ 1456 100;
BA_ "GenMsgCycleTime" BO_ 1455 100;
BA_ "GenMsgCycleTimeFast" BO_ 1455 100;
BA_ "GenMsgCycleTime" BO_ 795 100;
BA_ "GenMsgCycleTimeFast" BO_ 795 100;
BA_ "GenMsgCycleTime" BO_ 1454 100;
BA_ "GenMsgCycleTimeFast" BO_ 1454 100;
BA_ "GenMsgCycleTime" BO_ 1453 100;
BA_ "GenMsgCycleTimeFast" BO_ 1453 100;
BA_ "GenMsgCycleTime" BO_ 1452 100;
BA_ "GenMsgCycleTimeFast" BO_ 1452 100;
BA_ "GenMsgCycleTime" BO_ 1451 100;
BA_ "GenMsgCycleTimeFast" BO_ 1451 100;
BA_ "GenMsgCycleTime" BO_ 1450 100;
BA_ "GenMsgCycleTimeFast" BO_ 1450 100;
BA_ "GenMsgCycleTime" BO_ 1449 100;
BA_ "GenMsgCycleTimeFast" BO_ 1449 100;
BA_ "GenMsgCycleTime" BO_ 1448 100;
BA_ "GenMsgCycleTimeFast" BO_ 1448 100;
BA_ "GenMsgCycleTime" BO_ 1447 100;
BA_ "GenMsgCycleTimeFast" BO_ 1447 100;
BA_ "GenMsgCycleTime" BO_ 1446 100;
BA_ "GenMsgCycleTimeFast" BO_ 1446 100;
BA_ "GenMsgCycleTime" BO_ 1445 100;
BA_ "GenMsgCycleTimeFast" BO_ 1445 100;
BA_ "GenMsgCycleTime" BO_ 794 100;
BA_ "GenMsgCycleTimeFast" BO_ 794 100;
BA_ "GenMsgCycleTime" BO_ 1444 100;
BA_ "GenMsgCycleTimeFast" BO_ 1444 100;
BA_ "GenMsgCycleTime" BO_ 1443 100;
BA_ "GenMsgCycleTimeFast" BO_ 1443 100;
BA_ "GenMsgCycleTime" BO_ 1442 100;
BA_ "GenMsgCycleTimeFast" BO_ 1442 100;
BA_ "GenMsgCycleTime" BO_ 1441 100;
BA_ "GenMsgCycleTimeFast" BO_ 1441 100;
BA_ "GenMsgCycleTime" BO_ 1440 100;
BA_ "GenMsgCycleTimeFast" BO_ 1440 100;
BA_ "GenMsgCycleTime" BO_ 1439 100;
BA_ "GenMsgCycleTimeFast" BO_ 1439 100;
BA_ "GenMsgCycleTime" BO_ 1438 100;
BA_ "GenMsgCycleTimeFast" BO_ 1438 100;
BA_ "GenMsgCycleTime" BO_ 1437 100;
BA_ "GenMsgCycleTimeFast" BO_ 1437 100;
BA_ "GenMsgCycleTime" BO_ 1436 100;
BA_ "GenMsgCycleTimeFast" BO_ 1436 100;
BA_ "GenMsgCycleTime" BO_ 1435 100;
BA_ "GenMsgCycleTimeFast" BO_ 1435 100;
BA_ "GenMsgCycleTime" BO_ 793 100;
BA_ "GenMsgCycleTimeFast" BO_ 793 100;
BA_ "GenMsgCycleTime" BO_ 1434 100;
BA_ "GenMsgCycleTimeFast" BO_ 1434 100;
BA_ "GenMsgCycleTime" BO_ 1433 100;
BA_ "GenMsgCycleTimeFast" BO_ 1433 100;
BA_ "GenMsgCycleTime" BO_ 1432 100;
BA_ "GenMsgCycleTimeFast" BO_ 1432 100;
BA_ "GenMsgCycleTime" BO_ 1431 100;
BA_ "GenMsgCycleTimeFast" BO_ 1431 100;
BA_ "GenMsgCycleTime" BO_ 1430 100;
BA_ "GenMsgCycleTimeFast" BO_ 1430 100;
BA_ "GenMsgCycleTime" BO_ 1429 100;
BA_ "GenMsgCycleTimeFast" BO_ 1429 100;
BA_ "GenMsgCycleTime" BO_ 1428 100;
BA_ "GenMsgCycleTimeFast" BO_ 1428 100;
BA_ "GenMsgCycleTime" BO_ 1427 100;
BA_ "GenMsgCycleTimeFast" BO_ 1427 100;
BA_ "GenMsgCycleTime" BO_ 1426 100;
BA_ "GenMsgCycleTimeFast" BO_ 1426 100;
BA_ "GenMsgCycleTime" BO_ 1425 100;
BA_ "GenMsgCycleTimeFast" BO_ 1425 100;
BA_ "GenMsgCycleTime" BO_ 792 100;
BA_ "GenMsgCycleTimeFast" BO_ 792 100;
BA_ "GenMsgCycleTime" BO_ 1424 100;
BA_ "GenMsgCycleTimeFast" BO_ 1424 100;
BA_ "GenMsgCycleTime" BO_ 1423 100;
BA_ "GenMsgCycleTimeFast" BO_ 1423 100;
BA_ "GenMsgCycleTime" BO_ 1422 100;
BA_ "GenMsgCycleTimeFast" BO_ 1422 100;
BA_ "GenMsgCycleTime" BO_ 1421 100;
BA_ "GenMsgCycleTimeFast" BO_ 1421 100;
BA_ "GenMsgCycleTime" BO_ 1420 100;
BA_ "GenMsgCycleTimeFast" BO_ 1420 100;
BA_ "GenMsgCycleTime" BO_ 1419 100;
BA_ "GenMsgCycleTimeFast" BO_ 1419 100;
BA_ "GenMsgCycleTime" BO_ 1418 100;
BA_ "GenMsgCycleTimeFast" BO_ 1418 100;
BA_ "GenMsgCycleTime" BO_ 1417 100;
BA_ "GenMsgCycleTimeFast" BO_ 1417 100;
BA_ "GenMsgCycleTime" BO_ 1416 100;
BA_ "GenMsgCycleTimeFast" BO_ 1416 100;
BA_ "GenMsgCycleTime" BO_ 1415 100;
BA_ "GenMsgCycleTimeFast" BO_ 1415 100;
BA_ "GenMsgCycleTime" BO_ 791 100;
BA_ "GenMsgCycleTimeFast" BO_ 791 100;
BA_ "GenMsgCycleTime" BO_ 1414 100;
BA_ "GenMsgCycleTimeFast" BO_ 1414 100;
BA_ "GenMsgCycleTime" BO_ 1413 100;
BA_ "GenMsgCycleTimeFast" BO_ 1413 100;
BA_ "GenMsgCycleTime" BO_ 1412 100;
BA_ "GenMsgCycleTimeFast" BO_ 1412 100;
BA_ "GenMsgCycleTime" BO_ 1411 100;
BA_ "GenMsgCycleTimeFast" BO_ 1411 100;
BA_ "GenMsgCycleTime" BO_ 1410 100;
BA_ "GenMsgCycleTimeFast" BO_ 1410 100;
BA_ "GenMsgCycleTime" BO_ 1409 100;
BA_ "GenMsgCycleTimeFast" BO_ 1409 100;
BA_ "GenMsgCycleTime" BO_ 1408 100;
BA_ "GenMsgCycleTimeFast" BO_ 1408 100;
BA_ "GenMsgCycleTime" BO_ 1407 100;
BA_ "GenMsgCycleTimeFast" BO_ 1407 100;
BA_ "GenMsgCycleTime" BO_ 1406 100;
BA_ "GenMsgCycleTimeFast" BO_ 1406 100;
BA_ "GenMsgCycleTime" BO_ 1405 100;
BA_ "GenMsgCycleTimeFast" BO_ 1405 100;
BA_ "GenMsgCycleTime" BO_ 790 100;
BA_ "GenMsgCycleTimeFast" BO_ 790 100;
BA_ "GenMsgCycleTime" BO_ 1404 100;
BA_ "GenMsgCycleTimeFast" BO_ 1404 100;
BA_ "GenMsgCycleTime" BO_ 1403 100;
BA_ "GenMsgCycleTimeFast" BO_ 1403 100;
BA_ "GenMsgCycleTime" BO_ 1402 100;
BA_ "GenMsgCycleTimeFast" BO_ 1402 100;
BA_ "GenMsgCycleTime" BO_ 1401 100;
BA_ "GenMsgCycleTimeFast" BO_ 1401 100;
BA_ "GenMsgCycleTime" BO_ 1400 100;
BA_ "GenMsgCycleTimeFast" BO_ 1400 100;
BA_ "GenMsgCycleTime" BO_ 1399 100;
BA_ "GenMsgCycleTimeFast" BO_ 1399 100;
BA_ "GenMsgCycleTime" BO_ 1398 100;
BA_ "GenMsgCycleTimeFast" BO_ 1398 100;
BA_ "GenMsgCycleTime" BO_ 1397 100;
BA_ "GenMsgCycleTimeFast" BO_ 1397 100;
BA_ "GenMsgCycleTime" BO_ 1396 100;
BA_ "GenMsgCycleTimeFast" BO_ 1396 100;
BA_ "GenMsgCycleTime" BO_ 1395 100;
BA_ "GenMsgCycleTimeFast" BO_ 1395 100;
BA_ "GenMsgCycleTime" BO_ 789 100;
BA_ "GenMsgCycleTimeFast" BO_ 789 100;
BA_ "GenMsgCycleTime" BO_ 1394 100;
BA_ "GenMsgCycleTimeFast" BO_ 1394 100;
BA_ "GenMsgCycleTime" BO_ 1393 100;
BA_ "GenMsgCycleTimeFast" BO_ 1393 100;
BA_ "GenMsgCycleTime" BO_ 1392 100;
BA_ "GenMsgCycleTimeFast" BO_ 1392 100;
BA_ "GenMsgCycleTime" BO_ 1391 100;
BA_ "GenMsgCycleTimeFast" BO_ 1391 100;
BA_ "GenMsgCycleTime" BO_ 1390 100;
BA_ "GenMsgCycleTimeFast" BO_ 1390 100;
BA_ "GenMsgCycleTime" BO_ 1389 100;
BA_ "GenMsgCycleTimeFast" BO_ 1389 100;
BA_ "GenMsgCycleTime" BO_ 1388 100;
BA_ "GenMsgCycleTimeFast" BO_ 1388 100;
BA_ "GenMsgCycleTime" BO_ 1387 100;
BA_ "GenMsgCycleTimeFast" BO_ 1387 100;
BA_ "GenMsgCycleTime" BO_ 1386 100;
BA_ "GenMsgCycleTimeFast" BO_ 1386 100;
BA_ "GenMsgCycleTime" BO_ 1385 100;
BA_ "GenMsgCycleTimeFast" BO_ 1385 100;
BA_ "GenMsgCycleTime" BO_ 788 100;
BA_ "GenMsgCycleTimeFast" BO_ 788 100;
BA_ "GenMsgCycleTime" BO_ 1384 100;
BA_ "GenMsgCycleTimeFast" BO_ 1384 100;
BA_ "GenMsgCycleTime" BO_ 1383 100;
BA_ "GenMsgCycleTimeFast" BO_ 1383 100;
BA_ "GenMsgCycleTime" BO_ 1382 100;
BA_ "GenMsgCycleTimeFast" BO_ 1382 100;
BA_ "GenMsgCycleTime" BO_ 1381 100;
BA_ "GenMsgCycleTimeFast" BO_ 1381 100;
BA_ "GenMsgCycleTime" BO_ 1380 100;
BA_ "GenMsgCycleTimeFast" BO_ 1380 100;
BA_ "GenMsgCycleTime" BO_ 1379 100;
BA_ "GenMsgCycleTimeFast" BO_ 1379 100;
BA_ "GenMsgCycleTime" BO_ 1378 100;
BA_ "GenMsgCycleTimeFast" BO_ 1378 100;
BA_ "GenMsgCycleTime" BO_ 1377 100;
BA_ "GenMsgCycleTimeFast" BO_ 1377 100;
BA_ "GenMsgCycleTime" BO_ 1376 100;
BA_ "GenMsgCycleTimeFast" BO_ 1376 100;
BA_ "GenMsgCycleTime" BO_ 1375 100;
BA_ "GenMsgCycleTimeFast" BO_ 1375 100;
BA_ "GenMsgCycleTime" BO_ 787 100;
BA_ "GenMsgCycleTimeFast" BO_ 787 100;
BA_ "GenMsgCycleTime" BO_ 144 100;
BA_ "GenMsgCycleTimeFast" BO_ 144 100;
BA_ "GenMsgCycleTime" BO_ 1374 100;
BA_ "GenMsgCycleTimeFast" BO_ 1374 100;
BA_ "GenMsgCycleTime" BO_ 1373 100;
BA_ "GenMsgCycleTimeFast" BO_ 1373 100;
BA_ "GenMsgCycleTime" BO_ 1372 100;
BA_ "GenMsgCycleTimeFast" BO_ 1372 100;
BA_ "GenMsgCycleTime" BO_ 1371 100;
BA_ "GenMsgCycleTimeFast" BO_ 1371 100;
BA_ "GenMsgCycleTime" BO_ 1370 100;
BA_ "GenMsgCycleTimeFast" BO_ 1370 100;
BA_ "GenMsgCycleTime" BO_ 1369 100;
BA_ "GenMsgCycleTimeFast" BO_ 1369 100;
BA_ "GenMsgCycleTime" BO_ 1368 100;
BA_ "GenMsgCycleTimeFast" BO_ 1368 100;
BA_ "GenMsgCycleTime" BO_ 1367 100;
BA_ "GenMsgCycleTimeFast" BO_ 1367 100;
BA_ "GenMsgCycleTime" BO_ 1366 100;
BA_ "GenMsgCycleTimeFast" BO_ 1366 100;
BA_ "GenMsgCycleTime" BO_ 1365 100;
BA_ "GenMsgCycleTimeFast" BO_ 1365 100;
BA_ "GenMsgCycleTime" BO_ 786 100;
BA_ "GenMsgCycleTimeFast" BO_ 786 100;
BA_ "GenMsgCycleTime" BO_ 1364 100;
BA_ "GenMsgCycleTimeFast" BO_ 1364 100;
BA_ "GenMsgCycleTime" BO_ 1363 100;
BA_ "GenMsgCycleTimeFast" BO_ 1363 100;
BA_ "GenMsgCycleTime" BO_ 1362 100;
BA_ "GenMsgCycleTimeFast" BO_ 1362 100;
BA_ "GenMsgCycleTime" BO_ 1361 100;
BA_ "GenMsgCycleTimeFast" BO_ 1361 100;
BA_ "GenMsgCycleTime" BO_ 1360 100;
BA_ "GenMsgCycleTimeFast" BO_ 1360 100;
BA_ "GenMsgCycleTime" BO_ 1359 100;
BA_ "GenMsgCycleTimeFast" BO_ 1359 100;
BA_ "GenMsgCycleTime" BO_ 1358 100;
BA_ "GenMsgCycleTimeFast" BO_ 1358 100;
BA_ "GenMsgCycleTime" BO_ 1357 100;
BA_ "GenMsgCycleTimeFast" BO_ 1357 100;
BA_ "GenMsgCycleTime" BO_ 1356 100;
BA_ "GenMsgCycleTimeFast" BO_ 1356 100;
BA_ "GenMsgCycleTime" BO_ 1355 100;
BA_ "GenMsgCycleTimeFast" BO_ 1355 100;
BA_ "GenMsgCycleTime" BO_ 1354 100;
BA_ "GenMsgCycleTimeFast" BO_ 1354 100;
BA_ "GenMsgCycleTime" BO_ 1353 100;
BA_ "GenMsgCycleTimeFast" BO_ 1353 100;
BA_ "GenMsgCycleTime" BO_ 1352 100;
BA_ "GenMsgCycleTimeFast" BO_ 1352 100;
BA_ "GenMsgCycleTime" BO_ 1351 100;
BA_ "GenMsgCycleTimeFast" BO_ 1351 100;
BA_ "GenMsgCycleTime" BO_ 1350 100;
BA_ "GenMsgCycleTimeFast" BO_ 1350 100;
BA_ "GenMsgCycleTime" BO_ 1349 100;
BA_ "GenMsgCycleTimeFast" BO_ 1349 100;
BA_ "GenMsgCycleTime" BO_ 1348 100;
BA_ "GenMsgCycleTimeFast" BO_ 1348 100;
BA_ "GenMsgCycleTime" BO_ 1347 100;
BA_ "GenMsgCycleTimeFast" BO_ 1347 100;
BA_ "GenMsgCycleTime" BO_ 1346 100;
BA_ "GenMsgCycleTimeFast" BO_ 1346 100;
BA_ "GenMsgCycleTime" BO_ 1345 100;
BA_ "GenMsgCycleTimeFast" BO_ 1345 100;
BA_ "GenMsgCycleTime" BO_ 1344 100;
BA_ "GenMsgCycleTimeFast" BO_ 1344 100;
BA_ "GenMsgCycleTime" BO_ 1343 100;
BA_ "GenMsgCycleTimeFast" BO_ 1343 100;
BA_ "GenMsgCycleTime" BO_ 1342 100;
BA_ "GenMsgCycleTimeFast" BO_ 1342 100;
BA_ "GenMsgCycleTime" BO_ 1341 100;
BA_ "GenMsgCycleTimeFast" BO_ 1341 100;
BA_ "GenMsgCycleTime" BO_ 1340 100;
BA_ "GenMsgCycleTimeFast" BO_ 1340 100;
BA_ "GenMsgCycleTime" BO_ 1339 100;
BA_ "GenMsgCycleTimeFast" BO_ 1339 100;
BA_ "GenMsgCycleTime" BO_ 1338 100;
BA_ "GenMsgCycleTimeFast" BO_ 1338 100;
BA_ "GenMsgCycleTime" BO_ 1337 100;
BA_ "GenMsgCycleTimeFast" BO_ 1337 100;
BA_ "GenMsgCycleTime" BO_ 1336 100;
BA_ "GenMsgCycleTimeFast" BO_ 1336 100;
BA_ "GenMsgCycleTime" BO_ 1335 100;
BA_ "GenMsgCycleTimeFast" BO_ 1335 100;
BA_ "GenMsgCycleTime" BO_ 781 100;
BA_ "GenMsgCycleTimeFast" BO_ 781 100;
BA_ "GenMsgCycleTime" BO_ 1334 100;
BA_ "GenMsgCycleTimeFast" BO_ 1334 100;
BA_ "GenMsgCycleTime" BO_ 1333 100;
BA_ "GenMsgCycleTimeFast" BO_ 1333 100;
BA_ "GenMsgCycleTime" BO_ 1332 100;
BA_ "GenMsgCycleTimeFast" BO_ 1332 100;
BA_ "GenMsgCycleTime" BO_ 1331 100;
BA_ "GenMsgCycleTimeFast" BO_ 1331 100;
BA_ "GenMsgCycleTime" BO_ 1330 100;
BA_ "GenMsgCycleTimeFast" BO_ 1330 100;
BA_ "GenMsgCycleTime" BO_ 1329 100;
BA_ "GenMsgCycleTimeFast" BO_ 1329 100;
BA_ "GenMsgCycleTime" BO_ 1328 100;
BA_ "GenMsgCycleTimeFast" BO_ 1328 100;
BA_ "GenMsgCycleTime" BO_ 1327 100;
BA_ "GenMsgCycleTimeFast" BO_ 1327 100;
BA_ "GenMsgCycleTime" BO_ 1326 100;
BA_ "GenMsgCycleTimeFast" BO_ 1326 100;
BA_ "GenMsgCycleTime" BO_ 1325 100;
BA_ "GenMsgCycleTimeFast" BO_ 1325 100;
BA_ "GenMsgCycleTime" BO_ 780 100;
BA_ "GenMsgCycleTimeFast" BO_ 780 100;
BA_ "GenMsgCycleTime" BO_ 1324 100;
BA_ "GenMsgCycleTimeFast" BO_ 1324 100;
BA_ "GenMsgCycleTime" BO_ 1323 100;
BA_ "GenMsgCycleTimeFast" BO_ 1323 100;
BA_ "GenMsgCycleTime" BO_ 1322 100;
BA_ "GenMsgCycleTimeFast" BO_ 1322 100;
BA_ "GenMsgCycleTime" BO_ 1321 100;
BA_ "GenMsgCycleTimeFast" BO_ 1321 100;
BA_ "GenMsgCycleTime" BO_ 1320 100;
BA_ "GenMsgCycleTimeFast" BO_ 1320 100;
BA_ "GenMsgCycleTime" BO_ 1319 100;
BA_ "GenMsgCycleTimeFast" BO_ 1319 100;
BA_ "GenMsgCycleTime" BO_ 1318 100;
BA_ "GenMsgCycleTimeFast" BO_ 1318 100;
BA_ "GenMsgCycleTime" BO_ 1317 100;
BA_ "GenMsgCycleTimeFast" BO_ 1317 100;
BA_ "GenMsgCycleTime" BO_ 1316 100;
BA_ "GenMsgCycleTimeFast" BO_ 1316 100;
BA_ "GenMsgCycleTime" BO_ 1315 100;
BA_ "GenMsgCycleTimeFast" BO_ 1315 100;
BA_ "GenMsgCycleTime" BO_ 779 100;
BA_ "GenMsgCycleTimeFast" BO_ 779 100;
BA_ "GenMsgCycleTime" BO_ 1314 100;
BA_ "GenMsgCycleTimeFast" BO_ 1314 100;
BA_ "GenMsgCycleTime" BO_ 1313 100;
BA_ "GenMsgCycleTimeFast" BO_ 1313 100;
BA_ "GenMsgCycleTime" BO_ 1312 100;
BA_ "GenMsgCycleTimeFast" BO_ 1312 100;
BA_ "GenMsgCycleTime" BO_ 1311 100;
BA_ "GenMsgCycleTimeFast" BO_ 1311 100;
BA_ "GenMsgCycleTime" BO_ 1310 100;
BA_ "GenMsgCycleTimeFast" BO_ 1310 100;
BA_ "GenMsgCycleTime" BO_ 1309 100;
BA_ "GenMsgCycleTimeFast" BO_ 1309 100;
BA_ "GenMsgCycleTime" BO_ 1308 100;
BA_ "GenMsgCycleTimeFast" BO_ 1308 100;
BA_ "GenMsgCycleTime" BO_ 1307 100;
BA_ "GenMsgCycleTimeFast" BO_ 1307 100;
BA_ "GenMsgCycleTime" BO_ 1306 100;
BA_ "GenMsgCycleTimeFast" BO_ 1306 100;
BA_ "GenMsgCycleTime" BO_ 1305 100;
BA_ "GenMsgCycleTimeFast" BO_ 1305 100;
BA_ "GenMsgCycleTime" BO_ 1304 100;
BA_ "GenMsgCycleTimeFast" BO_ 1304 100;
BA_ "GenMsgCycleTime" BO_ 1303 100;
BA_ "GenMsgCycleTimeFast" BO_ 1303 100;
BA_ "GenMsgCycleTime" BO_ 1302 100;
BA_ "GenMsgCycleTimeFast" BO_ 1302 100;
BA_ "GenMsgCycleTime" BO_ 1301 100;
BA_ "GenMsgCycleTimeFast" BO_ 1301 100;
BA_ "GenMsgCycleTime" BO_ 1300 100;
BA_ "GenMsgCycleTimeFast" BO_ 1300 100;
BA_ "GenMsgCycleTime" BO_ 1299 100;
BA_ "GenMsgCycleTimeFast" BO_ 1299 100;
BA_ "GenMsgCycleTime" BO_ 1298 100;
BA_ "GenMsgCycleTimeFast" BO_ 1298 100;
BA_ "GenMsgCycleTime" BO_ 1297 100;
BA_ "GenMsgCycleTimeFast" BO_ 1297 100;
BA_ "GenMsgCycleTime" BO_ 1296 100;
BA_ "GenMsgCycleTimeFast" BO_ 1296 100;
BA_ "GenMsgCycleTime" BO_ 1295 100;
BA_ "GenMsgCycleTimeFast" BO_ 1295 100;
BA_ "GenMsgCycleTime" BO_ 1294 100;
BA_ "GenMsgCycleTimeFast" BO_ 1294 100;
BA_ "GenMsgCycleTime" BO_ 1293 100;
BA_ "GenMsgCycleTimeFast" BO_ 1293 100;
BA_ "GenMsgCycleTime" BO_ 1292 100;
BA_ "GenMsgCycleTimeFast" BO_ 1292 100;
BA_ "GenMsgCycleTime" BO_ 1291 100;
BA_ "GenMsgCycleTimeFast" BO_ 1291 100;
BA_ "GenMsgCycleTime" BO_ 1290 100;
BA_ "GenMsgCycleTimeFast" BO_ 1290 100;
BA_ "GenMsgCycleTime" BO_ 1289 100;
BA_ "GenMsgCycleTimeFast" BO_ 1289 100;
BA_ "GenMsgCycleTime" BO_ 1288 100;
BA_ "GenMsgCycleTimeFast" BO_ 1288 100;
BA_ "GenMsgCycleTime" BO_ 1287 100;
BA_ "GenMsgCycleTimeFast" BO_ 1287 100;
BA_ "GenMsgCycleTime" BO_ 1286 100;
BA_ "GenMsgCycleTimeFast" BO_ 1286 100;
BA_ "GenMsgCycleTime" BO_ 1285 100;
BA_ "GenMsgCycleTimeFast" BO_ 1285 100;
BA_ "GenMsgCycleTime" BO_ 1284 100;
BA_ "GenMsgCycleTimeFast" BO_ 1284 100;
BA_ "GenMsgCycleTime" BO_ 1283 100;
BA_ "GenMsgCycleTimeFast" BO_ 1283 100;
BA_ "GenMsgCycleTime" BO_ 1282 100;
BA_ "GenMsgCycleTimeFast" BO_ 1282 100;
BA_ "GenMsgCycleTime" BO_ 1281 100;
BA_ "GenMsgCycleTimeFast" BO_ 1281 100;
BA_ "GenMsgCycleTime" BO_ 1280 100;
BA_ "GenMsgCycleTimeFast" BO_ 1280 100;
BA_ "GenMsgCycleTime" BO_ 1909 100;
BA_ "GenMsgCycleTimeFast" BO_ 1909 100;
BA_ "GenMsgCycleTime" BO_ 1906 100;
BA_ "GenMsgCycleTimeFast" BO_ 1906 100;
BA_ "GenMsgCycleTime" BO_ 146 100;
BA_ "GenMsgCycleTimeFast" BO_ 146 100;
BA_ "GenMsgCycleTime" BO_ 520 100;
BA_ "GenMsgCycleTimeFast" BO_ 520 100;
BA_ "GenMsgCycleTime" BO_ 128 100;
BA_ "GenMsgCycleTimeFast" BO_ 128 100;
BA_ "GenMsgCycleTime" BO_ 1120 100;
BA_ "GenMsgCycleTimeFast" BO_ 1120 100;
BA_ "GenMsgCycleTime" BO_ 35 200;
BA_ "GenMsgCycleTimeFast" BO_ 35 100;
BA_ "GenMsgCycleTime" BO_ 1664 100;
BA_ "GenMsgCycleTimeFast" BO_ 1664 100;
BA_ "GenMsgCycleTime" BO_ 1855 100;
BA_ "GenMsgCycleTimeFast" BO_ 1855 100;
BA_ "GenMsgCycleTime" BO_ 1872 5000;
BA_ "GenMsgCycleTimeFast" BO_ 1872 100;
BA_ "GenMsgCycleTime" BO_ 1874 10000;
BA_ "GenMsgCycleTimeFast" BO_ 1874 100;
BA_ "GenMsgCycleTime" BO_ 1027 1000;
BA_ "GenMsgCycleTimeFast" BO_ 1027 100;
BA_ "GenMsgCycleTime" BO_ 1025 500;
BA_ "GenMsgCycleTimeFast" BO_ 1025 100;
BA_ "GenMsgCycleTime" BO_ 1030 5000;
BA_ "GenMsgCycleTimeFast" BO_ 1030 100;
BA_ "GenMsgCycleTime" BO_ 1029 5000;
BA_ "GenMsgCycleTimeFast" BO_ 1029 100;
BA_ "GenMsgCycleTime" BO_ 1920 100;
BA_ "GenMsgCycleTimeFast" BO_ 1920 100;
BA_ "GenMsgCycleTime" BO_ 1028 1000;
BA_ "GenMsgCycleTimeFast" BO_ 1028 100;
BA_ "GenMsgCycleTime" BO_ 1024 200;
BA_ "GenMsgCycleTimeFast" BO_ 1024 100;
BA_ "GenMsgCycleTime" BO_ 1897 200;
BA_ "GenMsgCycleTimeFast" BO_ 1897 100;
BA_ "GenMsgCycleTime" BO_ 1904 5000;
BA_ "GenMsgCycleTimeFast" BO_ 1904 100;
BA_ "GenMsgCycleTime" BO_ 1026 500;
BA_ "GenMsgCycleTimeFast" BO_ 1026 100;
BA_ "GenMsgCycleTime" BO_ 785 200;
BA_ "GenMsgCycleTimeFast" BO_ 785 100;
BA_ "GenMsgCycleTime" BO_ 514 10;
BA_ "GenMsgCycleTimeFast" BO_ 514 100;
BA_ "GenMsgSendType" BO_ 595 7;
BA_ "GenMsgCycleTime" BO_ 595 100;
BA_ "GenMsgCycleTimeFast" BO_ 595 100;
BA_ "GenMsgSendType" BO_ 594 7;
BA_ "GenMsgCycleTime" BO_ 594 100;
BA_ "GenMsgCycleTimeFast" BO_ 594 100;
BA_ "GenMsgCycleTime" BO_ 784 200;
BA_ "GenMsgCycleTimeFast" BO_ 784 100;
BA_ "GenMsgCycleTime" BO_ 849 100;
BA_ "GenMsgCycleTimeFast" BO_ 849 100;
BA_ "GenMsgCycleTime" BO_ 613 100;
BA_ "GenMsgCycleTimeFast" BO_ 613 100;
BA_ "GenMsgCycleTime" BO_ 612 500;
BA_ "GenMsgCycleTimeFast" BO_ 612 100;
BA_ "GenMsgCycleTime" BO_ 611 500;
BA_ "GenMsgCycleTimeFast" BO_ 611 100;
BA_ "GenMsgCycleTime" BO_ 593 100;
BA_ "GenMsgCycleTimeFast" BO_ 593 100;
BA_ "GenMsgCycleTime" BO_ 1883 200;
BA_ "GenMsgCycleTimeFast" BO_ 1883 100;
BA_ "GenMsgCycleTime" BO_ 850 200;
BA_ "GenMsgCycleTimeFast" BO_ 850 100;
BA_ "GenMsgCycleTime" BO_ 277 100;
BA_ "GenMsgCycleTimeFast" BO_ 277 100;
BA_ "GenMsgCycleTime" BO_ 1173 100;
BA_ "GenMsgCycleTimeFast" BO_ 1173 100;
BA_ "GenMsgCycleTime" BO_ 1685 100;
BA_ "GenMsgCycleTimeFast" BO_ 1685 100;
BA_ "GenMsgCycleTime" BO_ 392 10;
BA_ "GenMsgCycleTimeFast" BO_ 392 100;
BA_ "GenMsgCycleTime" BO_ 391 10;
BA_ "GenMsgCycleTimeFast" BO_ 391 100;
BA_ "GenMsgCycleTime" BO_ 390 10;
BA_ "GenMsgCycleTimeFast" BO_ 390 100;
BA_ "GenMsgCycleTime" BO_ 2000 100;
BA_ "GenMsgCycleTimeFast" BO_ 2000 100;
BA_ "GenMsgCycleTime" BO_ 1921 100;
BA_ "GenMsgCycleTimeFast" BO_ 1921 100;
BA_ "GenMsgCycleTime" BO_ 1665 100;
BA_ "GenMsgCycleTimeFast" BO_ 1665 100;
BA_ "GenMsgCycleTime" BO_ 1847 100;
BA_ "GenMsgCycleTimeFast" BO_ 1847 100;
BA_ "GenMsgCycleTime" BO_ 1873 100;
BA_ "GenMsgCycleTimeFast" BO_ 1873 100;
BA_ "GenMsgCycleTime" BO_ 1905 100;
BA_ "GenMsgCycleTimeFast" BO_ 1905 100;
BA_ "GenMsgCycleTime" BO_ 1875 100;
BA_ "GenMsgCycleTimeFast" BO_ 1875 100;
BA_ "GenMsgCycleTime" BO_ 1717 100;
BA_ "GenMsgCycleTimeFast" BO_ 1717 100;
BA_ "GenMsgCycleTime" BO_ 1910 100;
BA_ "GenMsgCycleTimeFast" BO_ 1910 100;
BA_ "GenMsgCycleTime" BO_ 1861 100;
BA_ "GenMsgCycleTimeFast" BO_ 1861 100;
BA_ "GenMsgCycleTime" BO_ 852 200;
BA_ "GenMsgCycleTimeFast" BO_ 852 100;
BA_ "GenMsgCycleTime" BO_ 851 200;
BA_ "GenMsgCycleTimeFast" BO_ 851 100;
BA_ "GenMsgCycleTime" BO_ 848 1000;
BA_ "GenMsgCycleTimeFast" BO_ 848 100;
BA_ "GenMsgCycleTime" BO_ 853 200;
BA_ "GenMsgCycleTimeFast" BO_ 853 100;
BA_ "GenMsgCycleTime" BO_ 1032 500;
BA_ "GenMsgCycleTimeFast" BO_ 1032 100;
BA_ "GenMsgCycleTime" BO_ 69 200;
BA_ "GenMsgCycleTimeFast" BO_ 69 100;
BA_ "GenMsgCycleTime" BO_ 1033 500;
BA_ "GenMsgCycleTimeFast" BO_ 1033 100;
BA_ "GenMsgCycleTime" BO_ 1918 100;
BA_ "GenMsgCycleTimeFast" BO_ 1918 100;
BA_ "GenMsgCycleTime" BO_ 1035 100;
BA_ "GenMsgCycleTimeFast" BO_ 1035 100;
BA_ "GenMsgCycleTime" BO_ 774 1000;
BA_ "GenMsgCycleTimeFast" BO_ 774 100;
BA_ "GenMsgCycleTime" BO_ 773 200;
BA_ "GenMsgCycleTimeFast" BO_ 773 100;
BA_ "GenMsgCycleTime" BO_ 772 200;
BA_ "GenMsgCycleTimeFast" BO_ 772 100;
BA_ "GenMsgCycleTime" BO_ 771 200;
BA_ "GenMsgCycleTimeFast" BO_ 771 100;
BA_ "GenMsgCycleTime" BO_ 770 200;
BA_ "GenMsgCycleTimeFast" BO_ 770 100;
BA_ "GenMsgCycleTime" BO_ 769 200;
BA_ "GenMsgCycleTimeFast" BO_ 769 100;
BA_ "GenMsgCycleTime" BO_ 778 30000;
BA_ "GenMsgCycleTimeFast" BO_ 778 100;
BA_ "GenMsgCycleTime" BO_ 777 30000;
BA_ "GenMsgCycleTimeFast" BO_ 777 100;
BA_ "GenMsgCycleTime" BO_ 776 30000;
BA_ "GenMsgCycleTimeFast" BO_ 776 100;
BA_ "GenMsgCycleTime" BO_ 775 30000;
BA_ "GenMsgCycleTimeFast" BO_ 775 100;
BA_ "GenMsgCycleTime" BO_ 768 1000;
BA_ "GenMsgCycleTimeFast" BO_ 768 100;
BA_ "GenMsgCycleTime" BO_ 783 30000;
BA_ "GenMsgCycleTimeFast" BO_ 783 100;
BA_ "GenMsgCycleTime" BO_ 782 30000;
BA_ "GenMsgCycleTimeFast" BO_ 782 100;
BA_ "GenMsgCycleTime" BO_ 1827 100;
BA_ "GenMsgCycleTimeFast" BO_ 1827 100;
BA_ "GenMsgCycleTime" BO_ 1869 200;
BA_ "GenMsgCycleTimeFast" BO_ 1869 100;
BA_ "GenMsgCycleTime" BO_ 1200 14;
BA_ "GenMsgCycleTimeFast" BO_ 1200 100;
BA_ "GenMsgCycleTime" BO_ 528 14;
BA_ "GenMsgCycleTimeFast" BO_ 528 100;
BA_DEF_DEF_ "GenMsgCycleTimeFast" 0;
BA_DEF_DEF_ "GenMsgCycleTime" 0;
BA_DEF_DEF_ "GenMsgSendType" "Cyclic";
BA_DEF_DEF_ "GenSigStartValue" 0;
BA_DEF_DEF_ "GenSigCycleTimeActive" 0;
BA_DEF_DEF_ "GenSigCycleTime" 0;
BA_DEF_DEF_ "GenSigSendType" "Cyclic";
BA_DEF_DEF_ "Baudrate" 125000;
BA_DEF_DEF_ "GenMsgBackgroundColor" "#ffffff";
BA_DEF_DEF_ "GenMsgForegroundColor" "#000000";
BA_DEF_DEF_ "labelfilters" 1;
BA_DEF_DEF_ "filterlabeling" 1;
CM_ BU_ ZD "Zebra Battery Display.";
CM_ BU_ TPMS "Tire Pressure Monitoring System";
CM_ BU_ RESERVED_FRAMES "Virtual or hypothetical sender of the reserved frames. It is included as a node to be able to export the frames into the XML";
CM_ BU_ RCM "Restrains Control Module (Airbag and belt pretense control)";
CM_ BU_ RAC "Remote Acquisition Unit(Telematics)";
CM_ BU_ PCU "Power Conversion Unit and Motor Control";
CM_ BU_ PAS "Electro Hydraulic Power Assisted Steering";
CM_ BU_ ESP "Eslectronic Stability Process";
CM_ BU_ DiagnosticTester "Diagnostic tool. Included to reserve IDs ";
CM_ BU_ CHG "Eltek Charger";
CM_ BU_ CDCM "Climate Control Module";
CM_ BU_ BMS "Battery Management System";
CM_ BU_ ABS "Braking Control Module";
CM_ BU_ EDL "Enerdel Battery Module";
CM_ BO_ 929 "Period of transmission if node active: 500ms";
CM_ BO_ 928 "Period of transmission if node active: 500ms";
CM_ BO_ 592 "Period of transmission if node active: 100 ms";
CM_ BO_ 836 "Period of transmission if node active: 200ms";
CM_ SG_ 836 SensorPressure_LF "0xFF represents Signal Not Available";
CM_ SG_ 836 SensorPressure_RF "0xFF represents Signal Not Available";
CM_ SG_ 836 SensorPressure_RR "0xFF represents Signal Not Available";
CM_ SG_ 836 SensorPressure_LR "0xFF represents Signal Not Available";
CM_ BO_ 837 "Period of transmission if node active: 200ms";
CM_ BO_ 838 "Reserved for TPMS debug purposes";
CM_ BO_ 645 "RCM will react to this frame. DO NOT TRANSMIT AT ANY MOMENT";
CM_ BO_ 831 "Reserved for Fuel Cell project. Do not use";
CM_ BO_ 830 "Reserved for Fuel Cell project. Do not use";
CM_ BO_ 829 "Reserved for Fuel Cell project. Do not use";
CM_ BO_ 828 "Reserved for Fuel Cell project. Do not use";
CM_ BO_ 827 "Reserved for Fuel Cell project. Do not use";
CM_ BO_ 826 "Reserved for Fuel Cell project. Do not use";
CM_ BO_ 825 "Reserved for Fuel Cell project. Do not use";
CM_ BO_ 824 "Reserved for Fuel Cell project. Do not use";
CM_ BO_ 823 "Reserved for Fuel Cell project. Do not use";
CM_ BO_ 822 "Reserved for Fuel Cell project. Do not use";
CM_ BO_ 821 "Reserved for Fuel Cell project. Do not use";
CM_ BO_ 820 "Reserved for Fuel Cell project. Do not use";
CM_ BO_ 819 "Reserved for Fuel Cell project. Do not use";
CM_ BO_ 818 "Reserved for Fuel Cell project. Do not use";
CM_ BO_ 817 "Reserved for Fuel Cell project. Do not use";
CM_ BO_ 816 "Reserved for Fuel Cell project. Do not use";
CM_ BO_ 815 "Reserved for Fuel Cell project. Do not use";
CM_ BO_ 814 "Reserved for Fuel Cell project. Do not use";
CM_ BO_ 813 "Reserved for Fuel Cell project. Do not use";
CM_ BO_ 812 "Reserved for Fuel Cell project. Do not use";
CM_ BO_ 811 "Reserved for Fuel Cell project. Do not use";
CM_ BO_ 810 "Reserved for Fuel Cell project. Do not use";
CM_ BO_ 809 "Reserved for Fuel Cell project. Do not use";
CM_ BO_ 808 "Reserved for Fuel Cell project. Do not use";
CM_ BO_ 807 "Reserved for Fuel Cell project. Do not use";
CM_ BO_ 857 "Reserved for PCU";
CM_ BO_ 806 "Reserved for Fuel Cell project. Do not use";
CM_ BO_ 805 "Reserved for Fuel Cell project. Do not use";
CM_ BO_ 804 "Reserved for Fuel Cell project. Do not use";
CM_ BO_ 803 "Reserved for Fuel Cell project. Do not use";
CM_ BO_ 802 "Reserved for Fuel Cell project. Do not use";
CM_ BO_ 801 "Reserved for Fuel Cell project. Do not use";
CM_ BO_ 800 "Reserved for Fuel Cell project. Do not use";
CM_ BO_ 799 "Reserved for PCU comunication with Zebra BMI. Do not use if possible";
CM_ BO_ 798 "Reserved for PCU comunication with Zebra BMI. Do not use if possible";
CM_ BO_ 797 "Reserved for PCU comunication with Zebra BMI. Do not use if possible";
CM_ BO_ 560 "A different version of ABS might use this frame. Do not use if possible.";
CM_ BO_ 796 "Reserved for PCU comunication with Zebra BMI. Do not use if possible";
CM_ BO_ 795 "Reserved for PCU comunication with Zebra BMI. Do not use if possible";
CM_ BO_ 794 "Reserved for PCU comunication with Zebra BMI. Do not use if possible";
CM_ BO_ 793 "Reserved for PCU comunication with Zebra BMI. Do not use if possible";
CM_ BO_ 792 "Reserved for PCU comunication with Zebra BMI. Do not use if possible";
CM_ BO_ 791 "Reserved for PCU comunication with Zebra BMI. Do not use if possible";
CM_ BO_ 790 "Reserved for PCU comunication with Zebra BMI. Do not use if possible";
CM_ BO_ 789 "Reserved for PCU comunication with Zebra BMI. Do not use if possible";
CM_ BO_ 788 "Reserved for PCU comunication with Zebra BMI. Do not use if possible";
CM_ BO_ 787 "Reserved for PCU comunication with Zebra BMI. Do not use if possible";
CM_ BO_ 144 "A different version of ABS might use this frame. Do not use if possible.";
CM_ BO_ 786 "Reserved for PCU comunication with Zebra BMI. Do not use if possible";
CM_ BO_ 781 "Reserved for Zebra BMI. Do not use";
CM_ BO_ 780 "Reserved for Zebra BMI. Do not use";
CM_ BO_ 779 "Reserved for Zebra BMI. Do not use";
CM_ BO_ 146 "PAS may react to this frame. DO NOT TRANSMIT AT ANY MOMENT";
CM_ BO_ 520 "PAS may react to this frame. DO NOT TRANSMIT AT ANY MOMENT";
CM_ BO_ 128 "A different version of ABS might use this frame. Do not use if possible.";
CM_ BO_ 35 "Period of transmission if node active: 200ms";
CM_ SG_ 785 AvailableMainsCurrent "Maximum available mains AC current";
CM_ BO_ 514 "Period of transmission if node active: 10ms";
CM_ BO_ 595 "Only under request in certain conditions";
CM_ BO_ 594 "Only under request in certain conditions";
CM_ BO_ 849 "Event driven frame. Answer to frame 0x350";
CM_ SG_ 849 ChargerRequest "Same value as LogInRequest received";
CM_ SG_ 849 ChargerAssignedID "Value between 0x01 and 0xFE. 0x00 must be considered not valid.";
CM_ BO_ 613 "Period of transmission if node active: 100ms";
CM_ SG_ 613 SpeedIndication "For driver information display";
CM_ SG_ 613 CustomerDODIndication "for driver information display only";
CM_ SG_ 613 EconometerIndication "For driver information display only";
CM_ BO_ 612 "Period of transmission if node active: 200ms";
CM_ SG_ 612 PASEnable "PCU indicates the PAS system if it is allowed to work and use power or not.";
CM_ SG_ 612 ESPIndication "For driver information display only.";
CM_ SG_ 612 PowerLimitIndication "For driver information display only.";
CM_ SG_ 612 EconomyIndication "For driver information display only.";
CM_ SG_ 612 ABSWarningIndication "For driver information display only.";
CM_ SG_ 612 ElectricHzIndication "For driver information display only.";
CM_ SG_ 612 BrakeWarningIndication "For driver information display only.";
CM_ SG_ 612 OvertempIndication "For driver information display only.";
CM_ SG_ 612 NeutralIndication "For driver information display only.";
CM_ SG_ 612 MILIndication "For driver information display only.";
CM_ SG_ 612 ChargingIndication "For driver information display only.";
CM_ SG_ 612 AuxiliaryBatteryLowIndication "For driver information display only.";
CM_ SG_ 612 DriveEnableIndication "For driver information display only.";
CM_ SG_ 612 OnPlugIndication "For driver information display only.";
CM_ SG_ 612 ParkIndication "For driver information display only.";
CM_ SG_ 612 ReverseIndication "For driver information display only.";
CM_ SG_ 612 LowSOCIndication "For driver information display only.";
CM_ SG_ 612 PilotSignalPresent "PilotSignalPresent indicates wheter the pilot signal from the PCS is present and accepted. It is indirectly indicated that the car is connected to the mains.";
CM_ SG_ 612 DriveIndication "For driver information display only.";
CM_ SG_ 611 SLI_Voltage "Starting-Lighting-Ignition battery voltage";
CM_ SG_ 611 SLI_AmbientTemperature "Starting-Lighting-Ignition battery temperature";
CM_ SG_ 611 VehicleSpeedCounter "SpeedCounter will increase if value of signal VehicleSpeed is correct. Will go from 0xFF to 0x00. Counter will not increase if value is wrong.";
CM_ SG_ 611 VehicleSpeed "Vehicle speed in kilometers per hour";
CM_ BO_ 593 "Period of transmission if node active: 100 ms ";
CM_ BO_ 850 "Period of transmission if node active: 200ms";
CM_ SG_ 850 ChargerOutputPowerDemand "Percemtage of full charge output power. Allows real time PCU control of charger relative output power.";
CM_ SG_ 850 ReceiverID_1 "IDof the receiver. 0xFF is broadcast";
CM_ SG_ 277 PAS_SoftwareVersion "Value downloaded with the calibration file";
CM_ SG_ 277 PAS_VersionMonth "Valid values 1 to 12";
CM_ SG_ 277 PAS_VersionDay "Valid value 1 to 31";
CM_ SG_ 277 PAS_VersionYear "Valid values 00 (2000) to 99 (2099)";
CM_ SG_ 277 PAS_CalibrationIssue "Value downloaded with the calibration file";
CM_ BO_ 392 "Period of transmission if node active: 10ms";
CM_ BO_ 391 "Period of transmission if node active: 10ms";
CM_ BO_ 390 "Period of transmission if node active: 10ms";
CM_ BO_ 852 "Period of transmission if node active: 200ms";
CM_ SG_ 852 RectifierID_2 "ID of sender";
CM_ SG_ 852 ChargerAvailablePowerPercentage "Percentage of Nominal Power the charger is available to deliver.";
CM_ SG_ 852 ChargerNominalPower "Nominal Power Output from the Charger. PWM command to charger will control a percentage of this value.";
CM_ BO_ 851 "Period of transmission if node active: 200ms";
CM_ SG_ 851 RectifierID_1 "ID of sender";
CM_ SG_ 851 ChargerDCCurrent "Use only positive values";
CM_ SG_ 851 ChargerStatus "Rest of values should be considered as reserved, and not acted upon.";
CM_ BO_ 848 "Period of transmission if node active and not logged in: 1000ms";
CM_ BO_ 853 "Period of transmission if node active: 200ms";
CM_ SG_ 853 CommunicationFailure "Communication error between primary and secondary.";
CM_ SG_ 853 CurrentLimitError "Warning: current limited due to some error";
CM_ SG_ 853 ControllerCommunicationError "CAN communication with the PCU missing";
CM_ SG_ 853 ModuleFailureError "Boost running, but DCDC failure";
CM_ SG_ 853 RectifierID_3 "ID of sender";
CM_ BO_ 69 "Period of transmission if node active: 200ms";
CM_ BO_ 51 "CCP frame for VCU";
CM_ BO_ 50 "CCP frame for VCU";
CM_ BO_ 55 "CCP frame for PCU";
CM_ BO_ 54 "CCP frame for PCU";
CM_ BO_ 53 "CCP frame for Charger";
CM_ BO_ 52 "CCP frame for Charger";
CM_ BO_ 49 "CCP frame for CDCM";
CM_ BO_ 48 "CCP frame for CDCM";
CM_ BO_ 57 "CCP frame for BMS";
CM_ BO_ 56 "CCP frame for BMS";
CM_ SG_ 774 BatteryLinearAge "Value 0 shall be indicated when the battery was manufactured. Value 20000 shall indicate that the battery has just reached its estimated expected lifetime. Signal should increment pass 20000 in a normal way once achieved.";
CM_ SG_ 774 EquivalentInternalResistance "Measurement of the battery equivalent internal resistance";
CM_ SG_ 773 sys_BMI_state "Signal used by the BMS to indicate the state he is currently functioning";
CM_ SG_ 773 Charge_Interrupt "think_img charge_chginterruptBMS.pdf ";
CM_ SG_ 773 SOCAdaptationOutOfRange "Applicable if the BSOC calculation can deviate too much from the real SOC and is no longer possible to adpat to the real SOC without consulting service personel. For Zebra, the 'EOC with SOC < 80%' fault has been triggered.";
CM_ SG_ 771 sys_currentMaxCharge "Real-time maximum traction battery charge/regen current limit (abs. value)";
CM_ SG_ 771 sys_voltageMaxCharge "Real-time maximum traction battery charge/regen voltage limit";
CM_ SG_ 770 sys_currentMaxDischarge "Real-time maximum traction battery discharge current limit (Abs. value)";
CM_ SG_ 770 sys_voltageMinDischarge "Real-time minimum traction battery discharge voltage limit";
CM_ SG_ 769 sys_dod "Traction Battery Depth of Discharge (DOD). Real-time master signal from the traction battery. Traction Battery State of charge (SOC) = 100 - DOD";
CM_ SG_ 769 sys_tempMean "Measured mean traction battery temperature";
CM_ SG_ 769 sys_voltage "Measured, real-time filtered, traction battery voltage ";
CM_ SG_ 775 sys_batteryType "Battery type read from LDM";
CM_ SG_ 775 sys_batterySN "Battery SN read from LDM";
CM_ SG_ 768 BMSHardwareTag "BMI hardware version identifier.";
CM_ SG_ 768 BMSSoftwareTag "Released BMI software version identifier.";
CM_ BO_ 783 "Period of transmission if node active: 30s";
CM_ SG_ 783 BatterySerialNumber2 "Least significant part of the battery serial number. Note, it is tied to the battery (chemistry), not BMS";
CM_ BO_ 782 "Period of transmission if node active: 30s";
CM_ SG_ 782 BatterySerialNumber1 "Most significant part of the battery serial number. Note, it is tied to the battery (chemistry), not BMS";
CM_ BO_ 528 "Period of transmission if node active: 14ms";
CM_ SG_ 528 ABSEvent "byttet_med_failed?";
CM_ SG_ 528 ABSFailed "byttet_med_event?";
CM_ SG_ 528 Brake1Counter "Increasing_counter_every_frame";
CM_ SG_ 528 PCM_Tyre_Unes_In_Calc_d "deprecated?";
CM_ SG_ 528 EBD_Failed_d "deprecated?";
CM_ SG_ 528 ABS_Enabled_By_User_d "deprecated?";
CM_ SG_ 528 ABS_Enabled_By_User "new?";
CM_ BO_ 615 "PCU or Traction Inverter (from diagvga)";
VAL_ 1091 VCUStoredBeltWarningLightSC 1 "Error present" 0 "Error not present";
VAL_ 1091 VCUStoredLowSOCSC 1 "Error present" 0 "Error not present";
VAL_ 1091 VCUStoredRearSeatBuckle2LightSC 1 "Error present" 0 "Error not present";
VAL_ 1091 VCUStoredReverseLightSC 1 "Error present" 0 "Error not present";
VAL_ 1091 VCUStoredRadioMuteSC 1 "Error present" 0 "Error not present";
VAL_ 1091 VCUStoredIllumOutputSC 1 "Error present" 0 "Error not present";
VAL_ 1091 VCUStoredNeutralLightSC 1 "Error present" 0 "Error not present";
VAL_ 1091 VCUStoredDriveEnableLightSC 1 "Error present" 0 "Error not present";
VAL_ 1091 VCUStoredOvertempLightSC 1 "Error present" 0 "Error not present";
VAL_ 1091 VCUStoredIndicationBarSupplySC 1 "Error present" 0 "Error not present";
VAL_ 1091 VCUStoredPowerLimitLightSC 1 "Error present" 0 "Error not present";
VAL_ 1091 VCUStoredTransceiverTXSC 1 "Error present" 0 "Error not present";
VAL_ 1091 VCUStoredElHazardLightSC 1 "Error present" 0 "Error not present";
VAL_ 1091 VCUStoredBrakeWarningLightSC 1 "Error present" 0 "Error not present";
VAL_ 1091 VCUStoredEconomyGaugeSC 1 "Error present" 0 "Error not present";
VAL_ 1091 VCUStoredTransceiverSupplySC 1 "Error present" 0 "Error not present";
VAL_ 1091 VCUStoredDischargeRequestSC 1 "Error present" 0 "Error not present";
VAL_ 1091 VCUStoredCrashLineSC 1 "Error present" 0 "Error not present";
VAL_ 1091 VCUStoredABSWarningLightSC 1 "Error present" 0 "Error not present";
VAL_ 1091 VCUStoredImmoLightSC 1 "Error present" 0 "Error not present";
VAL_ 1091 VCUStoredDriveLightSC 1 "Error present" 0 "Error not present";
VAL_ 1091 VCUStoredAuxBattLowLightSC 1 "Error present" 0 "Error not present";
VAL_ 1091 VCUStoredChargeLightSC 1 "Error present" 0 "Error not present";
VAL_ 1091 VCUStoredTPMSLightSC 1 "Error present" 0 "Error not present";
VAL_ 1091 VCUStoredSpeedGaugeSC 1 "Error present" 0 "Error not present";
VAL_ 1091 VCUStoredEconomyLightSC 1 "Error present" 0 "Error not present";
VAL_ 1091 VCUStoredOnPlugLightSC 1 "Error present" 0 "Error not present";
VAL_ 1091 VCUStoredChimeLineSC 1 "Error present" 0 "Error not present";
VAL_ 1091 VCUStoredSOCGaugeSC 1 "Error present" 0 "Error not present";
VAL_ 1091 VCUStoredMILLightSC 1 "Error present" 0 "Error not present";
VAL_ 1091 VCUStoredParkLightSC 1 "Error present" 0 "Error not present";
VAL_ 1091 VCUStoredAirbagLightSC 1 "Error present" 0 "Error not present";
VAL_ 1091 VCUStoredIgnitionSpeedSC 1 "Error present" 0 "Error not present";
VAL_ 1091 VCUStoredRearSeatBuckle1LightSC 1 "Error present" 0 "Error not present";
VAL_ 1092 VCUStoredImmoLightOC 1 "Error present" 0 "Error not present";
VAL_ 1092 VCUStoredReverseLightOC 1 "Error present" 0 "Error not present";
VAL_ 1092 VCUStoredDischargeRequestOC 1 "Error present" 0 "Error not present";
VAL_ 1092 VCUStoredPowerLimitLightOC 1 "Error present" 0 "Error not present";
VAL_ 1092 VCUStoredRearSeatBuckle1LightOC 1 "Error present" 0 "Error not present";
VAL_ 1092 VCUStoredTPMSLightOC 1 "Error present" 0 "Error not present";
VAL_ 1092 VCUStoredOvertempLightOC 1 "Error present" 0 "Error not present";
VAL_ 1092 VCUStoredSOCGaugeOC 1 "Error present" 0 "Error not present";
VAL_ 1092 VCUStoredCrashLineOC 1 "Error present" 0 "Error not present";
VAL_ 1092 VCUStoredIndicationBarSupplyOC 1 "Error present" 0 "Error not present";
VAL_ 1092 VCUStoredEconomyLightOC 1 "Error present" 0 "Error not present";
VAL_ 1092 VCUStoredAirbagLightOC 1 "Error present" 0 "Error not present";
VAL_ 1092 VCUStoredEconomyGaugeOC 1 "Error present" 0 "Error not present";
VAL_ 1092 VCUStoredTransceiverSupplyOC 1 "Error present" 0 "Error not present";
VAL_ 1092 VCUStoredDriveLightOC 1 "Error present" 0 "Error not present";
VAL_ 1092 VCUStoredAuxBattLowLightOC 1 "Error present" 0 "Error not present";
VAL_ 1092 VCUStoredRearSeatBuckle2LightOC 1 "Error present" 0 "Error not present";
VAL_ 1092 VCUStoredIgnitionSpeedOC 1 "Error present" 0 "Error not present";
VAL_ 1092 VCUStoredMILLightOC 1 "Error present" 0 "Error not present";
VAL_ 1092 VCUStoredChimeLineOC 1 "Error present" 0 "Error not present";
VAL_ 1092 VCUStoredDriveEnableLightOC 1 "Error present" 0 "Error not present";
VAL_ 1092 VCUStoredLowSOCOC 1 "Error present" 0 "Error not present";
VAL_ 1092 VCUStoredElHazardLightOC 1 "Error present" 0 "Error not present";
VAL_ 1092 VCUStoredBrakeWarningLightOC 1 "Error present" 0 "Error not present";
VAL_ 1092 VCUStoredIllumOutputOC 1 "Error present" 0 "Error not present";
VAL_ 1092 VCUStoredABSWarningLightOC 1 "Error present" 0 "Error not present";
VAL_ 1092 VCUStoredTransceiverTXOC 1 "Error present" 0 "Error not present";
VAL_ 1092 VCUStoredBeltWarningLightOC 1 "Error present" 0 "Error not present";
VAL_ 1092 VCUStoredSpeedGaugeOC 1 "Error present" 0 "Error not present";
VAL_ 1092 VCUStoredRadioMuteOC 1 "Error present" 0 "Error not present";
VAL_ 1092 VCUStoredParkLightOC 1 "Error present" 0 "Error not present";
VAL_ 1092 VCUStoredNeutralLightOC 1 "Error present" 0 "Error not present";
VAL_ 1092 VCUStoredChargeLightOC 1 "Error present" 0 "Error not present";
VAL_ 1092 VCUStoredOnPlugLightOC 1 "Error present" 0 "Error not present";
VAL_ 1089 VCUPresentMILLightSC 1 "Error present" 0 "Error not present";
VAL_ 1089 VCUPresentImmoLightSC 1 "Error present" 0 "Error not present";
VAL_ 1089 VCUPresentEconomyLightSC 1 "Error present" 0 "Error not present";
VAL_ 1089 VCUPresentTransceiverSupplySC 1 "Error present" 0 "Error not present";
VAL_ 1089 VCUPresentIgnitionSpeedSC 1 "Error present" 0 "Error not present";
VAL_ 1089 VCUPresentChimeLineSC 1 "Error present" 0 "Error not present";
VAL_ 1089 VCUPresentElHazardLightSC 1 "Error present" 0 "Error not present";
VAL_ 1089 VCUPresentBrakeWarningLightSC 1 "Error present" 0 "Error not present";
VAL_ 1089 VCUPresentRadioMuteSC 1 "Error present" 0 "Error not present";
VAL_ 1089 VCUPresentSOCGaugeSC 1 "Error present" 0 "Error not present";
VAL_ 1089 VCUPresentNeutralLightSC 1 "Error present" 0 "Error not present";
VAL_ 1089 VCUPresentParkLightSC 1 "Error present" 0 "Error not present";
VAL_ 1089 VCUPresentChargeLightSC 1 "Error present" 0 "Error not present";
VAL_ 1089 VCUPresentEconomyGaugeSC 1 "Error present" 0 "Error not present";
VAL_ 1089 VCUPresentCrashLineSC 1 "Error present" 0 "Error not present";
VAL_ 1089 VCUPresentTransceiverTXSC 1 "Error present" 0 "Error not present";
VAL_ 1089 VCUPresentReverseLightSC 1 "Error present" 0 "Error not present";
VAL_ 1089 VCUPresentAirbagLightSC 1 "Error present" 0 "Error not present";
VAL_ 1089 VCUPresentIndicationBarSupplySC 1 "Error present" 0 "Error not present";
VAL_ 1089 VCUPresentDriveLightSC 1 "Error present" 0 "Error not present";
VAL_ 1089 VCUPresentRearSeatBuckle1LightSC 1 "Error present" 0 "Error not present";
VAL_ 1089 VCUPresentDischargeRequestSC 1 "Error present" 0 "Error not present";
VAL_ 1089 VCUPresentAuxBattLowLightSC 1 "Error present" 0 "Error not present";
VAL_ 1089 VCUPresentDriveEnableLightSC 1 "Error present" 0 "Error not present";
VAL_ 1089 VCUPresentLowSOCSC 1 "Error present" 0 "Error not present";
VAL_ 1089 VCUPresentBeltWarningLightSC 1 "Error present" 0 "Error not present";
VAL_ 1089 VCUPresentSpeedGaugeSC 1 "Error present" 0 "Error not present";
VAL_ 1089 VCUPresentABSWarningLightSC 1 "Error present" 0 "Error not present";
VAL_ 1089 VCUPresentOvertempLightSC 1 "Error present" 0 "Error not present";
VAL_ 1089 VCUPresentOnPlugLightSC 1 "Error present" 0 "Error not present";
VAL_ 1089 VCUPresentIllumOutputSC 1 "Error present" 0 "Error not present";
VAL_ 1089 VCUPresentPowerLimitLightSC 1 "Error present" 0 "Error not present";
VAL_ 1089 VCUPresentTPMSLightSC 1 "Error present" 0 "Error not present";
VAL_ 1089 VCUPresentRearSeatBuckle2LightSC 1 "Error present" 0 "Error not present";
VAL_ 1090 VCUPresentIndicationBarSupplyOC 1 "Error present" 0 "Error not present";
VAL_ 1090 VCUPresentLowSOCOC 1 "Error present" 0 "Error not present";
VAL_ 1090 VCUPresentOvertempLightOC 1 "Error present" 0 "Error not present";
VAL_ 1090 VCUPresentEconomyLightOC 1 "Error present" 0 "Error not present";
VAL_ 1090 VCUPresentParkLightOC 1 "Error present" 0 "Error not present";
VAL_ 1090 VCUPresentRadioMuteOC 1 "Error present" 0 "Error not present";
VAL_ 1090 VCUPresentElHazardLightOC 1 "Error present" 0 "Error not present";
VAL_ 1090 VCUPresentBeltWarningLightOC 1 "Error present" 0 "Error not present";
VAL_ 1090 VCUPresentDriveEnableLightOC 1 "Error present" 0 "Error not present";
VAL_ 1090 VCUPresentImmoLightOC 1 "Error present" 0 "Error not present";
VAL_ 1090 VCUPresentAirbagLightOC 1 "Error present" 0 "Error not present";
VAL_ 1090 VCUPresentSOCGaugeOC 1 "Error present" 0 "Error not present";
VAL_ 1090 VCUPresentSpeedGaugeOC 1 "Error present" 0 "Error not present";
VAL_ 1090 VCUPresentRearSeatBuckle2LightOC 1 "Error present" 0 "Error not present";
VAL_ 1090 VCUPresentReverseLightOC 1 "Error present" 0 "Error not present";
VAL_ 1090 VCUPresentIllumOutputOC 1 "Error present" 0 "Error not present";
VAL_ 1090 VCUPresentBrakeWarningLightOC 1 "Error present" 0 "Error not present";
VAL_ 1090 VCUPresentTransceiverSupplyOC 1 "Error present" 0 "Error not present";
VAL_ 1090 VCUPresentABSWarningLightOC 1 "Error present" 0 "Error not present";
VAL_ 1090 VCUPresentTransceiverTXOC 1 "Error present" 0 "Error not present";
VAL_ 1090 VCUPresentDriveLightOC 1 "Error present" 0 "Error not present";
VAL_ 1090 VCUPresentPowerLimitLightOC 1 "Error present" 0 "Error not present";
VAL_ 1090 VCUPresentCrashLineOC 1 "Error present" 0 "Error not present";
VAL_ 1090 VCUPresentIgnitionSpeedOC 1 "Error present" 0 "Error not present";
VAL_ 1090 VCUPresentAuxBattLowLightOC 1 "Error present" 0 "Error not present";
VAL_ 1090 VCUPresentChargeLightOC 1 "Error present" 0 "Error not present";
VAL_ 1090 VCUPresentOnPlugLightOC 1 "Error present" 0 "Error not present";
VAL_ 1090 VCUPresentNeutralLightOC 1 "Error present" 0 "Error not present";
VAL_ 1090 VCUPresentEconomyGaugeOC 1 "Error present" 0 "Error not present";
VAL_ 1090 VCUPresentChimeLineOC 1 "Error present" 0 "Error not present";
VAL_ 1090 VCUPresentRearSeatBuckle1LightOC 1 "Error present" 0 "Error not present";
VAL_ 1090 VCUPresentTPMSLightOC 1 "Error present" 0 "Error not present";
VAL_ 1090 VCUPresentDischargeRequestOC 1 "Error present" 0 "Error not present";
VAL_ 1090 VCUPresentMILLightOC 1 "Error present" 0 "Error not present";
VAL_ 929 KeyOnGearPosition 7 "Fault" 4 "Economy" 3 "Drive" 2 "Neutral" 1 "Reverse" 0 "Park";
VAL_ 929 VehicleState 2 "KeyOn" 1 "OnPlug" 0 "Off";
VAL_ 592 LEDIndication 5 "Off Plug" 4 "Slow Blink" 3 "Fast Blink" 2 "Flashing fault code" 1 "On" 0 "Off";
VAL_ 592 KeyStatus 3 "Deafult" 2 "Disable" 1 "Enable" 0 "Reading";
VAL_ 837 TPMSLearnLastResult 2 "Learn timeout" 1 "Learn success" 0 "No result";
VAL_ 837 TPMSTelltaleControl 2 "NHTSA MIL telltale On" 1 "NHTSA telltale On" 0 "NHTSA telltale Off";
VAL_ 837 TPMSWarning_RR 7 "Missing sensor" 6 "Normal" 5 "Fast deflation" 2 "Very Low (RED)" 0 "Unknown state";
VAL_ 837 TPMSLearnStatus 2 "Button learn in progress" 1 "Diagnostic learn in progress" 0 "No learn started";
VAL_ 837 TPMSWarning_LF 7 "Missing sensor" 6 "Normal" 5 "Fast deflation" 2 "Very Low (RED)" 0 "Unknown state";
VAL_ 837 TPMSWarning_LR 7 "Missing sensor" 6 "Normal" 5 "Fast deflation" 2 "Very Low (RED)" 0 "Unknown state";
VAL_ 837 TPMSWarning_RF 7 "Missing sensor" 6 "Normal" 5 "Fast deflation" 2 "Very Low (RED)" 0 "Unknown state";
VAL_ 1552 BMS_Highest_Error_Reason  0 "(0) No Error" 1 "(1) PCU Fault" 2 "(2) No Charge Current" 3 "(3) Circuit Board Tempertaure Warning" 4 "(4) Current Limit On Low Temperature" 5 "(5) Current Limit On High Temperature" 6 "(6) Extenal Isolation Fault" 7 "(7) Internal Isolation Fault" 8 "(8) Fuel Cutoff (Crash Event Notification)" 9 "(9) Airbag Deployed" 10 "(10) No PCU Data Received (Messages 310 and 311)" 11 "(11) PreCharge Short Circuit Fault" 12 "(12) PreCharge Retry Fault" 13 "(13) Circuit Board Over Temperature Fault" 14 "(14) Pack Under Temperature Fault" 15 "(15) Pack Over Temperature Fault"16 "(16) Pack Over Current Fault" 17 "(17) Cell Under Voltage Fault" 18 "(18) Cell Over Voltage Fault" 19 "(19) Contactor 2 Stuck On Fault (S)" 20 "(20) Secondary Contactor Open Fault" 21 "(21) Loss Of Emergency Power Off Signal" 22 "(22) Circuit Board Under Temperature Fault" 23 "(23) Contactor 1 Stuck On Fault (S)" 24 "(24) Slave Data Not Received Fault" 25 "(25) Powerup Self Test Fault" 26 "(26) Secondary Contactor Stuck On Fault" 27 "(27) Contactor Dropout Fault" 28 "(28) Fan Current Low Fault" 29 "(29) Fan Current High Fault" 30 "(30) Aux Batt Under Volt Fault" 31 "(31) Contactor 1 Stuck Open Fault" 32 "(32) Contactor 2 Stuck Open Fault" 33 "(33) Discharge During Charge Fault" 34 "(34) Key Cycle Category Fault" 35 "(35) Service Category Fault" 36 "(36) High Contactor Coil Current Fault" 37 "(37) Cell Voltage Connection Fault (S)" 38 "(38) Extreme Undervoltage Fault (S)" 39 "(39) One Current Sensor Fault" 40 "(40) Both Current Sensors Fault" 41 "(41) Low Current Correlation Fault" 42 "(42) High Current Correlation Fault" 43 "(43) Pack Voltage Sensor Fault" 44 "(44) String Voltage Mismatch Fault" 45 "(45) Aux Batt Under Volt Warning" 46 "(46) Main Contactor Open Timeout Fault" 47 "(47) PTC Heater Fault (S)" 48 "(48) CellV Compare Fault" 49 "(49)_ModuleV To CellV Compare Fault" 50 "(50) Low Module Voltage Fault" 51 "(51) No CAN Contactor Request (Not used for A306)";
VAL_ 1120 RIL_Request 3 "RIL Requested On" 2 "RIL Requested Plant Mode" 1 "Reserved" 0 "RIL Requested Off";
VAL_ 35 RCM_FuelCutOff 2 "Normal Operation" 1 "Terminate Fuel" 0 "Invalid";
VAL_ 35 RCM_EventNotification 1 "Airbag Deployed" 0 "Inactive";
VAL_ 1874 VIN_Index 3 "Third PArt of VIN number" 2 "Second part of VIN number" 1 "First part of VIN number" 0 "Invalid";
VAL_ 1027 TimeMonth 11 "December" 10 "November" 9 "October" 8 "September" 7 "August" 6 "July" 5 "June" 4 "May" 3 "April" 2 "March" 1 "February" 0 "January";
VAL_ 1027 TimeDayInWeek 6 "Saturday" 5 "Friday" 4 "Thursday" 3 "Wednesday" 2 "Tuesday" 1 "Monday" 0 "Sunday";
VAL_ 1025 MemoryManagementStatus 1 "Lock" 0 "Free";
VAL_ 1025 AirbagLampDriver 3 "Lamptest" 2 "RCM timeout" 1 "RCM command" 0 "Reserved";
VAL_ 1025 HelpDeskLampStatus 4 "Blinking 2Hz Error" 3 "Blinking 2Hz" 2 "Blinking 0.5Hz" 1 "On" 0 "Off";
VAL_ 1025 PhoneCallStatus 4 "Reserved" 3 "In call" 2 "Incoming call" 1 "Calling" 0 "No call";
VAL_ 1025 GPRSStatus 5 "Registered, roaming" 3 "Registration denied" 2 "Not registered" 1 "Registered" 0 "Not registered, not searching";
VAL_ 1025 InCommunication 1 "Communicating via GPRS" 0 "Not communicating via GPRS";
VAL_ 1025 GPSAntennaStatus 2 "Short detected" 1 "OK" 0 "Open detected";
VAL_ 1025 CarState 2 "Charge" 1 "Discharge" 0 "Park";
VAL_ 1025 BluetoothConnection 1 "Connected to 1 device" 0 "Not connected";
VAL_ 1025 BluetoothStatus 1 "On and ready" 0 "Not available or Off";
VAL_ 1025 GPSStatus 15 "Not allowed by user in maintenance server" 11 "Only 3 usable satellites" 10 "Only 2 usable satellites" 9 "Only 1 usable satellite" 8 "No usable satellites" 3 "PDOP is too high" 1 "Doing position fixes" 0 "GPS Time not received yet";
VAL_ 1025 ContactKey 1 "Key Run active" 0 "Key Run not active";
VAL_ 1025 SIMCardStatus 1 "OK" 0 "Not inserted or PIN error";
VAL_ 1025 HelpDeskRequest 1 "Request" 0 "No request";
VAL_ 1025 GSMStatus 5 "Registered, roaming" 3 "Registration denied" 2 "Not registered" 1 "Registered" 0 "Not registered, not searching";
VAL_ 1025 GPSModuleStatus 3 "Error" 2 "starting / Waking Up" 1 "Ready" 0 "Off / Asleep";
VAL_ 1025 CSQQuality 31 "-51dBm or greater" 30 "-53dBm" 29 "-55dBm" 28 "-57dBm" 27 "-59dBm" 26 "-61dBm" 25 "-63dBm" 24 "-65dBm" 23 "-67dBm" 22 "-69dBm" 21 "-71dBm" 20 "-73dBm" 19 "-75dBm" 18 "-77dBm" 17 "-79dBm" 16 "-81dBm" 15 "-83dBm" 14 "-85dBm" 13 "-87dBm" 12 "-89dBm" 11 "-91dBm" 10 "-93dBm" 9 "-95dBm" 8 "-97dBm" 7 "-99dBm" 6 "-101dBm" 5 "-103dBm" 4 "-105dBm" 3 "-107dBm" 2 "-109dBm" 1 "-111dBm" 0 "-113dBm or less";
VAL_ 1025 ConnectedToServer 1 "Connected" 0 "Not connected";
VAL_ 1025 AirbagLampStatus 3 "On" 2 "Blinking (5Hz)" 0 "Off";
VAL_ 1025 HelpDeskButtonStatus 1 "Pushed" 0 "Not pushed";
VAL_ 1025 GSMModuleStatus 3 "Error" 2 "starting / Waking Up" 1 "Ready" 0 "Off / Asleep";
VAL_ 1025 AssistNumberProgrammed 1 "Programmed" 0 "Not programmed";
VAL_ 1025 EPOStatus 1 "On" 0 "Off";
VAL_ 1025 CrashEvent 1 "Airbag deployed" 0 "No event";
VAL_ 1026 CarSharingButtonStatus 1 "Pushed" 0 "Not pushed";
VAL_ 1026 CarSharingAntitheft 1 "Enabled, car is not able to start" 0 "Disabled, car is possible to start";
VAL_ 1026 CarSharingMode 3 "Maintenance" 2 "Manager" 1 "Normal" 0 "Test";
VAL_ 1026 CarSharingState 6 "Wait close" 5 "Running" 4 "Try to start" 3 "Waiting driver" 2 "Ready" 1 "Waiting begin time" 0 "Free";
VAL_ 1026 CarSharingLEDStatus 2 "Late" 1 "Reservation" 0 "Free, end request";
VAL_ 785 FastChargeRequest 1 "Fast charge request" 0 "No fast charge request";
VAL_ 785 BatteryChargeRequest 1 "Battery charge requested" 0 "Battery charge not requested";
VAL_ 785 VehicleChargeRequest 1 "Vehicle_charge_request" 0 "No_vehicle_charge_request";
VAL_ 514 BrakeLightSwitch 1 "Active" 0 "Not active";
VAL_ 514 MotorTorqueInsDenied 1 "Requested ESP torque is out of motor capacity" 0 "Motor torque controlled by DTR or ESP";
VAL_ 784 TIM_Status 1 "TIM enabled" 0 "TIM disabled";
VAL_ 784 Charger_Status 1 "Charge enabled" 0 "Charge disabled";
VAL_ 784 DC_DC_Status 1 "DC-DC Enabled" 0 "DC-DC disabled";
VAL_ 784 PCU_Fault 1 "PCU detected an error" 0 "PCU OK";
VAL_ 784 BroadcastMode 1 "Broadcast Mode" 0 "Request Mode";
VAL_ 612 PASEnable 1 "Power allowed to PAS" 0 "No power allowed to PAS";
VAL_ 612 ESPIndication 3 "Light Flashing Fast" 2 "Light Flashing Slow" 1 "Light On" 0 "Light Off";
VAL_ 612 PowerLimitIndication 3 "Light Flashing Fast" 2 "Light Flashing Slow" 1 "Light On" 0 "Light Off";
VAL_ 612 EconomyIndication 3 "Light Flashing Fast" 2 "Light Flashing Slow" 1 "Light On" 0 "Light Off";
VAL_ 612 ABSWarningIndication 3 "Light Flashing Fast" 2 "Light Flashing Slow" 1 "Light On" 0 "Light Off";
VAL_ 612 ElectricHzIndication 3 "Light Flashing Fast" 2 "Light Flashing Slow" 1 "Light On" 0 "Light Off";
VAL_ 612 BrakeWarningIndication 3 "Light Flashing Fast" 2 "Light Flashing Slow" 1 "Light On" 0 "Light Off";
VAL_ 612 OvertempIndication 3 "Light Flashing Fast" 2 "Light Flashing Slow" 1 "Light On" 0 "Light Off";
VAL_ 612 NeutralIndication 3 "Light Flashing Fast" 2 "Light Flashing Slow" 1 "Light On" 0 "Light Off";
VAL_ 612 MILIndication 3 "Light Flashing Fast" 2 "Light Flashing Slow" 1 "Light On" 0 "Light Off";
VAL_ 612 PowertrainGeneration 3 "Gen 4" 2 "Gen 3" 1 "Gen 2" 0 "Gen 1";
VAL_ 612 ChargingIndication 3 "Light Flashing Fast" 2 "Light Flashing Slow" 1 "Light On" 0 "Light Off";
VAL_ 612 AuxiliaryBatteryLowIndication 3 "Light Flashing Fast" 2 "Light Flashing Slow" 1 "Light On" 0 "Light Off";
VAL_ 612 DriveEnableIndication 3 "Light Flashing Fast" 2 "Light Flashing Slow" 1 "Light On" 0 "Light Off";
VAL_ 612 OnPlugIndication 3 "Light Flashing Fast" 2 "Light Flashing Slow" 1 "Light On" 0 "Light Off";
VAL_ 612 GearPosition 7 "Fault" 4 "Economy" 3 "Drive" 2 "Neutral" 1 "Reverse" 0 "Park";
VAL_ 612 ParkIndication 3 "Light Flashing Fast" 2 "Light Flashing Slow" 1 "Light On" 0 "Light Off";
VAL_ 612 ReverseIndication 3 "Light Flashing Fast" 2 "Light Flashing Slow" 1 "Light On" 0 "Light Off";
VAL_ 612 LowSOCIndication 3 "Light Flashing Fast" 2 "Light Flashing Slow" 1 "Light On" 0 "Light Off";
VAL_ 612 PilotSignalPresent 1 "Pilot signal is present and accepted" 0 "Pilot signal is not present and/or accepted";
VAL_ 612 DriveIndication 3 "Light Flashing Fast" 2 "Light Flashing Slow" 1 "Light On" 0 "Light Off";
VAL_ 593 SecurityIDActive 2 "Refused" 1 "Active" 0 "Not Active";
VAL_ 593 VehicleStatus 2 "Disabled" 1 "Enabled" 0 "Wait";
VAL_ 850 EnableCharger 1 "Description for the value '0x1'" 0 "Charger is not enabled";
VAL_ 1173 PAS_Status 1 "Error in PAS." 0 "OK";
VAL_ 391 SASState 1 "SAS signals healthy" 0 "SAS signal error";
VAL_ 391 SASCal 1 "SAS calibrated" 0 "SAS NOT calibrated";
VAL_ 391 SASTrim 1 "SAS Trim" 0 "SAS NOT Trim";
VAL_ 390 ESPSystemStatus 3 "Incomplete startup" 2 "Siagnostic session active" 1 "ESP system error" 0 "ESP system operational";
VAL_ 390 EBDStatus 1 "EBD error" 0 "EBD operational";
VAL_ 390 ESPStatus 1 "ESP error" 0 "ESP operational";
VAL_ 390 ABSStatus 1 "ABS error" 0 "ABS operational";
VAL_ 390 ESPLamp 3 "Light flash fast (2Hz)" 2 "Light flash slow (0.5Hz)" 1 "Light On" 0 "Light Off";
VAL_ 390 ESPTorqueIntervention 1 "Intervention" 0 "No intervention";
VAL_ 390 ABSLamp 3 "Light flash fast (2Hz)" 2 "Light flash slow (0.5Hz)" 1 "Light On" 0 "Light Off";
VAL_ 390 EBDLamp 3 "Light flash fast (2Hz)" 2 "Light flash slow (0.5Hz)" 1 "Light On" 0 "Light Off";
VAL_ 851 ChargerStatus 4 "Non-Recoverable Error" 3 "Recoverable Error" 2 "Charge" 1 "Ready";
VAL_ 853 CommunicationFailure 1 "Error present" 0 "Error not present";
VAL_ 853 LowMainsError 1 "Error present" 0 "Error not present";
VAL_ 853 DCUndervoltageError 1 "Error present" 0 "Error not present";
VAL_ 853 CurrentLimitError 1 "Error present" 0 "Error not present";
VAL_ 853 HighTemperatureShutdownError 1 "Error present" 0 "Error not present";
VAL_ 853 HighMainsError 1 "Error present" 0 "Error not present";
VAL_ 853 DCOvervoltageError 1 "Error present" 0 "Error not present";
VAL_ 853 ControllerCommunicationError 1 "Error present" 0 "Error not present";
VAL_ 853 ModuleFailureError 1 "Error present" 0 "Error not present";
VAL_ 853 LowTemperatureShutdownError 1 "Error present" 0 "Error not present";
VAL_ 1032 ACPresent 1 "Description for the value '0x1'" 0 "AC not present";
VAL_ 1032 CDCMOperationState 5 "Charge" 4 "Limphome" 3 "Shutdown" 2 "Run" 1 "On" 0 "StartUp";
VAL_ 69 PTCFeedbackStatus 3 "Shorted or Open Line" 2 "Other Failure State" 1 "HV Missing" 0 "No Problem";
VAL_ 69 PTCControlStatus 6 "5 Elements ON" 5 "4 Elements ON" 4 "3 Elements ON" 3 "2 Elements ON" 2 "1 Element ON" 1 "Monitor HV" 0 "Off";
VAL_ 69 PTCHeaterStatus 1 "On" 0 "Off";
VAL_ 69 PTC_FuelCutOff 2 "Normal operation" 1 "Terminate Fuel" 0 "Communication broken with PTC";
VAL_ 1033 KnobPositionTooHigh 1 "Fault present" 0 "Fault not present";
VAL_ 1033 CondenserFanOC 1 "Fault present" 0 "Fault not present";
VAL_ 1033 RearDemistSC 1 "Fault present" 0 "Fault not present";
VAL_ 1033 HVrequestSC 1 "Fault present" 0 "Fault not present";
VAL_ 1033 FrontDemist2OC 1 "Fault present" 0 "Fault not present";
VAL_ 1033 ClimateCANTimeout 1 "Fault present" 0 "Fault not present";
VAL_ 1033 KnobPositionTooLow 1 "Fault present" 0 "Fault not present";
VAL_ 1033 HeaterEnableOC 1 "Fault present" 0 "Fault not present";
VAL_ 1033 HeaterEnableSC 1 "Fault present" 0 "Fault not present";
VAL_ 1033 CondenserFanSC 1 "Fault present" 0 "Fault not present";
VAL_ 1033 ForcedBlowerOC 1 "Fault present" 0 "Fault not present";
VAL_ 1033 InverterSupplyOC 1 "Fault present" 0 "Fault not present";
VAL_ 1033 FrontDemist1SC 1 "Fault present" 0 "Fault not present";
VAL_ 1033 ForcedBlowerSC 1 "Fault present" 0 "Fault not present";
VAL_ 1033 RearDemistOC 1 "Fault present" 0 "Fault not present";
VAL_ 1033 TemperatureSensorSignalTooLow 1 "Fault present" 0 "Fault not present";
VAL_ 1033 TemperatureSensorSignalTooHigh 1 "Fault present" 0 "Fault not present";
VAL_ 1033 InverterSupplySC 1 "Fault present" 0 "Fault not present";
VAL_ 1033 FrontDemist2SC 1 "Fault present" 0 "Fault not present";
VAL_ 1033 FrontDemist1OC 1 "Fault present" 0 "Fault not present";
VAL_ 1033 HVRequestOC 1 "Fault present" 0 "Fault not present";
VAL_ 773 sys_intIsoError 1 "Internal HV iso error detected" 0 "OK";
VAL_ 773 Charge_Overcurrent 1 "Charge current > max. battery charge current" 0 "OK";
VAL_ 773 sys_BMI_state 15 "Fault" 8 "PowerUp" 3 "Charge" 1 "Discharge" 0 "Park";
VAL_ 773 Battery_Type 3 "A123 Li-Ion" 2 "EnerDel Li-Ion" 1 "Z5" 0 "Z36";
VAL_ 773 BatteryChargeEN 1 "Battery contactors closed for charge" 0 "Battery contactors open.";
VAL_ 773 Waiting_OK_Temp_Discharge 1 "Discharge delayed until correct Temp" 0 "No delay in discharge";
VAL_ 773 sys_extIsoError 1 "External HV iso error detected" 0 "OK";
VAL_ 773 sys_BMITempError 3 "BMS critical overtemp fault reached. Immediate shutdown" 2 "BMS overtemp level 2 reached." 1 "BMS overtemp level 1 reached." 0 "No error";
VAL_ 773 No_Charge_Current 1 "No charging current into battery" 0 "OK";
VAL_ 773 Charge_Interrupt 1 "Interrupt charging" 0 "Do not interrupt charging";
VAL_ 773 Charge_Overvoltage 1 "Charge voltage > max. battery charge current" 0 "OK";
VAL_ 773 sys_thermalIsoError 1 "Thermal iso error detected" 0 "OK";
VAL_ 773 SOCAdaptationOutOfRange 1 "Calculated SOC is out of range for autocalibration" 0 "No Error";
VAL_ 773 sys_ZebraTempError 3 "Battery pack critical overtemp reached. Immediate shutdown" 2 "Battery pack overtemp warning level 2 reached." 1 "Battery pack overtemp warning level 1 reached. Introducing LOS" 0 "No error";
VAL_ 772 AC_Heater_Relay_Status 1 "AC heater realay enabled" 0 "AC heater relay disabled";
VAL_ 772 Too_Many_Failed_Cells 1 "More than 10% failed cells" 0 "Less than 10% failed cells";
VAL_ 772 Waiting_OK_Temp_Charge 1 "Charge delayed until correct Temp" 0 "No delay in charge";
VAL_ 772 sys_highestErrCat 4 "Category switch-off" 3 "Category delayed switch-off" 2 "Category notice" 1 "RESERVED" 0 "No error";
VAL_ 772 Reach_EOC_please 1 "Battery needs to reach EOC" 0 "Invalid";
VAL_ 772 AC_Heater_Switch_Status 1 "AC heater switch closed" 0 "AC heater switch opened";
VAL_ 770 sys_isoerror 1 "Int. or Ext. ISO fault";
VAL_ 770 sys_errGeneral 1 "General error active";
VAL_ 768 BMI_Init_Successful 1 "Init OK, BMI ready" 0 "Error ocurred";
VAL_ 1827 00_Bus_Voltage_AD_Fault 0 "OK" 1 "FAULT";
VAL_ 1827 01_Pack_Voltage_AD_Fault 0 "OK" 1 "FAULT";
VAL_ 1827 02_Pack_Current_B_hi_AD_Fault 0 "OK" 1 "FAULT";
VAL_ 1827 03_Pack_Current_B_lo_AD_Fault 0 "OK" 1 "FAULT";
VAL_ 1827 04_Pack_Current_A_hi_AD_Fault 0 "OK" 1 "FAULT";
VAL_ 1827 05_Pack_Current_A_lo_AD_Fault 0 "OK" 1 "FAULT";
VAL_ 1827 06_Board_Under_Temp_Fault 0 "OK" 1 "FAULT";
VAL_ 1827 07_Secondary_Contactor_Stuck_On_Fault 0 "OK" 1 "FAULT";
VAL_ 1827 08_Internal_Isolation_Fault 0 "OK" 1 "FAULT";
VAL_ 1827 09_External_Isolation_Fault 0 "OK" 1 "FAULT";
VAL_ 1827 10_Secondary_Contactor_A_Open_Fault 0 "OK" 1 "FAULT";
VAL_ 1827 11_Contactor_Precharge_Short_Fault 0 "OK" 1 "FAULT";
VAL_ 1827 12_Contactor_1_Dropout_Second_Fault 0 "OK" 1 "FAULT";
VAL_ 1827 13_Contactor_1_Dropout_First_Fault 0 "OK" 1 "FAULT";
VAL_ 1827 14_Contactor_Precharge_Retry_Fault 0 "OK" 1 "FAULT";
VAL_ 1827 15_Contactor_Precharge_Timeout_Fault 0 "OK" 1 "FAULT";
VAL_ 1827 16_Redundant_Cell_Voltage_Comparison_Fault 0 "OK" 1 "FAULT";
VAL_ 1827 17_Contactor_2_Stuck_On_Fault 0 "OK" 1 "FAULT";
VAL_ 1827 18_No_Charge_Current_Fault 0 "OK" 1 "FAULT";
VAL_ 1827 19_Board_Over_Temp_Fault 0 "OK" 1 "FAULT";
VAL_ 1827 20_Pack_Under_Temp_Fault 0 "OK" 1 "FAULT";
VAL_ 1827 21_Pack_Over_Temp_Fault 0 "OK" 1 "FAULT";
VAL_ 1827 22_Fan_Current_Low_Fault 0 "OK" 1 "FAULT";
VAL_ 1827 23_Fan_Current_High_Fault 0 "OK" 1 "FAULT";
VAL_ 1827 24_Module_Volt_To_Cell_Volt_Comparison_Fault 0 "OK" 1 "FAULT";
VAL_ 1827 25_Contactor_1_Stuck_On_Fault 0 "OK" 1 "FAULT";
VAL_ 1827 26_Cell_Under_Voltage_B_Fault 0 "OK" 1 "FAULT";
VAL_ 1827 27_Cell_Under_Voltage_A_Fault 0 "OK" 1 "FAULT";
VAL_ 1827 28_Cell_Over_Voltage_B_Fault 0 "OK" 1 "FAULT";
VAL_ 1827 29_Cell_Over_Voltage_A_Fault 0 "OK" 1 "FAULT";
VAL_ 1827 30_Pack_Over_Voltge_Fault 0 "OK" 1 "FAULT";
VAL_ 1827 31_SPI_Timeout_Fault 0 "OK" 1 "FAULT";
VAL_ 1827 32_Countactor_2_Dropout_2nd_Fault 0 "OK" 1 "FAULT";
VAL_ 1827 33_Countactor_2_Dropout_1st_Fault 0 "OK" 1 "FAULT";
VAL_ 1827 34_Countactor_1_Dropout_2nd_Fault 0 "OK" 1 "FAULT";
VAL_ 1827 35_Countactor_1_Dropout_1st_Fault 0 "OK" 1 "FAULT";
VAL_ 1827 36_Secondary_Contactor_B_Open_Fault 0 "OK" 1 "FAULT";
VAL_ 1827 37_No_PCU_Data_Received_Fault 0 "OK" 1 "FAULT";
VAL_ 1827 38_Pack_Over_Current_Regulation_Fault 0 "OK" 1 "FAULT";
VAL_ 1827 39_In_12V_Under_Voltage_Fault 0 "OK" 1 "FAULT";
VAL_ 1827 40_Low_Level_Discharge_During_Charge_Fault 0 "OK" 1 "FAULT";
VAL_ 1827 41_High_Level_Discharge_During_Charge_Fault 0 "OK" 1 "FAULT";
VAL_ 1827 42_Internal_Slave_No_Data_Fault 0 "OK" 1 "FAULT";
VAL_ 1827 43_Voltages_Mismach_Fault 0 "OK" 1 "FAULT";
VAL_ 1827 44_In_12V_Under_Voltage_Warning 0 "OK" 1 "FAULT";
VAL_ 1827 45_High_Contactor_Coil_Current_Fault 0 "OK" 1 "FAULT";
VAL_ 1827 46_Cell_Voltage_Connection_Fault 0 "OK" 1 "FAULT";
VAL_ 1827 47_Extreme_Cell_Under_Voltage_Fault 0 "OK" 1 "FAULT";
VAL_ 1827 48_Low_Current_Sensor_Correlation_Fault 0 "OK" 1 "FAULT";
VAL_ 1827 49_High_Current_Sensor_Correlation_Fault 0 "OK" 1 "FAULT";
VAL_ 1827 50_Main_Contactor_Open_Timeout_Fault 0 "OK" 1 "FAULT";
VAL_ 1827 51_PTC_Heater_Fault 0 "OK" 1 "FAULT";
VAL_ 1827 52_Pack_Temperature_AD_Fault 0 "OK" 1 "FAULT";
VAL_ 1827 53_Low_Module_Voltage_Fault 0 "OK" 1 "FAULT";
VAL_ 528 Torque_Type 0 "(0)_Powertrain_Torque" 1 "(1)_Enginge_Torque";
VAL_ 1826 00_Bus_Voltage_AD_Fault 0 "OK" 1 "FAULT";
VAL_ 1826 01_Pack_Voltage_AD_Fault 0 "OK" 1 "FAULT";
VAL_ 1826 02_Pack_Current_B_hi_AD_Fault 0 "OK" 1 "FAULT";
VAL_ 1826 03_Pack_Current_B_lo_AD_Fault 0 "OK" 1 "FAULT";
VAL_ 1826 04_Pack_Current_A_hi_AD_Fault 0 "OK" 1 "FAULT";
VAL_ 1826 05_Pack_Current_A_lo_AD_Fault 0 "OK" 1 "FAULT";
VAL_ 1826 06_Board_Under_Temp_Fault 0 "OK" 1 "FAULT";
VAL_ 1826 07_Secondary_Contactor_Stuck_On_Fault 0 "OK" 1 "FAULT";
VAL_ 1826 08_Internal_Isolation_Fault 0 "OK" 1 "FAULT";
VAL_ 1826 09_External_Isolation_Fault 0 "OK" 1 "FAULT";
VAL_ 1826 10_Secondary_Contactor_A_Open_Fault 0 "OK" 1 "FAULT";
VAL_ 1826 11_Contactor_Precharge_Short_Fault 0 "OK" 1 "FAULT";
VAL_ 1826 12_Contactor_1_Dropout_Second_Fault 0 "OK" 1 "FAULT";
VAL_ 1826 13_Contactor_1_Dropout_First_Fault 0 "OK" 1 "FAULT";
VAL_ 1826 14_Contactor_Precharge_Retry_Fault 0 "OK" 1 "FAULT";
VAL_ 1826 15_Contactor_Precharge_Timeout_Fault 0 "OK" 1 "FAULT";
VAL_ 1826 16_Redundant_Cell_Voltage_Comparison_Fault 0 "OK" 1 "FAULT";
VAL_ 1826 17_Contactor_2_Stuck_On_Fault 0 "OK" 1 "FAULT";
VAL_ 1826 18_No_Charge_Current_Fault 0 "OK" 1 "FAULT";
VAL_ 1826 19_Board_Over_Temp_Fault 0 "OK" 1 "FAULT";
VAL_ 1826 20_Pack_Under_Temp_Fault 0 "OK" 1 "FAULT";
VAL_ 1826 21_Pack_Over_Temp_Fault 0 "OK" 1 "FAULT";
VAL_ 1826 22_Fan_Current_Low_Fault 0 "OK" 1 "FAULT";
VAL_ 1826 23_Fan_Current_High_Fault 0 "OK" 1 "FAULT";
VAL_ 1826 24_Module_Volt_To_Cell_Volt_Comparison_Fault 0 "OK" 1 "FAULT";
VAL_ 1826 25_Contactor_1_Stuck_On_Fault 0 "OK" 1 "FAULT";
VAL_ 1826 26_Cell_Under_Voltage_B_Fault 0 "OK" 1 "FAULT";
VAL_ 1826 27_Cell_Under_Voltage_A_Fault 0 "OK" 1 "FAULT";
VAL_ 1826 28_Cell_Over_Voltage_B_Fault 0 "OK" 1 "FAULT";
VAL_ 1826 29_Cell_Over_Voltage_A_Fault 0 "OK" 1 "FAULT";
VAL_ 1826 30_Pack_Over_Voltge_Fault 0 "OK" 1 "FAULT";
VAL_ 1826 31_SPI_Timeout_Fault 0 "OK" 1 "FAULT";
VAL_ 1826 32_Countactor_2_Dropout_2nd_Fault 0 "OK" 1 "FAULT";
VAL_ 1826 33_Countactor_2_Dropout_1st_Fault 0 "OK" 1 "FAULT";
VAL_ 1826 34_Countactor_1_Dropout_2nd_Fault 0 "OK" 1 "FAULT";
VAL_ 1826 35_Countactor_1_Dropout_1st_Fault 0 "OK" 1 "FAULT";
VAL_ 1826 36_Secondary_Contactor_B_Open_Fault 0 "OK" 1 "FAULT";
VAL_ 1826 37_No_PCU_Data_Received_Fault 0 "OK" 1 "FAULT";
VAL_ 1826 38_Pack_Over_Current_Regulation_Fault 0 "OK" 1 "FAULT";
VAL_ 1826 39_In_12V_Under_Voltage_Fault 0 "OK" 1 "FAULT";
VAL_ 1826 40_Low_Level_Discharge_During_Charge_Fault 0 "OK" 1 "FAULT";
VAL_ 1826 41_High_Level_Discharge_During_Charge_Fault 0 "OK" 1 "FAULT";
VAL_ 1826 42_Internal_Slave_No_Data_Fault 0 "OK" 1 "FAULT";
VAL_ 1826 43_Voltages_Mismach_Fault 0 "OK" 1 "FAULT";
VAL_ 1826 44_In_12V_Under_Voltage_Warning 0 "OK" 1 "FAULT";
VAL_ 1826 45_High_Contactor_Coil_Current_Fault 0 "OK" 1 "FAULT";
VAL_ 1826 46_Cell_Voltage_Connection_Fault 0 "OK" 1 "FAULT";
VAL_ 1826 47_Extreme_Cell_Under_Voltage_Fault 0 "OK" 1 "FAULT";
VAL_ 1826 48_Low_Current_Sensor_Correlation_Fault 0 "OK" 1 "FAULT";
VAL_ 1826 49_High_Current_Sensor_Correlation_Fault 0 "OK" 1 "FAULT";
VAL_ 1826 50_Main_Contactor_Open_Timeout_Fault 0 "OK" 1 "FAULT";
VAL_ 1826 51_PTC_Heater_Fault 0 "OK" 1 "FAULT";
VAL_ 1826 52_Pack_Temperature_AD_Fault 0 "OK" 1 "FAULT";
VAL_ 1826 53_Low_Module_Voltage_Fault 0 "OK" 1 "FAULT";
VAL_ 1825 00_Bus_Voltage_AD_Fault 0 "OK" 1 "FAULT";
VAL_ 1825 01_Pack_Voltage_AD_Fault 0 "OK" 1 "FAULT";
VAL_ 1825 02_Pack_Current_B_hi_AD_Fault 0 "OK" 1 "FAULT";
VAL_ 1825 03_Pack_Current_B_lo_AD_Fault 0 "OK" 1 "FAULT";
VAL_ 1825 04_Pack_Current_A_hi_AD_Fault 0 "OK" 1 "FAULT";
VAL_ 1825 05_Pack_Current_A_lo_AD_Fault 0 "OK" 1 "FAULT";
VAL_ 1825 06_Board_Under_Temp_Fault 0 "OK" 1 "FAULT";
VAL_ 1825 07_Secondary_Contactor_Stuck_On_Fault 0 "OK" 1 "FAULT";
VAL_ 1825 08_Internal_Isolation_Fault 0 "OK" 1 "FAULT";
VAL_ 1825 09_External_Isolation_Fault 0 "OK" 1 "FAULT";
VAL_ 1825 10_Secondary_Contactor_A_Open_Fault 0 "OK" 1 "FAULT";
VAL_ 1825 11_Contactor_Precharge_Short_Fault 0 "OK" 1 "FAULT";
VAL_ 1825 12_Contactor_1_Dropout_Second_Fault 0 "OK" 1 "FAULT";
VAL_ 1825 13_Contactor_1_Dropout_First_Fault 0 "OK" 1 "FAULT";
VAL_ 1825 14_Contactor_Precharge_Retry_Fault 0 "OK" 1 "FAULT";
VAL_ 1825 15_Contactor_Precharge_Timeout_Fault 0 "OK" 1 "FAULT";
VAL_ 1825 16_Redundant_Cell_Voltage_Comparison_Fault 0 "OK" 1 "FAULT";
VAL_ 1825 17_Contactor_2_Stuck_On_Fault 0 "OK" 1 "FAULT";
VAL_ 1825 18_No_Charge_Current_Fault 0 "OK" 1 "FAULT";
VAL_ 1825 19_Board_Over_Temp_Fault 0 "OK" 1 "FAULT";
VAL_ 1825 20_Pack_Under_Temp_Fault 0 "OK" 1 "FAULT";
VAL_ 1825 21_Pack_Over_Temp_Fault 0 "OK" 1 "FAULT";
VAL_ 1825 22_Fan_Current_Low_Fault 0 "OK" 1 "FAULT";
VAL_ 1825 23_Fan_Current_High_Fault 0 "OK" 1 "FAULT";
VAL_ 1825 24_Module_Volt_To_Cell_Volt_Comparison_Fault 0 "OK" 1 "FAULT";
VAL_ 1825 25_Contactor_1_Stuck_On_Fault 0 "OK" 1 "FAULT";
VAL_ 1825 26_Cell_Under_Voltage_B_Fault 0 "OK" 1 "FAULT";
VAL_ 1825 27_Cell_Under_Voltage_A_Fault 0 "OK" 1 "FAULT";
VAL_ 1825 28_Cell_Over_Voltage_B_Fault 0 "OK" 1 "FAULT";
VAL_ 1825 29_Cell_Over_Voltage_A_Fault 0 "OK" 1 "FAULT";
VAL_ 1825 30_Pack_Over_Voltge_Fault 0 "OK" 1 "FAULT";
VAL_ 1825 31_SPI_Timeout_Fault 0 "OK" 1 "FAULT";
VAL_ 1825 32_Countactor_2_Dropout_2nd_Fault 0 "OK" 1 "FAULT";
VAL_ 1825 33_Countactor_2_Dropout_1st_Fault 0 "OK" 1 "FAULT";
VAL_ 1825 34_Countactor_1_Dropout_2nd_Fault 0 "OK" 1 "FAULT";
VAL_ 1825 35_Countactor_1_Dropout_1st_Fault 0 "OK" 1 "FAULT";
VAL_ 1825 36_Secondary_Contactor_B_Open_Fault 0 "OK" 1 "FAULT";
VAL_ 1825 37_No_PCU_Data_Received_Fault 0 "OK" 1 "FAULT";
VAL_ 1825 38_Pack_Over_Current_Regulation_Fault 0 "OK" 1 "FAULT";
VAL_ 1825 39_In_12V_Under_Voltage_Fault 0 "OK" 1 "FAULT";
VAL_ 1825 40_Low_Level_Discharge_During_Charge_Fault 0 "OK" 1 "FAULT";
VAL_ 1825 41_High_Level_Discharge_During_Charge_Fault 0 "OK" 1 "FAULT";
VAL_ 1825 42_Internal_Slave_No_Data_Fault 0 "OK" 1 "FAULT";
VAL_ 1825 43_Voltages_Mismach_Fault 0 "OK" 1 "FAULT";
VAL_ 1825 44_In_12V_Under_Voltage_Warning 0 "OK" 1 "FAULT";
VAL_ 1825 45_High_Contactor_Coil_Current_Fault 0 "OK" 1 "FAULT";
VAL_ 1825 46_Cell_Voltage_Connection_Fault 0 "OK" 1 "FAULT";
VAL_ 1825 47_Extreme_Cell_Under_Voltage_Fault 0 "OK" 1 "FAULT";
VAL_ 1825 48_Low_Current_Sensor_Correlation_Fault 0 "OK" 1 "FAULT";
VAL_ 1825 49_High_Current_Sensor_Correlation_Fault 0 "OK" 1 "FAULT";
VAL_ 1825 50_Main_Contactor_Open_Timeout_Fault 0 "OK" 1 "FAULT";
VAL_ 1825 51_PTC_Heater_Fault 0 "OK" 1 "FAULT";
VAL_ 1825 52_Pack_Temperature_AD_Fault 0 "OK" 1 "FAULT";
VAL_ 1825 53_Low_Module_Voltage_Fault 0 "OK" 1 "FAULT";
